VERSION ""

NS_ :

BS_:

BU_: VIU_FL AMP EDC VIU_FR TBOX IP EVCC ICDC Vector__XXX

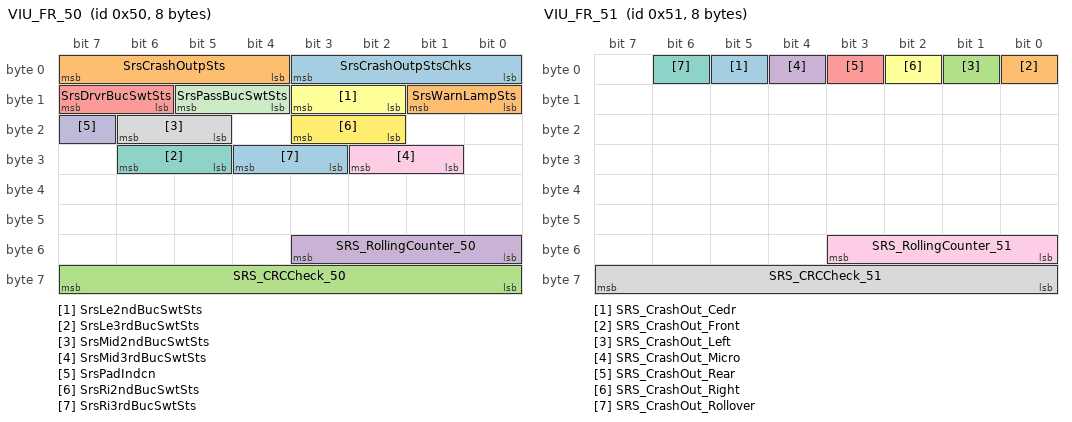
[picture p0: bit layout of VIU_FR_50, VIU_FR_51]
BO_ 80 VIU_FR_50: 8 VIU_FR
 SG_ SrsCrashOutpStsChks : 3|4@0+ (1,0) [0|15] "" EDC,TBOX
 SG_ SrsCrashOutpSts : 7|4@0+ (1,0) [0|15] "" TBOX,EDC
 SG_ SRS_CRCCheck_50 : 63|8@0+ (1,0) [0|255] "" EDC,TBOX
 SG_ SRS_RollingCounter_50 : 51|4@0+ (1,0) [0|15] "" EDC,TBOX
 SG_ SrsDrvrBucSwtSts : 15|2@0+ (1,0) [0|3] "" AMP,EDC,TBOX,IP
 SG_ SrsLe2ndBucSwtSts : 11|2@0+ (1,0) [0|3] "" AMP,EDC,TBOX,IP
 SG_ SrsLe3rdBucSwtSts : 30|2@0+ (1,0) [0|3] "" AMP,EDC,TBOX
 SG_ SrsMid2ndBucSwtSts : 22|2@0+ (1,0) [0|3] "" AMP,EDC,TBOX,IP
 SG_ SrsMid3rdBucSwtSts : 26|2@0+ (1,0) [0|3] "" AMP,EDC,TBOX
 SG_ SrsPadIndcn : 23|1@0+ (1,0) [0|1] "" EDC,TBOX
 SG_ SrsPassBucSwtSts : 13|2@0+ (1,0) [0|3] "" AMP,EDC,TBOX,IP
 SG_ SrsRi2ndBucSwtSts : 19|2@0+ (1,0) [0|3] "" AMP,EDC,TBOX,IP
 SG_ SrsRi3rdBucSwtSts : 28|2@0+ (1,0) [0|3] "" AMP,EDC,TBOX
 SG_ SrsWarnLampSts : 9|2@0+ (1,0) [0|3] "" TBOX,EDC,IP

BO_ 81 VIU_FR_51: 8 VIU_FR
 SG_ SRS_CrashOut_Cedr : 5|1@0+ (1,0) [0|1] "" EDC,TBOX
 SG_ SRS_CrashOut_Front : 0|1@0+ (1,0) [0|1] "" EDC,TBOX
 SG_ SRS_CrashOut_Left : 1|1@0+ (1,0) [0|1] "" EDC,TBOX
 SG_ SRS_CrashOut_Micro : 4|1@0+ (1,0) [0|1] "" EDC,TBOX
 SG_ SRS_CrashOut_Rear : 3|1@0+ (1,0) [0|1] "" EDC,TBOX
 SG_ SRS_CrashOut_Right : 2|1@0+ (1,0) [0|1] "" EDC,TBOX
 SG_ SRS_CrashOut_Rollover : 6|1@0+ (1,0) [0|1] "" EDC,TBOX
 SG_ SRS_CRCCheck_51 : 63|8@0+ (1,0) [0|255] "" EDC,TBOX
 SG_ SRS_RollingCounter_51 : 51|4@0+ (1,0) [0|15] "" EDC,TBOX

BO_ 338 VIU_FL_152: 64 VIU_FL
 SG_ AD_Reqmode : 89|2@0+ (1,0) [0|3] "" Vector__XXX
 SG_ AD_ACCMode : 54|3@0+ (1,0) [0|7] "" EDC,IP
 SG_ AD_AEBActive : 87|1@0+ (1,0) [0|1] "" Vector__XXX
 SG_ AD_CRCCheck_152 : 439|16@0+ (1,0) [0|65535] "" EDC
 SG_ AD_DynamicWarningLevel : 178|3@0+ (1,0) [0|7] "" EDC
 SG_ AD_ESSActive : 186|3@0+ (1,0) [0|7] "" EDC
 SG_ AD_ESSStatus : 28|3@0+ (1,0) [0|7] "" EDC
 SG_ AD_ESSWarning : 189|3@0+ (1,0) [0|7] "" EDC
 SG_ AD_FCTBActive : 37|2@0+ (1,0) [0|3] "" EDC
 SG_ AD_LatAngReq : 165|14@0+ (0.1,-720) [-720|720] "degree" Vector__XXX
 SG_ AD_LatAngReqActive : 155|1@0+ (1,0) [0|1] "" Vector__XXX
 SG_ AD_LDWinhaitwaring : 30|2@0+ (1,0) [0|3] "" EDC
 SG_ AD_LKAinhaitWarning : 93|2@0+ (1,0) [0|3] "" EDC
 SG_ AD_LKAStatus : 250|3@0+ (1,0) [0|7] "" Vector__XXX
 SG_ AD_REBStatus : 12|3@0+ (1,0) [0|7] "" EDC
 SG_ AD_RollingCounter_152 : 427|4@0+ (1,0) [0|15] "" EDC
 SG_ AD_RunRedLightWaring : 47|2@0+ (1,0) [0|3] "" EDC
 SG_ AD_SafetyNotice : 263|8@0+ (1,0) [0|255] "" EDC
 SG_ ADC_SenceMode : 131|2@0+ (1,0) [0|3] "" Vector__XXX
 SG_ AEB_AWBActive : 95|1@0+ (1,0) [0|1] "" Vector__XXX
 SG_ AD_C2Currenttemp : 151|8@0+ (1,-40) [-40|215] "" VIU_FR
 SG_ AD_FlowReq : 23|8@0+ (1,0) [0|100] "" VIU_FR
 SG_ AD_FlowReqValid : 128|1@0+ (1,0) [0|1] "" VIU_FR
 SG_ AD_TmstempReq : 143|8@0+ (1,-40) [-40|215] "" VIU_FR
 SG_ AD_TmstempReqValid : 129|1@0+ (1,0) [0|1] "" VIU_FR
 SG_ ADR_TriggerEventReq : 303|6@0+ (1,0) [0|63] "" VIU_FR

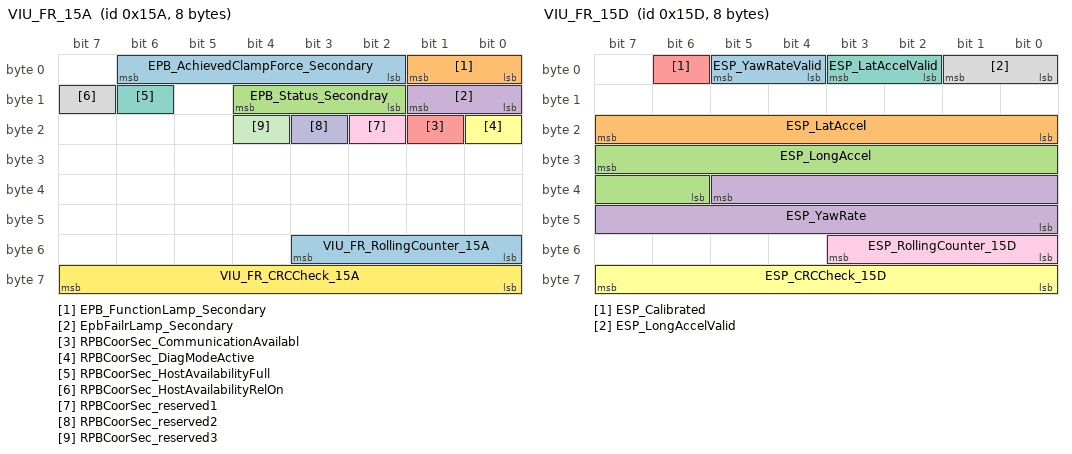
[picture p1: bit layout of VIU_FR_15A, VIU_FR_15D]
BO_ 346 VIU_FR_15A: 8 VIU_FR
 SG_ EPB_AchievedClampForce_Secondary : 6|5@0+ (1,0) [0|31] "KN" EDC
 SG_ EPB_FunctionLamp_Secondary : 1|2@0+ (1,0) [0|3] "" EDC
 SG_ EPB_Status_Secondray : 12|3@0+ (1,0) [0|7] "" EDC
 SG_ EpbFailrLamp_Secondary : 9|2@0+ (1,0) [0|3] "" EDC
 SG_ RPBCoorSec_CommunicationAvailabl : 17|1@0+ (1,0) [0|1] "bool" EDC
 SG_ RPBCoorSec_DiagModeActive : 16|1@0+ (1,0) [0|1] "bool" EDC
 SG_ RPBCoorSec_HostAvailabilityFull : 14|1@0+ (1,0) [0|1] "bool" EDC
 SG_ RPBCoorSec_HostAvailabilityRelOn : 15|1@0+ (1,0) [0|1] "bool" EDC
 SG_ RPBCoorSec_reserved1 : 18|1@0+ (1,0) [0|1] "bool" EDC
 SG_ RPBCoorSec_reserved2 : 19|1@0+ (1,0) [0|1] "bool" EDC
 SG_ RPBCoorSec_reserved3 : 20|1@0+ (1,0) [0|1] "bool" EDC
 SG_ VIU_FR_CRCCheck_15A : 63|8@0+ (1,0) [0|255] "" EDC
 SG_ VIU_FR_RollingCounter_15A : 51|4@0+ (1,0) [0|15] "" EDC

BO_ 349 VIU_FR_15D: 8 VIU_FR
 SG_ ESP_YawRateValid : 5|2@0+ (1,0) [0|3] "" TBOX,EDC
 SG_ ESP_LatAccel : 23|8@0+ (0.1,-12.7) [-12.7|12.7] "m/s2" TBOX,EDC
 SG_ ESP_LongAccel : 31|10@0+ (0.03125,-16) [-16|15.90625] "m/s2" TBOX,EDC
 SG_ ESP_YawRate : 37|14@0+ (0.01,-81.91) [-81.91|81.91] "degree/s" TBOX,EDC
 SG_ ESP_Calibrated : 6|1@0+ (1,0) [0|1] "" Vector__XXX
 SG_ ESP_CRCCheck_15D : 63|8@0+ (1,0) [0|255] "" Vector__XXX
 SG_ ESP_LatAccelValid : 3|2@0+ (1,0) [0|3] "" Vector__XXX
 SG_ ESP_LongAccelValid : 1|2@0+ (1,0) [0|3] "" Vector__XXX
 SG_ ESP_RollingCounter_15D : 51|4@0+ (1,0) [0|15] "" Vector__XXX

BO_ 353 VIU_FL_161: 32 VIU_FL
 SG_ ESPVehSpd_Reference : 68|13@0+ (0.05625,0) [0|360] "km/h" Vector__XXX
 SG_ ESP_ABAactive : 6|1@0+ (1,0) [0|1] "" TBOX,EDC
 SG_ ESP_ABAavailable : 5|1@0+ (1,0) [0|1] "" TBOX,EDC
 SG_ ESP_AEBAvailable : 2|1@0+ (1,0) [0|1] "" TBOX,EDC
 SG_ ESP_AEBdecActive : 1|1@0+ (1,0) [0|1] "" TBOX,EDC
 SG_ ESP_PrefillActive : 4|1@0+ (1,0) [0|1] "" Vector__XXX
 SG_ ESP_PrefillAvailable : 3|1@0+ (1,0) [0|1] "" Vector__XXX
 SG_ IBCU_BrakeDiscOverHeat : 14|1@0+ (1,0) [0|1] "" Vector__XXX
 SG_ IBCU_BrakeForce : 7|1@0+ (1,0) [0|1] "" Vector__XXX
 SG_ IBCU_CRCCheck_161 : 247|16@0+ (1,0) [0|65535] "" Vector__XXX
 SG_ IBCU_QDCSts : 49|2@0+ (1,0) [0|3] "" Vector__XXX
 SG_ IBCU_RollingCounter_161 : 235|4@0+ (1,0) [0|15] "" Vector__XXX

BO_ 355 VIU_FL_163: 64 VIU_FL
 SG_ DMF_BrkForceTarDecActv : 131|1@0+ (1,0) [0|1] "" Vector__XXX
 SG_ DMF_CrbsFailrSts : 357|1@0+ (1,0) [0|1] "" Vector__XXX
 SG_ DMF_BrkForceTarDec : 143|16@0+ (1,-65535) [-65535|0] "" Vector__XXX
 SG_ DMF_VehTarForceReqMod : 262|2@0+ (1,0) [0|3] "" Vector__XXX
 SG_ DMF_LeFrntTarBrkForceMod : 265|2@0+ (1,0) [0|3] "" Vector__XXX
 SG_ DMF_RiFrntTarBrkForceMod : 267|2@0+ (1,0) [0|3] "" Vector__XXX
 SG_ DMF_LeReTarBrkForceMod : 269|2@0+ (1,0) [0|3] "" Vector__XXX
 SG_ DMF_RiReTarBrkForceMod : 271|2@0+ (1,0) [0|3] "" Vector__XXX
 SG_ DMF_VehTarBrkForce : 279|16@0+ (1,-65535) [-65535|0] "" Vector__XXX
 SG_ DMF_LeFrntTarBrkForce : 295|16@0+ (1,-65535) [-65535|0] "" Vector__XXX
 SG_ DMF_RiFrntTarBrkForce : 311|16@0+ (1,-65535) [-65535|0] "" Vector__XXX
 SG_ DMF_LeReTarBrkForce : 327|16@0+ (1,-65535) [-65535|0] "" Vector__XXX
 SG_ DMF_RiReTarBrkForce : 343|16@0+ (1,-65535) [-65535|0] "" Vector__XXX
 SG_ DMF_MainAdasSts : 43|1@0+ (1,0) [0|1] "" Vector__XXX
 SG_ DMF_EscFctSts : 134|3@0+ (1,0) [1|7] "" Vector__XXX
 SG_ DMF_PrefillActvReq : 260|1@0+ (1,0) [0|1] "" Vector__XXX
 SG_ DMF_ReWhlDecTarTqActv : 28|1@0+ (1,0) [0|1] "" Vector__XXX
 SG_ DMF_ReWhlDecTarTq : 27|16@0+ (1,-32768) [-32768|32767] "Nm" Vector__XXX
 SG_ DMF_ReWhlIncTarTqActv : 13|1@0+ (1,0) [0|1] "" Vector__XXX
 SG_ DMF_ReWhlIncTarTq : 12|16@0+ (1,-32768) [-32768|32767] "Nm" Vector__XXX
 SG_ DMF_FrntWhlDecTarTqActv : 0|1@0+ (1,0) [0|1] "" Vector__XXX
 SG_ DMF_FrntWhlDecTarTq : 71|16@0+ (1,-32768) [-32768|32767] "Nm" Vector__XXX
 SG_ DMF_FrntWhlIncTarTqActv : 1|1@0+ (1,0) [0|1] "" Vector__XXX
 SG_ DMF_FrntWhlIncTarTq : 87|16@0+ (1,-32768) [-32768|32767] "Nm" Vector__XXX
 SG_ DMF_LeFrntWhlIncTarTqActv : 2|1@0+ (1,0) [0|1] "" Vector__XXX
 SG_ DMF_LeFrntWhlIncTarTq : 103|16@0+ (1,-32768) [-32768|32767] "Nm" Vector__XXX
 SG_ DMF_RiFrntWhlIncTarTqActv : 3|1@0+ (1,0) [0|1] "" Vector__XXX
 SG_ DMF_RiFrntWhlIncTarTq : 119|16@0+ (1,-32768) [-32768|32767] "Nm" Vector__XXX
 SG_ DMF_LeReWhlIncTarTqActv : 4|1@0+ (1,0) [0|1] "" Vector__XXX
 SG_ DMF_LeReWhlIncTarTq : 159|16@0+ (1,-32768) [-32768|32767] "Nm" Vector__XXX
 SG_ DMF_RiReWhlIncTarTqActv : 5|1@0+ (1,0) [0|1] "" Vector__XXX
 SG_ DMF_RiReWhlIncTarTq : 175|16@0+ (1,-32768) [-32768|32767] "Nm" Vector__XXX
 SG_ DMF_LeFrntWhlDecTarTqActv : 6|1@0+ (1,0) [0|1] "" Vector__XXX
 SG_ DMF_LeFrntWhlDecTarTq : 191|16@0+ (1,-32768) [-32768|32767] "Nm" Vector__XXX
 SG_ DMF_RiFrntWhlDecTarTqActv : 7|1@0+ (1,0) [0|1] "" Vector__XXX
 SG_ DMF_RiFrntWhlDecTarTq : 207|16@0+ (1,-32768) [-32768|32767] "Nm" Vector__XXX
 SG_ DMF_LeReWhlDecTarTqActv : 14|1@0+ (1,0) [0|1] "" Vector__XXX
 SG_ DMF_LeReWhlDecTarTq : 223|16@0+ (1,-32768) [-32768|32767] "Nm" Vector__XXX
 SG_ DMF_RiReWhlDecTarTqActv : 15|1@0+ (1,0) [0|1] "" Vector__XXX
 SG_ DMF_RiReWhlDecTarTq : 239|16@0+ (1,-32768) [-32768|32767] "Nm" Vector__XXX
 SG_ DMF_ADReqmode : 250|2@0+ (1,0) [0|3] "" Vector__XXX
 SG_ DMF_ADDriverlessReq : 256|1@0+ (1,0) [0|1] "" Vector__XXX
 SG_ DMF_ADAbaRankReq : 359|2@0+ (1,0) [0|3] "" Vector__XXX
 SG_ DMF_ADAbaRankReqVld : 248|1@0+ (1,0) [0|1] "" Vector__XXX
 SG_ DMF_ADSystemSts : 252|2@0+ (1,0) [0|3] "" Vector__XXX
 SG_ DMF_ADFctOpenSts : 259|2@0+ (1,0) [0|3] "" Vector__XXX
 SG_ DmfEscReqRwsActv : 472|1@0+ (1,0) [0|1] "" Vector__XXX
 SG_ DmfEscRwsAgTar : 42|12@0+ (0.01,-15) [-15|15] "deg" Vector__XXX
 SG_ DmfDstwWhlAgOff : 452|8@0+ (0.1,-10) [-10|10] "deg" Vector__XXX
 SG_ DmfDstwActvSts : 467|1@0+ (1,0) [0|1] "" Vector__XXX
 SG_ DmfFrntWhlAg : 356|10@0+ (0.1,-45) [-45|45] "deg" Vector__XXX
 SG_ DmfLgtSlopEst : 466|10@0+ (0.01,-3) [-3|3] "m/ss" Vector__XXX
 SG_ DmfMueEstFil : 409|5@0+ (0.05,0) [0|1.5] "" Vector__XXX
 SG_ Dmf_RollingCounter_163 : 491|4@0+ (1,0) [0|15] "" Vector__XXX
 SG_ Dmf_CRCCheck_163 : 503|16@0+ (1,0) [0|65535] "" Vector__XXX

BO_ 359 VIU_FL_167: 64 VIU_FL
 SG_ EmsEngSpd : 23|16@0+ (0.25,0) [0|16383.75] "rpm" EDC
 SG_ EmsEngCoolanT : 143|8@0+ (0.75,-48) [-48|142.5] "℃" IP
 SG_ EmsCoolanTErr : 122|1@0+ (1,0) [0|1] "" IP

BO_ 378 VIU_FL_17A: 64 VIU_FL
 SG_ IbBrkPedlStsGb : 199|8@0+ (1,0) [0|255] "%" TBOX
 SG_ IbBrkPedlStsGbVld : 201|2@0+ (1,0) [0|2] "" TBOX
 SG_ IbBrkPedlTrvlDrvr : 239|12@0+ (0.015625,-5) [-5|47] "mm" TBOX
 SG_ IbBrkPedlTrvlDrvrVld : 217|2@0+ (1,0) [0|2] "" TBOX
 SG_ ESP_pMcVirtual : 243|12@0+ (0.1,0) [0|250] "bar" Vector__XXX
 SG_ IBCU_PlungerBrakePressure : 19|12@0+ (0.1,0) [0|250] "bar" Vector__XXX
 SG_ IBCU_PlungerBrakePressureValid : 39|1@0+ (1,0) [0|1] "" Vector__XXX

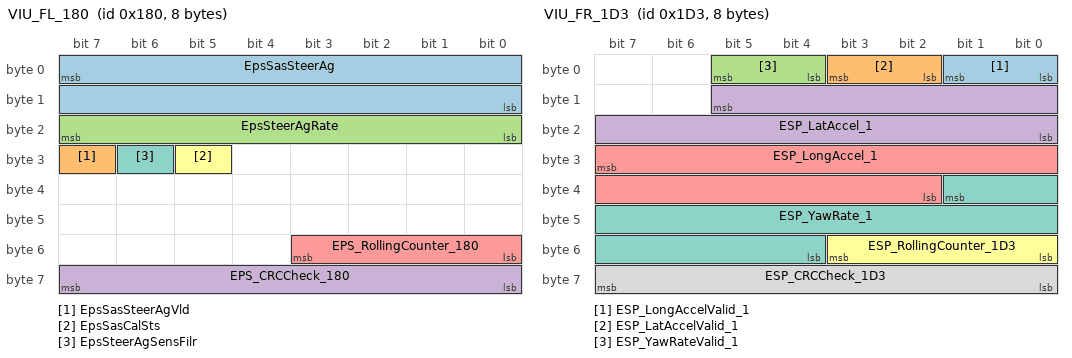
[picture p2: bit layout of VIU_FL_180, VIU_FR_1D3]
BO_ 384 VIU_FL_180: 8 VIU_FL
 SG_ EpsSasSteerAg : 7|16@0- (0.1,0) [-780|780] "degree" TBOX
 SG_ EpsSasSteerAgVld : 31|1@0+ (1,0) [0|1] "" TBOX
 SG_ EpsSteerAgRate : 23|8@0+ (4,0) [0|1016] "deg/s" Vector__XXX
 SG_ EPS_CRCCheck_180 : 63|8@0+ (1,0) [0|255] "" Vector__XXX
 SG_ EPS_RollingCounter_180 : 51|4@0+ (1,0) [0|15] "" Vector__XXX
 SG_ EpsSasCalSts : 29|1@0+ (1,0) [0|1] "" Vector__XXX
 SG_ EpsSteerAgSensFilr : 30|1@0+ (1,0) [0|1] "" Vector__XXX

BO_ 417 VIU_FL_1A1: 64 VIU_FL
 SG_ VcuChrglockPosn2 : 402|1@0+ (1,0) [0|1] "" EVCC
 SG_ VcuChrglockPosn1 : 403|1@0+ (1,0) [0|1] "" EVCC

BO_ 419 VIU_FL_1A3: 64 VIU_FL
 SG_ FrntMotSpd : 7|16@0+ (1,-20000) [-20000|45535] "rpm" EDC,AMP
 SG_ FrntMotTqGb : 319|16@0+ (0.1,-2000) [-2000|4553.5] "Nm" EDC,AMP
 SG_ FrntMotSpdVld : 34|1@0+ (1,0) [0|1] "" EDC
 SG_ FrntMotTq : 23|14@0+ (0.1,-800) [-800|838.3] "Nm" EDC,AMP
 SG_ FrntMotTqVld : 33|1@0+ (1,0) [0|1] "" EDC,AMP

BO_ 420 VIU_FL_1A4: 64 VIU_FL
 SG_ ReMotSpd : 7|16@0+ (1,-20000) [-20000|45535] "rpm" EDC,AMP
 SG_ ReMotSpdVld : 34|1@0+ (1,0) [0|1] "" EDC,AMP
 SG_ ReMotTq : 23|14@0+ (0.1,-800) [-800|838.3] "Nm" EDC,AMP
 SG_ ReMotTqVld : 33|1@0+ (1,0) [0|1] "" EDC,AMP

BO_ 421 VIU_FL_1A5: 64 VIU_FL
 SG_ BcuChrgMod : 217|4@0+ (1,0) [0|15] "" EVCC

BO_ 433 VIU_FL_1B1: 64 VIU_FL
 SG_ PwrTrainSts : 311|2@0+ (1,0) [0|3] "" Vector__XXX
 SG_ VcuRdySts : 7|1@0+ (1,0) [0|1] "" IP,EDC
 SG_ VcuGearPosn : 5|3@0+ (1,0) [0|7] "" TBOX,EDC,AMP,EVCC
 SG_ VcuVehGearPosnVld : 2|1@0+ (1,0) [0|1] "" TBOX,EDC,AMP,IP,EVCC
 SG_ AcChrgHvActvReq : 359|3@0+ (1,0) [0|7] "NA" Vector__XXX
 SG_ DcAcHvActvReq : 355|3@0+ (1,0) [0|7] "NA" Vector__XXX
 SG_ DcChrgHvActvReq : 370|3@0+ (1,0) [0|7] "NA" Vector__XXX
 SG_ OTAHvActvReq : 365|3@0+ (1,0) [0|7] "NA" Vector__XXX
 SG_ SrvAllwblReqSts : 352|3@0+ (1,0) [0|7] "NA" Vector__XXX
 SG_ VcuHvSysErrNr : 362|8@0+ (1,0) [0|255] "NA" Vector__XXX
 SG_ VehHvActvReq : 347|3@0+ (1,0) [0|7] "NA" Vector__XXX
 SG_ BrkgRgnMaxWhl : 271|16@0+ (1,-32768) [-32768|32767] "Nm" Vector__XXX
 SG_ BrkgRgnMaxWhlVldSts : 285|2@0+ (1,0) [0|2] "" Vector__XXX
 SG_ LePresSw : 177|3@0+ (1,0) [0|7] "" Vector__XXX
 SG_ ReMotSpd : 167|16@0+ (1,-20000) [-20000|45535] "rpm" Vector__XXX
 SG_ ReMotSpdVld : 182|1@0+ (1,0) [0|1] "" Vector__XXX
 SG_ RiPresSw : 190|3@0+ (1,0) [0|7] "" EDC
 SG_ VCU_CRCCheck_1B1 : 439|16@0+ (1,0) [0|65535] "" Vector__XXX
 SG_ VCU_RollingCounter_1B1 : 427|4@0+ (1,0) [0|15] "" Vector__XXX
 SG_ VCUAccPedShield : 50|1@0+ (1,0) [0|1] "" Vector__XXX
 SG_ VcuAccrMod : 199|4@0+ (1,0) [0|15] "" IP
 SG_ VcuAccrPedlPosn : 195|10@0+ (0.1,0) [0|102.3] "%" AMP,EDC
 SG_ VcuAccrPedlPosnVld : 216|1@0+ (1,0) [0|1] "" AMP
 SG_ VCUAPAdriverInterruption : 49|2@0+ (1,0) [0|3] "" Vector__XXX
 SG_ VCUAPARequestEnable : 57|2@0+ (1,0) [0|3] "" Vector__XXX
 SG_ VcuCalcnAccrPedlPosn : 201|10@0+ (0.1,0) [0|102.3] "%" Vector__XXX
 SG_ VcuCalcnAccrPedlPosnVld : 217|1@0+ (1,0) [0|1] "" Vector__XXX
 SG_ VcuComFltSts : 1|2@0+ (1,0) [0|3] "" Vector__XXX
 SG_ VcuCrpFctSts : 241|2@0+ (1,0) [0|3] "" Vector__XXX
 SG_ VcuDecToStopReq : 238|1@0+ (1,0) [0|1] "" Vector__XXX
 SG_ VcuDrvrGearDmd : 180|3@0+ (1,0) [0|7] "" Vector__XXX
 SG_ VcuEnyRecyclMod : 283|7@0+ (1,0) [0|127] "" Vector__XXX
 SG_ VcuEpbReq : 223|2@0+ (1,0) [0|3] "" Vector__XXX
 SG_ VcuEpbReqVld : 224|1@0+ (1,0) [0|1] "" Vector__XXX
 SG_ VcuFrntMotSpd : 151|16@0+ (1,-20000) [-20000|45535] "rpm" Vector__XXX
 SG_ VcuFrntMotSpdVld : 184|1@0+ (1,0) [0|1] "" Vector__XXX
 SG_ VcuFrntWhlActTq : 23|16@0+ (1,-32768) [-32768|32767] "Nm" Vector__XXX
 SG_ VcuFrntWhlActTqVld : 8|1@0+ (1,0) [0|1] "" Vector__XXX
 SG_ VcuFrntWhlReqTq : 71|16@0+ (1,-32768) [-32768|32767] "Nm" Vector__XXX
 SG_ VcuFrntWhlReqTqVld : 11|1@0+ (1,0) [0|1] "" Vector__XXX
 SG_ VcuMbRgnWhl : 255|16@0+ (1,-32768) [-32768|32767] "Nm" Vector__XXX
 SG_ VcuMbRgnWhlVldSts : 287|2@0+ (1,0) [0|2] "" Vector__XXX
 SG_ VcuObdType : 239|1@0+ (1,0) [0|1] "" Vector__XXX
 SG_ VcuOvrdModReq : 6|1@0+ (1,0) [0|1] "" Vector__XXX
 SG_ VcuPmuSleepReq : 53|1@0+ (1,0) [0|1] "" Vector__XXX
 SG_ VcuPmuSwtCloseAllowFlg : 55|1@0+ (1,0) [0|1] "" Vector__XXX
 SG_ VcuPtCoastRegenReqTq : 135|16@0+ (1,-32768) [-32768|32767] "Nm" Vector__XXX
 SG_ VcuPtCoastRegenReqTqVld : 15|1@0+ (1,0) [0|1] "" Vector__XXX
 SG_ VcuPtTqLimMax : 119|16@0+ (1,-32768) [-32768|32767] "Nm" Vector__XXX
 SG_ VcuPtTqLimMaxVld : 14|1@0+ (1,0) [0|1] "" Vector__XXX
 SG_ VcuPtTqLimMin : 103|16@0+ (1,-32768) [-32768|32767] "Nm" Vector__XXX
 SG_ VcuPtTqLimMinVld : 13|1@0+ (1,0) [0|1] "" Vector__XXX
 SG_ VcuPtTqReal : 323|16@0+ (1,-32768) [-32768|32767] "Nm" Vector__XXX
 SG_ VcuPtTqRealVld : 308|1@0+ (1,0) [0|1] "" Vector__XXX
 SG_ VcuPtTqReqAvl : 52|2@0+ (1,0) [0|3] "" Vector__XXX
 SG_ VcuReWhlActTq : 39|16@0+ (1,-32768) [-32768|32767] "Nm" Vector__XXX
 SG_ VcuReWhlActTqVld : 9|1@0+ (1,0) [0|1] "" Vector__XXX
 SG_ VcuReWhlReqTq : 87|16@0+ (1,-32768) [-32768|32767] "Nm" Vector__XXX
 SG_ VcuReWhlReqTqVld : 12|1@0+ (1,0) [0|1] "" Vector__XXX
 SG_ VcuSimnEpbSwtSts : 233|2@0+ (1,0) [0|3] "" Vector__XXX
 SG_ VcuSimnEpbSwtStsVld : 234|1@0+ (1,0) [0|1] "" Vector__XXX
 SG_ VcuTarGearPosn : 237|3@0+ (1,0) [0|7] "" Vector__XXX
 SG_ VcuTrlrModActvSts : 243|2@0+ (1,0) [0|3] "" Vector__XXX
 SG_ VcuVechicleType : 245|2@0+ (1,0) [0|3] "" Vector__XXX
 SG_ VcuVehWhlReqTq : 307|16@0+ (1,-32768) [-32768|32767] "Nm" Vector__XXX
 SG_ VcuVehWhlReqTqVld : 309|1@0+ (1,0) [0|1] "" Vector__XXX

BO_ 450 VIU_FL_1C2: 64 VIU_FL
 SG_ EspAbsActv : 72|1@0+ (1,0) [0|1] "" TBOX,IP,VIU_FR
 SG_ EspAbsFailr : 73|1@0+ (1,0) [0|1] "" TBOX,IP
 SG_ EspActvSts : 55|1@0+ (1,0) [0|1] "" TBOX,IP
 SG_ EspFctOpenSts : 54|1@0+ (1,0) [0|1] "" TBOX,IP
 SG_ EspTcsActvSts : 52|1@0+ (1,0) [0|1] "" TBOX,IP
 SG_ EspTcsFailr : 53|1@0+ (1,0) [0|1] "" TBOX,IP
 SG_ EspVehSpd : 100|13@0+ (0.05625,0) [0|460.74375] "km/h" EDC,TBOX,AMP,IP,EVCC
 SG_ EspVehSpdVld : 101|1@0+ (1,0) [0|1] "" EDC,TBOX,AMP,IP,EVCC
 SG_ EspDrvrBrkReqTq : 319|16@0+ (1,-32768) [-32768|32767] "Nm" Vector__XXX
 SG_ ESP_CRCCheck_1C2 : 439|16@0+ (1,0) [0|65535] "" Vector__XXX
 SG_ ESP_RollingCounter_1C2 : 427|4@0+ (1,0) [0|15] "" Vector__XXX
 SG_ EspEbdFailr : 36|1@0+ (1,0) [0|1] "" IP
 SG_ EspHDCSts : 365|2@0+ (1,0) [0|3] "" IP
 SG_ EspVdcActvSts : 414|1@0+ (1,0) [0|1] "" IP
 SG_ EspVehStandstill : 351|1@0+ (1,0) [0|1] "" Vector__XXX
 SG_ IBCU_BrakeFluid_Warning : 6|2@0+ (1,0) [0|3] "" Vector__XXX
 SG_ MCBActv : 103|1@0+ (1,0) [0|1] "" EDC
 SG_ MCBAvl : 102|1@0+ (1,0) [0|1] "" EDC
 SG_ WhlSpdFrntLePls : 63|8@0+ (1,0) [0|254] "" Vector__XXX
 SG_ WhlSpdFrntRiPls : 239|8@0+ (1,0) [0|254] "" Vector__XXX
 SG_ WhlSpdLeFrntData : 148|13@0+ (0.05625,0) [0|460.74375] "km/h" Vector__XXX
 SG_ WhlSpdLeFrntDataVld : 151|1@0+ (1,0) [0|1] "" Vector__XXX
 SG_ WhlSpdLeFrntDir : 150|2@0+ (1,0) [0|3] "" Vector__XXX
 SG_ WhlSpdLeReData : 20|13@0+ (0.05625,0) [0|460.74375] "km/h" Vector__XXX
 SG_ WhlSpdLeReDataVld : 23|1@0+ (1,0) [0|1] "" Vector__XXX
 SG_ WhlSpdLeReDir : 67|2@0+ (1,0) [0|3] "" Vector__XXX
 SG_ WhlSpdReLePls : 263|8@0+ (1,0) [0|254] "" Vector__XXX
 SG_ WhlSpdReRiPls : 407|8@0+ (1,0) [0|254] "" Vector__XXX
 SG_ WhlSpdRiFrntData : 132|13@0+ (0.05625,0) [0|460.74375] "km/h" Vector__XXX
 SG_ WhlSpdRiFrntDataVld : 135|1@0+ (1,0) [0|1] "" Vector__XXX
 SG_ WhlSpdRiFrntDir : 134|2@0+ (1,0) [0|3] "" Vector__XXX
 SG_ WhlSpdRiReData : 4|13@0+ (0.05625,0) [0|460.74375] "km/h" Vector__XXX
 SG_ WhlSpdRiReDataVld : 7|1@0+ (1,0) [0|1] "" Vector__XXX
 SG_ WhlSpdRiReDir : 65|2@0+ (1,0) [0|3] "" Vector__XXX
 SG_ EspAutoHoldActvSts : 353|2@0+ (1,0) [0|3] "" IP
 SG_ EspBrkSysFltLamp : 35|2@0+ (1,0) [0|3] "" IP
 SG_ IBCU_iDCSAvlblSts : 211|1@0+ (1,0) [0|1] "" EDC
 SG_ IBCU_iDCSLevFd : 210|3@0+ (1,0) [0|7] "" EDC
 SG_ IBCU_iDCS_State : 303|3@0+ (1,0) [0|7] "" EDC

BO_ 452 VIU_FL_1C4: 8 VIU_FL
 SG_ EMB_Pri_SystemFlt : 7|4@0+ (1,0) [0|15] "" VIU_FR
 SG_ EMB_Pri_BrkRodStrk : 3|12@0+ (0.03,0) [0|100] "mm" VIU_FR
 SG_ EMB_Pri_BrkRodStrkVld : 23|1@0+ (1,0) [0|1] "" VIU_FR
 SG_ EMB_RollingCounter_1C4 : 51|4@0+ (1,0) [0|15] "" VIU_FR
 SG_ EMB_CRCCheck__1C4 : 63|8@0+ (1,0) [0|255] "" VIU_FR
 SG_ EMBParkPriCtrlEnableRL : 22|1@0+ (1,0) [0|1] "" VIU_FR
 SG_ EMBParkPriCtrlEnableRR : 21|1@0+ (1,0) [0|1] "" VIU_FR
 SG_ EMBParkPriAvailabilityRL : 20|2@0+ (1,0) [0|3] "" VIU_FR
 SG_ EMBParkPriAvailabilityRR : 18|2@0+ (1,0) [0|3] "" VIU_FR
 SG_ EMBParkPriCtrlSourceRL : 16|4@0+ (1,0) [0|15] "" VIU_FR
 SG_ EMBParkPriCtrlSourceRR : 28|4@0+ (1,0) [0|15] "" VIU_FR
 SG_ EMBParkPriEpbStatusRL : 24|3@0+ (1,0) [0|7] "" VIU_FR
 SG_ EMBParkPriEpbStatusRR : 37|3@0+ (1,0) [0|7] "" VIU_FR
 SG_ EMBParkPriFctLampRL : 34|2@0+ (1,0) [0|3] "" VIU_FR
 SG_ EMBParkPriFctLampRR : 32|2@0+ (1,0) [0|3] "" VIU_FR
 SG_ EMBParkPriFailrLampRL : 46|2@0+ (1,0) [0|3] "" VIU_FR
 SG_ EMBParkPriFailrLampRR : 44|2@0+ (1,0) [0|3] "" VIU_FR
 SG_ EMBPriVehBrkSysSts : 42|3@0+ (1,0) [0|7] "" VIU_FR

BO_ 453 VIU_FR_1C5: 8 VIU_FR
 SG_ EMB_Sec_SystemFlt : 7|4@0+ (1,0) [0|15] "" VIU_FL
 SG_ EMB_Sec_BrkRodStrk : 3|12@0+ (0.03,0) [0|100] "mm" VIU_FL
 SG_ EMB_Sec_BrkRodStrkVld : 23|1@0+ (1,0) [0|1] "" VIU_FL
 SG_ EMB_RollingCounter_1C5 : 51|4@0+ (1,0) [0|15] "" VIU_FL
 SG_ EMB_CRCCheck__1C5 : 63|8@0+ (1,0) [0|255] "" VIU_FL
 SG_ EMBParkSecCtrlEnableRL : 22|1@0+ (1,0) [0|1] "" VIU_FL
 SG_ EMBParkSecCtrlEnableRR : 21|1@0+ (1,0) [0|1] "" VIU_FL
 SG_ EMBParkSecAvailabilityRL : 20|2@0+ (1,0) [0|3] "" VIU_FL
 SG_ EMBParkSecAvailabilityRR : 18|2@0+ (1,0) [0|3] "" VIU_FL
 SG_ EMBParkSecCtrlSourceRL : 16|4@0+ (1,0) [0|15] "" VIU_FL
 SG_ EMBParkSecCtrlSourceRR : 28|4@0+ (1,0) [0|15] "" VIU_FL
 SG_ EMBParkSecEpbStatusRL : 24|3@0+ (1,0) [0|7] "" VIU_FL
 SG_ EMBParkSecEpbStatusRR : 37|3@0+ (1,0) [0|7] "" VIU_FL
 SG_ EMBParkSecFctLampRL : 34|2@0+ (1,0) [0|3] "" VIU_FL
 SG_ EMBParkSecFctLampRR : 32|2@0+ (1,0) [0|3] "" VIU_FL
 SG_ EMBParkSecFailrLampRL : 46|2@0+ (1,0) [0|3] "" VIU_FL
 SG_ EMBParkSecFailrLampRR : 44|2@0+ (1,0) [0|3] "" VIU_FL
 SG_ EMBSecVehBrkSysSts : 42|3@0+ (1,0) [0|7] "" VIU_FL

BO_ 467 VIU_FR_1D3: 8 VIU_FR
 SG_ ESP_LongAccelValid_1 : 1|2@0+ (1,0) [0|3] "" VIU_FL
 SG_ ESP_LatAccelValid_1 : 3|2@0+ (1,0) [0|3] "" VIU_FL
 SG_ ESP_YawRateValid_1 : 5|2@0+ (1,0) [0|3] "" VIU_FL
 SG_ ESP_LatAccel_1 : 13|14@0+ (0.01,-49.9) [-49.9|49.9] "m/s2" VIU_FL
 SG_ ESP_LongAccel_1 : 31|14@0+ (0.01,-49.9) [-49.9|49.9] "m/s2" VIU_FL
 SG_ ESP_RollingCounter_1D3 : 51|4@0+ (1,0) [0|15] "" VIU_FL
 SG_ ESP_YawRate_1 : 33|14@0+ (0.01,-81.91) [-81.91|81.91] "degree/s" VIU_FL
 SG_ ESP_CRCCheck_1D3 : 63|8@0+ (1,0) [0|255] "" VIU_FL

BO_ 500 VIU_FL_1F4: 64 VIU_FL
 SG_ FrntGerTq : 23|14@0+ (0.1,-800) [-800|838.3] "Nm" AMP,EDC

BO_ 513 VIU_FL_201: 8 VIU_FL
 SG_ AD_DDSATextInfo : 21|2@0+ (1,0) [0|3] "" EDC
 SG_ ADS_AcrBeltShake : 39|2@0+ (1,0) [0|3] "" VIU_FR

BO_ 642 EVCC_282: 64 EVCC
 SG_ CPEVTar_v2g_SupAppResSchemaID : 175|6@0+ (1,0) [0|20] "Id" VIU_FL
 SG_ CPEVTar_v2g_CurDemResReCnt : 169|2@0+ (1,0) [0|3] "cnt" VIU_FL
 SG_ Switch_S2_State : 85|1@0+ (1,0) [0|1] "flg" VIU_FL
 SG_ Switch_K3_State : 86|1@0+ (1,0) [0|1] "flg" VIU_FL
 SG_ Switch_CC2_State : 87|1@0+ (1,0) [0|1] "flg" VIU_FL
 SG_ App_Version_V : 84|8@0+ (1,0) [0|255] "" VIU_FL
 SG_ App_Version_D : 100|8@0+ (1,0) [0|255] "" VIU_FL
 SG_ App_Version_B : 92|8@0+ (1,0) [0|255] "" VIU_FL
 SG_ Eu_ChargingStage : 108|8@0+ (1,0) [0|108] "" VIU_FL
 SG_ Gb_ChargingState : 116|8@0+ (1,0) [0|255] "" VIU_FL
 SG_ Gb_ChargingEvent : 124|8@0+ (1,0) [0|24] "" VIU_FL
 SG_ KL30voltage : 191|16@0+ (1,0) [0|65535] "mV" VIU_FL
 SG_ KL15voltage : 207|16@0+ (1,0) [0|65535] "mV" VIU_FL
 SG_ K3voltage : 223|16@0+ (1,0) [0|65535] "mV" VIU_FL
 SG_ ComPam1_v2g_DC_EVSs_EVErrCd : 148|7@0+ (1,0) [0|11] "" VIU_FL
 SG_ CPEVSEVol_v2g_DC_EVSESsCd : 155|4@0+ (1,0) [0|11] "" VIU_FL
 SG_ ComPam1_v2g_ResponseCode : 140|8@0+ (1,0) [0|25] "" VIU_FL
 SG_ CPEVSEVol_v2g_DCEVSEIsolSs : 167|3@0+ (1,0) [0|4] "" VIU_FL
 SG_ CPEVSECur_v2g_EVSEProc : 164|2@0+ (1,0) [0|2] "" VIU_FL
 SG_ CPEVSEPre_v2g_ChgProg : 162|2@0+ (1,0) [0|1] "" VIU_FL
 SG_ chgpam4_v2g_res_procID1 : 183|8@0+ (1,0) [0|255] "" VIU_FL
 SG_ EVCC_ChargingActionCode : 132|8@0+ (1,0) [0|255] "" VIU_FL
 SG_ EVCC_CP_State : 55|8@0+ (1,0) [0|3] "" VIU_FL
 SG_ EVCC_CP_DutyChange : 59|4@0+ (1,0) [0|4] "" VIU_FL
 SG_ EVCC_CP_Duty : 23|16@0+ (0.01,0) [0|655.35] "%" VIU_FL
 SG_ EVCC_CP_Freq : 39|16@0+ (1,0) [0|65535] "Hz" VIU_FL
 SG_ EVCC_CP_VoltageChange : 63|4@0+ (1,0) [0|8] "" VIU_FL
 SG_ EVCC_CP_Voltage : 7|16@0+ (1,0) [0|65535] "mV" VIU_FL
 SG_ CPEVSEVol_v2g_MessSet : 157|2@0+ (1,0) [0|3] "" VIU_FL
 SG_ EVCC_CC2_Voltage : 71|16@0+ (1,0) [0|65535] "Ω" VIU_FL
 SG_ CPEVTar_v2g_ChgComplete : 160|1@0+ (1,0) [0|1] "flg" VIU_FL
 SG_ EvccS2Sts : 239|1@0+ (1,0) [0|1] "" VIU_FL
 SG_ EVCC_RollingCounter_282 : 491|4@0+ (1,0) [0|15] "" VIU_FL
 SG_ EVCC_CRCCheck_282 : 503|16@0+ (1,0) [0|65535] "" VIU_FL

BO_ 648 VIU_FL_288: 8 VIU_FL
 SG_ ActualDrvMod : 55|4@0+ (1,0) [0|15] "" EDC
 SG_ BCM_DrivDoorLockSts : 26|3@0+ (1,0) [0|7] "" Vector__XXX
 SG_ BCM_HoodStatus : 18|1@0+ (1,0) [0|1] "" IP
 SG_ BCM_TurnLightSwitchSts : 1|2@0+ (1,0) [0|3] "" Vector__XXX
 SG_ BcmAuLiSwtSts : 11|1@0+ (1,0) [0|1] "" Vector__XXX
 SG_ BcmDrvrDoorSts : 23|1@0+ (1,0) [0|1] "" EDC,AMP,IP,VIU_FR
 SG_ BcmEmgyLiSts : 37|2@0+ (1,0) [0|3] "" Vector__XXX
 SG_ BcmHiBeSwtSts : 35|1@0+ (1,0) [0|1] "" Vector__XXX
 SG_ BcmKeyAlrmSts : 10|2@0+ (1,0) [0|3] "" Vector__XXX
 SG_ BcmLeReDoorSts : 21|1@0+ (1,0) [0|1] "" EDC,AMP,IP
 SG_ BcmLoBeSwtSts : 29|1@0+ (1,0) [0|1] "" Vector__XXX
 SG_ BcmOvTaLiSwtSts : 22|1@0+ (1,0) [0|1] "" Vector__XXX
 SG_ BcmPassDoorSts : 7|1@0+ (1,0) [0|1] "" EDC,AMP,IP
 SG_ BcmPwrStsFb : 43|2@0+ (1,0) [0|3] "" EDC,TBOX,AMP,EVCC,IP
 SG_ BcmRiReDoorSts : 8|1@0+ (1,0) [0|1] "" EDC,AMP,IP
 SG_ BcmTurnIndcrLe : 15|2@0+ (1,0) [0|3] "" IP
 SG_ BcmTurnIndcrRi : 13|2@0+ (1,0) [0|3] "" IP
 SG_ BdcDrvrSts : 38|1@0+ (1,0) [0|1] "" IP,EDC
 SG_ LoChrgSts : 41|2@0+ (1,0) [0|3] "" EDC
 SG_ VIU_DriverADEDSts : 39|1@0+ (1,0) [0|1] "" Vector__XXX
 SG_ VIU_FL_CRCCheck_288 : 63|8@0+ (1,0) [0|255] "" Vector__XXX
 SG_ VIU_FL_RollingCounter_288 : 51|4@0+ (1,0) [0|15] "" Vector__XXX
 SG_ VIU_PassengerADEDSts : 31|1@0+ (1,0) [0|1] "" Vector__XXX
 SG_ VIUACModReq : 46|3@0+ (1,0) [0|7] "" Vector__XXX
 SG_ WakeUpForbidden : 30|1@0+ (1,0) [0|1] "" Vector__XXX

BO_ 674 VIU_FR_2A2: 8 VIU_FR
 SG_ ACP_ActualSpeed : 7|16@0+ (1,0) [0|65534] "rpm" AMP,EDC

BO_ 677 VIU_FL_2A5: 64 VIU_FL
 SG_ BcuSocDisp : 7|10@0+ (0.1,0) [0|102.3] "%" EDC,IP
 SG_ BcuBattHeatActv : 77|2@0+ (1,0) [0|3] "" IP
 SG_ DcChrgCnctrSts : 307|3@0+ (1,0) [0|7] "" EVCC

BO_ 680 VIU_FL_2A8: 64 VIU_FL
 SG_ TmsAcEnvtlT : 39|8@0+ (0.5,-40) [-40|87.5] "℃" IP
 SG_ TmsAcEnvtlTVld : 432|1@0+ (1,0) [0|1] "" IP
 SG_ TmsAcpActSpd : 271|16@0+ (1,0) [0|65535] "rpm" EDC,AMP
 SG_ TmsAcpActPwr : 263|8@0+ (0.1,0) [0|25.5] "kW" EDC,AMP

BO_ 681 VIU_FL_2A9: 64 VIU_FL
 SG_ ObcS2Ctrl : 466|1@0+ (1,0) [0|1] "" EVCC
 SG_ Obc_CRCCheck_2A9 : 503|16@0+ (1,0) [0|65535] "" EVCC
 SG_ Obc_RollingCounter_2A9 : 491|4@0+ (1,0) [0|15] "" EVCC

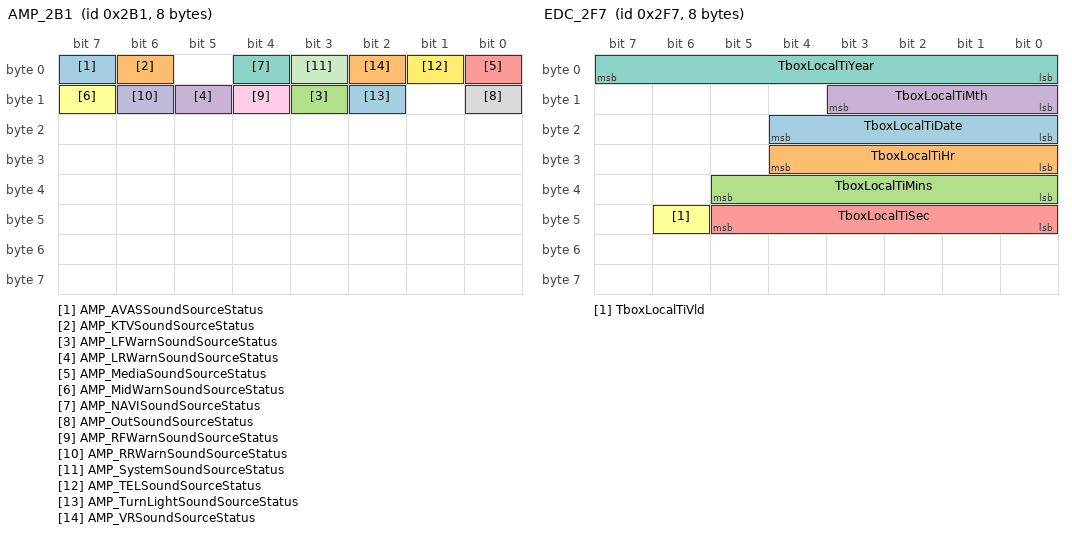
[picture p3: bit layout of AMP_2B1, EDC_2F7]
BO_ 689 AMP_2B1: 8 AMP
 SG_ AMP_AVASSoundSourceStatus : 7|1@0+ (1,0) [0|1] "" EDC
 SG_ AMP_KTVSoundSourceStatus : 6|1@0+ (1,0) [0|1] "" EDC
 SG_ AMP_LFWarnSoundSourceStatus : 11|1@0+ (1,0) [0|1] "" EDC
 SG_ AMP_LRWarnSoundSourceStatus : 13|1@0+ (1,0) [0|1] "" EDC
 SG_ AMP_MediaSoundSourceStatus : 0|1@0+ (1,0) [0|1] "" EDC
 SG_ AMP_MidWarnSoundSourceStatus : 15|1@0+ (1,0) [0|1] "" EDC
 SG_ AMP_NAVISoundSourceStatus : 4|1@0+ (1,0) [0|1] "" EDC
 SG_ AMP_OutSoundSourceStatus : 8|1@0+ (1,0) [0|1] "" EDC
 SG_ AMP_RFWarnSoundSourceStatus : 12|1@0+ (1,0) [0|1] "" EDC
 SG_ AMP_RRWarnSoundSourceStatus : 14|1@0+ (1,0) [0|1] "" EDC
 SG_ AMP_SystemSoundSourceStatus : 3|1@0+ (1,0) [0|1] "" EDC
 SG_ AMP_TELSoundSourceStatus : 1|1@0+ (1,0) [0|1] "" EDC
 SG_ AMP_TurnLightSoundSourceStatus : 10|1@0+ (1,0) [0|1] "" EDC
 SG_ AMP_VRSoundSourceStatus : 2|1@0+ (1,0) [0|1] "" EDC

BO_ 690 EVCC_2B2: 64 EVCC
 SG_ VcuDcChrgLckReq : 1|2@0+ (1,0) [0|3] "" VIU_FL

BO_ 699 ICDC_2BB: 8 ICDC
 SG_ AD_APASysEnaSta : 7|4@0+ (1,0) [0|15] "" VIU_FL
 SG_ AD_APAOnOff : 3|1@0+ (1,0) [0|1] "" VIU_FL

BO_ 722 VIU_FL_2D2: 64 VIU_FL
 SG_ AcRemStartSts : 71|1@0+ (1,0) [0|1] "" VIU_FR
 SG_ CDC_CRCCheck_2D2 : 503|16@0+ (1,0) [0|65535] "" Vector__XXX
 SG_ CDC_RollingCounter_2D2 : 491|4@0+ (1,0) [0|15] "" Vector__XXX
 SG_ CdcAcChrgILimSet : 205|6@0+ (1,0) [0|63] "A" Vector__XXX
 SG_ CdcAntiRustFctSet : 63|2@0+ (1,0) [0|3] "" Vector__XXX
 SG_ CdcAqsOpenSet : 215|2@0+ (1,0) [0|3] "" VIU_FR
 SG_ CdcAutoApplyFctSet : 321|2@0+ (1,0) [0|3] "" Vector__XXX
 SG_ CdcAutoDefrstDefogStsReq : 425|2@0+ (1,0) [0|3] "" VIU_FR
 SG_ CdcAutoWindLongPressSet : 385|2@0+ (1,0) [0|3] "" VIU_FR
 SG_ CdcAutoWindUnlockSet : 213|2@0+ (1,0) [0|3] "" VIU_FR
 SG_ CdcAVHFctSet : 325|2@0+ (1,0) [0|3] "" Vector__XXX
 SG_ CdcBacktWindLvlSetReq : 339|2@0+ (1,0) [0|3] "" VIU_FR
 SG_ CdcBattPlsHeatgSet : 375|2@0+ (1,0) [0|3] "" Vector__XXX
 SG_ CdcBDWFctSet : 359|2@0+ (1,0) [0|3] "" Vector__XXX
 SG_ CdcBrkPedlModSet : 431|2@0+ (1,0) [0|3] "" Vector__XXX
 SG_ CdcCycModSet : 246|3@0+ (1,0) [0|7] "" VIU_FR
 SG_ CdcDrvrTSet : 263|6@0+ (0.5,17) [17|48.5] "" VIU_FR
 SG_ CdcEpbSwtSet : 429|2@0+ (1,0) [0|3] "" Vector__XXX
 SG_ CdcEspFctSet : 273|2@0+ (1,0) [0|3] "" Vector__XXX
 SG_ CdcFrntAutModOpenSet : 303|2@0+ (1,0) [0|3] "" VIU_FR
 SG_ CdcFrntBlowModSet : 301|4@0+ (1,0) [0|15] "" VIU_FR
 SG_ CdcFrntDefrosterSet : 297|2@0+ (1,0) [0|3] "" VIU_FR
 SG_ CdcFrntWindLvlSet : 311|4@0+ (1,0) [0|15] "" VIU_FR
 SG_ CdcFrontAcOffSet : 327|2@0+ (1,0) [0|3] "" VIU_FR
 SG_ CdcHDCFctSet : 355|2@0+ (1,0) [0|3] "" Vector__XXX
 SG_ CdcHotColdModStReq : 352|3@0+ (1,0) [0|7] "" VIU_FR
 SG_ CdcIBCUDrvModSet : 357|2@0+ (1,0) [0|3] "" Vector__XXX
 SG_ CdcORCAFctSet : 9|2@0+ (1,0) [0|3] "" Vector__XXX
 SG_ CdcPassTSet : 391|6@0+ (0.5,17) [17|48.5] "" VIU_FR
 SG_ CdcPlasmaOpenSet : 373|2@0+ (1,0) [0|3] "" VIU_FR
 SG_ CdcSteerModSet : 3|2@0+ (1,0) [0|3] "" VIU_FR
 SG_ CdcTotMilg : 399|24@0+ (0.1,0) [0|1677721.5] "Km" EDC,AMP,IP
 SG_ CdcVehEgyCnseSelect : 132|2@0+ (1,0) [0|3] "" Vector__XXX
 SG_ CdcVentnOnSet : 419|2@0+ (1,0) [0|3] "" VIU_FR
 SG_ CdcWorkSpaceSet : 417|2@0+ (1,0) [0|3] "" VIU_FR
 SG_ CST_OFF_Switch : 364|3@0+ (1,0) [0|3] "" Vector__XXX
 SG_ HU_ACRearFanAdjustValueReq : 83|4@0+ (1,0) [0|15] "" VIU_FR
 SG_ HU_ACRearModeAdjustReq : 76|3@0+ (1,0) [0|7] "" VIU_FR
 SG_ HU_ACRearTempAdjustValueReq2 : 21|6@0+ (0.5,17) [17|48.5] "degree" VIU_FR
 SG_ HU_AutowindSet3 : 68|2@0+ (1,0) [0|3] "" VIU_FR
 SG_ HU_MaxACReq : 7|2@0+ (1,0) [0|3] "" VIU_FR
 SG_ HU_MaxDefReq : 15|2@0+ (1,0) [0|3] "" VIU_FR
 SG_ HU_MaxHeatReq : 5|2@0+ (1,0) [0|3] "" VIU_FR
 SG_ HU_RearACOfffReq : 23|2@0+ (1,0) [0|3] "" VIU_FR
 SG_ HU_RearAUTOACOnReq : 73|2@0+ (1,0) [0|3] "" VIU_FR
 SG_ HU_RefreshModeEnable : 29|2@0+ (1,0) [0|3] "" VIU_FR
 SG_ HU_Request_AFUchannel : 65|2@0+ (1,0) [0|3] "" VIU_FR
 SG_ HU_Request_AFUContentleve : 13|4@0+ (1,0) [0|15] "" VIU_FR
 SG_ HU_Request_AFUSt : 61|2@0+ (1,0) [0|3] "" VIU_FR
 SG_ HU_RollerbenchSetStaus : 1|2@0+ (1,0) [0|3] "" Vector__XXX
 SG_ HU_VentilationSetAfternoon : 51|4@0+ (1,0) [0|15] "" VIU_FR
 SG_ HU_VentilationSetEvening : 55|4@0+ (1,0) [0|15] "" VIU_FR
 SG_ HU_VentilationSetMorning : 59|4@0+ (1,0) [0|15] "" VIU_FR
 SG_ HUAcEgySaveModReq : 87|2@0+ (1,0) [0|3] "" VIU_FR
 SG_ HUAutoAirCleanReq : 85|2@0+ (1,0) [0|3] "" VIU_FR
 SG_ HUBatPulseHeatSwitchReq : 89|2@0+ (1,0) [0|3] "" VIU_FR
 SG_ HUMotLockHeatSwitchReq : 91|2@0+ (1,0) [0|3] "" VIU_FR
 SG_ HUSngPrsnModReq : 78|2@0+ (1,0) [0|3] "" VIU_FR
 SG_ VIUDrvModSet : 27|4@0+ (1,0) [0|15] "" IP

BO_ 753 VIU_FL_2F1: 32 VIU_FL
 SG_ RCM_RLTuLiSt : 0|1@0+ (1,0) [0|1] "" VIU_FR
 SG_ RCM_RRTuLiSt : 2|1@0+ (1,0) [0|1] "" VIU_FR

BO_ 759 EDC_2F7: 8 EDC
 SG_ TboxLocalTiDate : 20|5@0+ (1,0) [0|31] "day" TBOX,VIU_FL,AMP
 SG_ TboxLocalTiHr : 28|5@0+ (1,0) [0|31] "hour" TBOX,VIU_FL,AMP
 SG_ TboxLocalTiMins : 37|6@0+ (1,0) [0|63] "minute" TBOX,VIU_FL,AMP
 SG_ TboxLocalTiMth : 11|4@0+ (1,0) [0|15] "month" TBOX,VIU_FL,AMP
 SG_ TboxLocalTiSec : 45|6@0+ (1,0) [0|63] "second" TBOX,VIU_FL,AMP
 SG_ TboxLocalTiVld : 46|1@0+ (1,0) [0|1] "" TBOX,VIU_FL,AMP
 SG_ TboxLocalTiYear : 7|8@0+ (1,2000) [2000|2255] "year" TBOX,VIU_FL,AMP

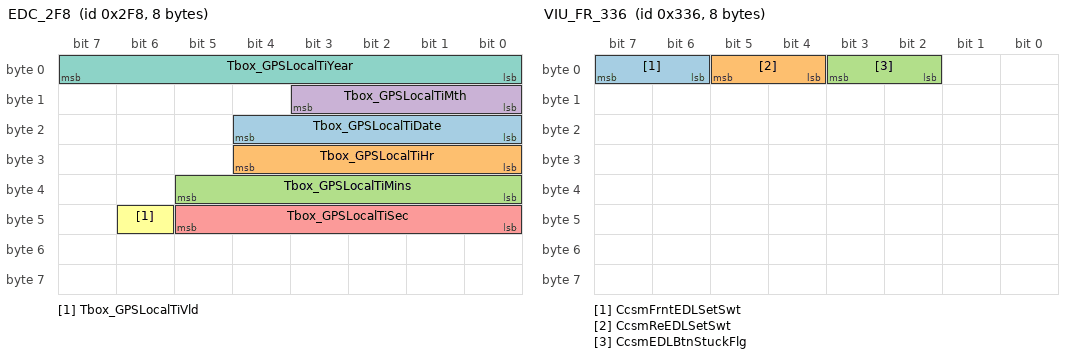
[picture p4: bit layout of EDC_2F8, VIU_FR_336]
BO_ 760 EDC_2F8: 8 EDC
 SG_ Tbox_GPSLocalTiDate : 20|5@0+ (1,0) [0|31] "day" TBOX,VIU_FL
 SG_ Tbox_GPSLocalTiHr : 28|5@0+ (1,0) [0|31] "hour" TBOX,VIU_FL
 SG_ Tbox_GPSLocalTiMins : 37|6@0+ (1,0) [0|63] "minute" TBOX,VIU_FL
 SG_ Tbox_GPSLocalTiMth : 11|4@0+ (1,0) [0|15] "month" TBOX,VIU_FL
 SG_ Tbox_GPSLocalTiSec : 45|6@0+ (1,0) [0|63] "second" TBOX,VIU_FL
 SG_ Tbox_GPSLocalTiVld : 46|1@0+ (1,0) [0|1] "" TBOX,VIU_FL
 SG_ Tbox_GPSLocalTiYear : 7|8@0+ (1,2000) [2000|2255] "year" TBOX,VIU_FL

BO_ 774 VIU_FL_306: 64 VIU_FL
 SG_ AC_ACOnOff : 4|2@0+ (1,0) [0|3] "" EDC
 SG_ ITMSLiquidLevel : 181|2@0+ (1,0) [0|3] "" IP
 SG_ TmsComOutPtPre : 0|9@0+ (0.01,0) [0|5.11] "Mpa" AMP,EDC

BO_ 779 EDC_30B: 64 EDC
 SG_ CDC_CRCCheck_30B : 503|16@0+ (1,0) [0|65535] "" VIU_FL
 SG_ CDC_RollingCounter_30B : 491|4@0+ (1,0) [0|15] "" VIU_FL
 SG_ CdcIPScreenLiOnSts : 276|1@0+ (1,0) [0|1] "" VIU_FL
 SG_ IP_DISFail : 130|1@0+ (1,0) [0|1] "" VIU_FL
 SG_ IP_juADASshowinfa : 134|1@0+ (1,0) [0|1] "" VIU_FL
 SG_ IP_juADASshowoutfa : 135|1@0+ (1,0) [0|1] "" VIU_FL
 SG_ IP_juADAStsE2Efaout : 133|1@0+ (1,0) [0|1] "" VIU_FL
 SG_ IP_QDashACCFail : 129|2@0+ (1,0) [0|3] "" VIU_FL
 SG_ AD_EDCCrtSts : 11|4@0+ (1,0) [0|15] "" VIU_FR
 SG_ AD_EDCCurrenttemp : 7|8@0+ (1,-40) [-40|215] "" VIU_FR
 SG_ TboxDoorLockRemCtrlReq : 14|3@0+ (1,0) [0|7] "" VIU_FL,VIU_FR

BO_ 784 AMP_310: 64 AMP
 SG_ AMP_Err_Detect : 455|16@0+ (1,0) [0|65535] "" Vector__XXX
 SG_ AMP_FLHighSpeakerDelaySETStatus : 207|4@0+ (1,0) [0|15] "" EDC
 SG_ AMP_FLHighSpeakerVolSETStatus : 218|5@0+ (1,0) [0|31] "" EDC
 SG_ AMP_FLMidSpeakerDelaySETStatus : 203|4@0+ (1,0) [0|15] "" EDC
 SG_ AMP_FLMidSpeakerVolSETStatus : 229|5@0+ (1,0) [0|31] "" EDC
 SG_ AMP_FRHighSpeakerDelaySETStatus : 224|5@0+ (1,0) [0|31] "" EDC
 SG_ AMP_FRHighSpeakerVolSETStatus : 212|5@0+ (1,0) [0|31] "" EDC
 SG_ AMP_FRMidSpeakerDelaySETStatus : 235|5@0+ (1,0) [0|31] "" EDC
 SG_ AMP_FRMidSpeakerVolSETStatus : 223|5@0+ (1,0) [0|31] "" EDC
 SG_ AMP_Slot_Detect : 471|16@0+ (1,0) [0|65535] "" Vector__XXX
 SG_ AMP_SV_Detect : 111|16@0+ (1,0) [0|65535] "" Vector__XXX
 SG_ AMP_AlarmVolSETStatus : 95|2@0+ (1,0) [0|3] "" EDC
 SG_ AMP_AvasVolSETStatus : 433|2@0+ (1,0) [0|3] "" EDC
 SG_ AMP_CenterSpeakerDelaySETStatus : 265|5@0+ (1,0) [0|31] "" EDC
 SG_ AMP_CenterSpeakerVolSETStatus : 340|5@0+ (1,0) [0|31] "" EDC
 SG_ AMP_CustomEffectSETStatus : 127|4@0+ (1,0) [0|15] "" EDC
 SG_ AMP_CustomEQ125SET : 43|4@0+ (1,-8) [-8|7] "" EDC
 SG_ AMP_CustomEQ16KSET : 71|4@0+ (1,-8) [-8|7] "" EDC
 SG_ AMP_CustomEQ1KSET : 55|4@0+ (1,-8) [-8|7] "" EDC
 SG_ AMP_CustomEQ250SET : 47|4@0+ (1,-8) [-8|7] "" EDC
 SG_ AMP_CustomEQ2KSET : 59|4@0+ (1,-8) [-8|7] "" EDC
 SG_ AMP_CustomEQ4KSET : 63|4@0+ (1,-8) [-8|7] "" EDC
 SG_ AMP_CustomEQ500SET : 51|4@0+ (1,-8) [-8|7] "" EDC
 SG_ AMP_CustomEQ62SET : 39|4@0+ (1,-8) [-8|7] "" EDC
 SG_ AMP_CustomEQ8KSET : 67|4@0+ (1,-8) [-8|7] "" EDC
 SG_ AMP_FLLowSpeakerDelaySETStatus : 293|5@0+ (1,0) [0|31] "" EDC
 SG_ AMP_FLLowSpeakerVolSETStatus : 352|5@0+ (1,0) [0|31] "" EDC
 SG_ AMP_FLMidHighSpeakerDelaySETStat : 407|4@0+ (1,0) [0|15] "" EDC
 SG_ AMP_FLMidHighSpeakerVolSETStatus : 380|5@0+ (1,0) [0|31] "" EDC
 SG_ AMP_FLTopSpeakerDelaySETStatus : 259|5@0+ (1,0) [0|31] "" EDC
 SG_ AMP_FLTopSpeakerVolSETStatus : 334|5@0+ (1,0) [0|31] "" EDC
 SG_ AMP_FRBalanceSETStatus : 75|4@0+ (1,-8) [-8|7] "" EDC
 SG_ AMP_FRLowSpeakerDelaySETStatus : 282|5@0+ (1,0) [0|31] "" EDC
 SG_ AMP_FRLowSpeakerVolSETStatus : 357|5@0+ (1,0) [0|31] "" EDC
 SG_ AMP_FRMidHighSpeakerDelaySET : 299|5@0+ (1,0) [0|31] "" EDC
 SG_ AMP_FRMidHighSpeakerVolSETStatus : 374|5@0+ (1,0) [0|31] "" EDC
 SG_ AMP_FRTopSpeakerDelaySETStatus : 252|5@0+ (1,0) [0|31] "" EDC
 SG_ AMP_FRTopSpeakerVolSETStatus : 323|5@0+ (1,0) [0|31] "" EDC
 SG_ AMP_KTVMUTESETStatus : 429|2@0+ (1,0) [0|3] "" EDC
 SG_ AMP_KTVVolSETStatus : 396|5@0+ (1,0) [0|31] "" EDC
 SG_ AMP_LRBalanceSETStatus : 83|4@0+ (1,-8) [-8|7] "" EDC
 SG_ AMP_MediaMUTESETStatus : 437|2@0+ (1,0) [0|3] "" EDC
 SG_ AMP_MediaVolSETStatus : 6|5@0+ (1,0) [0|31] "" EDC
 SG_ AMP_MUTESETStatus : 435|2@0+ (1,0) [0|3] "" EDC
 SG_ AMP_NaviMUTESETStatus : 439|2@0+ (1,0) [0|3] "" EDC
 SG_ AMP_NAVIVolSETStatus : 28|5@0+ (1,0) [0|31] "" EDC
 SG_ AMP_OutMUTESETStatus : 417|2@0+ (1,0) [0|3] "" EDC
 SG_ AMP_OUTVolSETStatus : 388|5@0+ (1,0) [0|31] "" EDC
 SG_ AMP_PerfessiionalEQ100SET : 411|4@0+ (1,0) [0|15] "" EDC
 SG_ AMP_PerfessiionalEQ500SET : 415|4@0+ (1,0) [0|15] "" EDC
 SG_ AMP_PerfessiionalEQ6KSET : 403|4@0+ (1,0) [0|15] "" EDC
 SG_ AMP_RLLowHighSpeakerDelaySETStat : 310|5@0+ (1,0) [0|31] "" EDC
 SG_ AMP_RLLowHighSpeakerVolSETStatus : 369|5@0+ (1,0) [0|31] "" EDC
 SG_ AMP_RLSurroundSpeakerDelaySETSta : 287|5@0+ (1,0) [0|31] "" EDC
 SG_ AMP_RLSurroundSpeakerVolSETStatu : 346|5@0+ (1,0) [0|31] "" EDC
 SG_ AMP_RLTopSpeakerDelaySETStatus : 241|5@0+ (1,0) [0|31] "" EDC
 SG_ AMP_RLTopSpeakerVolSETStatus : 316|5@0+ (1,0) [0|31] "" EDC
 SG_ AMP_RNCEnableSETStatus : 123|2@0+ (1,0) [0|3] "" EDC
 SG_ AMP_RRLowHighSpeakerDelaySET : 288|5@0+ (1,0) [0|31] "" EDC
 SG_ AMP_RRLowHighSpeakerVolSETStatus : 363|5@0+ (1,0) [0|31] "" EDC
 SG_ AMP_RRSurroundSpeakerDelaySETSta : 276|5@0+ (1,0) [0|31] "" EDC
 SG_ AMP_RRSurroundSpeakerVolSET : 351|5@0+ (1,0) [0|31] "" EDC
 SG_ AMP_RRTopSpeakerDelaySETStatus : 246|5@0+ (1,0) [0|31] "" EDC
 SG_ AMP_RRTopSpeakerVolSETStatus : 305|5@0+ (1,0) [0|31] "" EDC
 SG_ AMP_SoundEffectSETStatus : 35|4@0+ (1,0) [0|15] "" EDC
 SG_ AMP_SoundFieldSETStatus : 1|4@0+ (1,0) [0|15] "" EDC
 SG_ AMP_SubSpeakerDelaySETStatus : 270|5@0+ (1,0) [0|31] "" EDC
 SG_ AMP_SubSpeakerVolSETStatus : 329|5@0+ (1,0) [0|31] "" EDC
 SG_ AMP_SystemMUTESETStatus : 431|2@0+ (1,0) [0|3] "" EDC
 SG_ AMP_SystemVolSETStatus : 422|5@0+ (1,0) [0|31] "" EDC
 SG_ AMP_TelBcallMUTESETStatus : 425|2@0+ (1,0) [0|3] "" EDC
 SG_ AMP_TELBCALLVolSETStatus : 12|5@0+ (1,0) [0|31] "" EDC
 SG_ AMP_TTSVRMUTESETStatus : 427|2@0+ (1,0) [0|3] "" EDC
 SG_ AMP_TTSVRVolSETStatus : 20|5@0+ (1,0) [0|31] "" EDC
 SG_ AMP_TurnLightInOrOutSETStatus : 441|2@0+ (1,0) [0|1] "" EDC
 SG_ AMP_TurnLightVolSETStatus : 444|2@0+ (1,0) [0|3] "" EDC
 SG_ AMP_VOLSpeedEnableSETStatus : 121|2@0+ (1,0) [0|3] "" EDC

BO_ 800 AMP_320: 64 AMP
 SG_ AMPFLPositionDelaySETStatus : 259|4@0+ (1,0) [0|15] "" EDC
 SG_ AMPFLPositionVolSETStatus : 147|5@0+ (1,0) [0|31] "" EDC
 SG_ AMPFRPositionDelaySETStatus : 164|5@0+ (1,0) [0|31] "" EDC
 SG_ AMPFRPositionVolSETStatus : 175|5@0+ (1,0) [0|31] "" EDC
 SG_ AMPBeosonicModeSetStatus : 5|3@0+ (1,0) [0|7] "" EDC
 SG_ AMPBeosonicXSetStatus : 2|5@0+ (1,0) [0|31] "" EDC
 SG_ AMPBeosonicYSetStatus : 13|5@0+ (1,0) [0|31] "" EDC
 SG_ AMPCenterPositionDelaySETStatus : 141|5@0+ (1,0) [0|31] "" EDC
 SG_ AMPCenterPositionVolSETStatus : 136|5@0+ (1,0) [0|31] "" EDC
 SG_ AMPCustomEQ2500SET : 123|4@0+ (1,-8) [-8|7] "" EDC
 SG_ AMPCustomEQ315SET : 59|4@0+ (1,-8) [-8|7] "" EDC
 SG_ AMPCustomEQ50SET : 263|4@0+ (1,-8) [-8|7] "" EDC
 SG_ AMPCustomEQ6000SET : 187|4@0+ (1,-8) [-8|7] "" EDC
 SG_ AMPCustomEQ800SET : 251|4@0+ (1,-8) [-8|7] "" EDC
 SG_ AMPFLTopPositionDelaySETStatus : 158|5@0+ (1,0) [0|31] "" EDC
 SG_ AMPFLTopPositionVolSETStatus : 153|5@0+ (1,0) [0|31] "" EDC
 SG_ AMPFRTopPositionDelaySETStatus : 170|5@0+ (1,0) [0|31] "" EDC
 SG_ AMPFRTopPositionVolSETStatus : 181|5@0+ (1,0) [0|31] "" EDC
 SG_ AMPRLPositionDelaySETStatus : 176|5@0+ (1,0) [0|31] "" EDC
 SG_ AMPRLPositionVolSETStatus : 199|5@0+ (1,0) [0|31] "" EDC
 SG_ AMPRLSurroundDelaySETStatus : 194|5@0+ (1,0) [0|31] "" EDC
 SG_ AMPRLSurroundVolSETStatus : 205|5@0+ (1,0) [0|31] "" EDC
 SG_ AMPRLTopDelaySETStatus : 200|5@0+ (1,0) [0|31] "" EDC
 SG_ AMPRLTopVolSETStatus : 211|5@0+ (1,0) [0|31] "" EDC
 SG_ AMPRRPositionDelaySET : 222|5@0+ (1,0) [0|31] "" EDC
 SG_ AMPRRPositionVolSETStatus : 217|5@0+ (1,0) [0|31] "" EDC
 SG_ AMPRRSurroundPositionDelaySETSta : 228|5@0+ (1,0) [0|31] "" EDC
 SG_ AMPRRSurroundPositionVolSET : 239|5@0+ (1,0) [0|31] "" EDC
 SG_ AMPRRTopPositionDelaySETStatus : 234|5@0+ (1,0) [0|31] "" EDC
 SG_ AMPRRTopPositionVolSETStatus : 245|5@0+ (1,0) [0|31] "" EDC
 SG_ AMPSoundSourceTypeStatus : 7|2@0+ (1,0) [0|3] "" EDC
 SG_ AMPSubPositionDelaySETStatus : 240|5@0+ (1,0) [0|31] "" EDC
 SG_ AMPSubPositionVolSETStatus : 271|5@0+ (1,0) [0|31] "" EDC
 SG_ AMPTMCenterPositionEQ15000HzSetS : 71|5@0+ (1,0) [0|31] "" EDC
 SG_ AMPTMCenterPositionEQ800HzSetSta : 48|5@0+ (1,0) [0|31] "" EDC
 SG_ AMPTMFLPositionEQ100HzSetStatus : 30|5@0+ (1,0) [0|31] "" EDC
 SG_ AMPTMFLPositionEQ15000HzSetStatu : 36|5@0+ (1,0) [0|31] "" EDC
 SG_ AMPTMFLPositionEQ800HzSetStatus : 25|5@0+ (1,0) [0|31] "" EDC
 SG_ AMPTMFLTopPositionEQ500HzSetStat : 117|5@0+ (1,0) [0|31] "" EDC
 SG_ AMPTMFRPositionEQ100HzSetStatus : 47|5@0+ (1,0) [0|31] "" EDC
 SG_ AMPTMFRPositionEQ15000HzSetStatu : 53|5@0+ (1,0) [0|31] "" EDC
 SG_ AMPTMFRPositionEQ800HzSetStatus : 42|5@0+ (1,0) [0|31] "" EDC
 SG_ AMPTMFRTopPositionEQ500HzSetStat : 112|5@0+ (1,0) [0|31] "" EDC
 SG_ AMPTMReverbSetStatus : 8|7@0+ (1,0) [0|127] "" EDC
 SG_ AMPTMRLPositionEQ10000HzSetStatu : 72|5@0+ (1,0) [0|31] "" EDC
 SG_ AMPTMRLPositionEQ100HzSetStatusS : 77|5@0+ (1,0) [0|31] "" EDC
 SG_ AMPTMRLSurroundPositionEQ15000Hz : 100|5@0+ (1,0) [0|31] "" EDC
 SG_ AMPTMRLSurroundPositionEQ800HzSe : 89|5@0+ (1,0) [0|31] "" EDC
 SG_ AMPTMRLTopPositionEQ500HzSetStat : 135|5@0+ (1,0) [0|31] "" EDC
 SG_ AMPTMRRPositionEQ10000HzSetStatu : 94|5@0+ (1,0) [0|31] "" EDC
 SG_ AMPTMRRPositionEQ100HzSetStatus : 83|5@0+ (1,0) [0|31] "" EDC
 SG_ AMPTMRRSurroundPositionEQ15000Hz : 106|5@0+ (1,0) [0|31] "" EDC
 SG_ AMPTMRRSurroundPositionEQ800HzSe : 111|5@0+ (1,0) [0|31] "" EDC
 SG_ AMPTMRRTopPositionEQ500HzSetStat : 130|5@0+ (1,0) [0|31] "" EDC
 SG_ AMPTMSubPositionEQ30HzSetStatusS : 66|5@0+ (1,0) [0|31] "" EDC
 SG_ AMPVOLSpeedLevChangeSETStatus : 17|3@0+ (1,0) [0|7] "" EDC

BO_ 802 VIU_FL_322: 64 VIU_FL
 SG_ ECAStarLvl : 23|8@0+ (1,-128) [-128|127] "MM" VIU_FR
 SG_ ECASActLvlFL : 71|16@0- (0.01,0) [-327.67|327.67] "MM" VIU_FR
 SG_ ECASActLvlFR : 87|16@0- (0.01,0) [-327.67|327.67] "MM" VIU_FR
 SG_ ECASActLvlRL : 47|16@0- (0.01,0) [-327.67|327.67] "MM" VIU_FR
 SG_ ECASActLvlRR : 31|16@0- (0.01,0) [-327.67|327.67] "MM" VIU_FR
 SG_ ECASAdjBySpd : 8|1@0+ (1,0) [0|1] "" VIU_FR
 SG_ ECASaftaxladjsts : 100|2@0+ (1,0) [0|2] "" EDC
 SG_ ECASerromode : 103|3@0+ (1,0) [0|5] "" EDC
 SG_ ECASfrtaxladjsts : 98|2@0+ (1,0) [0|2] "" EDC
 SG_ EcasModeCHASts : 2|3@0+ (1,0) [0|7] "" VIU_FR,ICDC
 SG_ EcasModeFB : 7|5@0+ (1,0) [0|31] "" VIU_FR,ICDC
 SG_ ECASmodevld : 96|1@0+ (1,0) [0|1] "" EDC
 SG_ SusfaultlLamp : 113|2@0+ (1,0) [0|2] "" EDC,ICDC
 SG_ Susfaultred : 111|8@0+ (1,0) [0|255] "" EDC

BO_ 821 VIU_FL_335: 64 VIU_FL
 SG_ BCM_DriverWindowStatus : 199|8@0+ (0.5,0) [0|100] "%" AMP,EDC
 SG_ BCM_PartWinPosVIT : 119|8@0+ (1,0) [0|101] "" AMP,EDC
 SG_ BCM_PartWinSts : 127|8@0+ (1,0) [0|15] "" AMP,EDC
 SG_ BCM_PassengerWindowPosi : 223|8@0+ (0.5,0) [0|100] "%" AMP,EDC
 SG_ BCM_PassengerWindowStatus : 215|8@0+ (0.5,0) [0|100] "%" AMP,EDC
 SG_ VcuIpuErrLamp : 83|1@0+ (1,0) [0|1] "" Vector__XXX
 SG_ VcuEgyMagtModResp : 455|8@0+ (1,0) [0|255] "NA" IP
 SG_ VcuForceEVModResp : 348|1@0+ (1,0) [0|1] "NA" IP
 SG_ VcuForcePwrPresModResp : 349|1@0+ (1,0) [0|1] "NA" IP
 SG_ BCM_RightRearWindowPosi : 255|8@0+ (0.5,0) [0|100] "%" AMP,EDC
 SG_ BCM_RightRearWindowStatus : 247|8@0+ (0.5,0) [0|100] "%" AMP,EDC
 SG_ VCU_CRCCheck_335 : 503|16@0+ (1,0) [0|65535] "" Vector__XXX
 SG_ VCU_RollingCounter_335 : 491|4@0+ (1,0) [0|15] "" Vector__XXX
 SG_ VcuAcChrgNegativePoleTemp : 191|8@0+ (1,-40) [-40|215] "℃" Vector__XXX
 SG_ VcuAccrPedlPosnGb : 383|8@0+ (1,0) [0|100] "%" Vector__XXX
 SG_ VcuBattIGb : 399|16@0+ (0.1,-1000) [-1000|5553.5] "A" Vector__XXX
 SG_ VcuGearPosnStsGb : 391|8@0+ (1,0) [0|255] "" Vector__XXX
 SG_ VcuHvilStsGb : 345|1@0+ (1,0) [0|1] "" Vector__XXX
 SG_ VcuVehChrgStsGb : 367|8@0+ (1,0) [0|4] "" Vector__XXX
 SG_ VcuVehRunngModGb : 375|8@0+ (1,0) [0|3] "" Vector__XXX
 SG_ VcuVehStsGb : 359|8@0+ (1,0) [0|3] "" Vector__XXX
 SG_ VcuBrkPedlSts : 319|2@0+ (1,0) [0|3] "" Vector__XXX
 SG_ VcuPwrCnse : 288|9@0+ (1,-150) [-150|361] "kW" Vector__XXX
 SG_ VcuSocDisp : 310|7@0+ (1,0) [0|127] "%" Vector__XXX
 SG_ BCM_DriverWindowPosi : 207|8@0+ (0.5,0) [0|100] "%" AMP,EDC
 SG_ BCM_LeftRearWindowPosi : 239|8@0+ (0.5,0) [0|100] "%" AMP,EDC
 SG_ BCM_LeftRearWindowStatus : 231|8@0+ (0.5,0) [0|100] "%" AMP,EDC
 SG_ BcmSunroofPosi : 270|7@0+ (1,0) [0|127] "" AMP,EDC
 SG_ BcmSunroofStatus : 262|7@0+ (1,0) [0|127] "" AMP,EDC
 SG_ MFS_Right_switch_Right1_signal : 93|2@0+ (1,0) [0|3] "" EDC
 SG_ VcuAcChrgPositivePoleTemp : 183|8@0+ (1,-40) [-40|215] "℃" Vector__XXX
 SG_ VcuBattChrgErrLamp : 8|1@0+ (1,0) [0|1] "" Vector__XXX
 SG_ VcuBattlowU : 71|8@0+ (0.1,0) [0|25.5] "V" Vector__XXX
 SG_ VcuBattUUnderWarn : 81|2@0+ (1,0) [0|3] "" Vector__XXX
 SG_ VcuChrgAutoUnlckSetStsFb : 97|2@0+ (1,0) [0|3] "" Vector__XXX
 SG_ VcuChrgLckInfo : 101|3@0+ (1,0) [0|7] "" Vector__XXX
 SG_ VcuDcChrgNegativePoleTemp : 175|8@0+ (1,-40) [-40|215] "℃" Vector__XXX
 SG_ VcuDcChrgPositivePoleTemp : 167|8@0+ (1,-40) [-40|215] "℃" Vector__XXX
 SG_ VCUGearShiftPositon : 315|4@0+ (1,0) [0|15] "" IP,EDC
 SG_ VcuHvBattCutOffLamp : 82|1@0+ (1,0) [0|1] "" Vector__XXX
 SG_ VcuHVErrInfo : 90|1@0+ (1,0) [0|1] "" Vector__XXX
 SG_ VcuHvilSts : 344|1@0+ (1,0) [0|1] "" Vector__XXX
 SG_ VcuResiMilg : 23|11@0+ (1,0) [0|2047] "km" Vector__XXX
 SG_ VcuShiftPErrInfo : 89|1@0+ (1,0) [0|1] "" Vector__XXX
 SG_ VCUShiftPostionValid : 311|1@0+ (1,0) [0|1] "" EDC
 SG_ VcuVehErrInfo : 88|1@0+ (1,0) [0|1] "" Vector__XXX
 SG_ VIUFL_DeviceVerifyResult : 487|2@0+ (1,0) [0|3] "" EDC
 SG_ VcuOffRoadCrpSts : 2|3@0+ (1,0) [0|7] "" IP
 SG_ BCMALLDoorLockSwt : 28|3@0+ (1,0) [0|7] "" EDC

BO_ 822 VIU_FR_336: 8 VIU_FR
 SG_ CcsmFrntEDLSetSwt : 7|2@0+ (1,0) [0|3] "" VIU_FL
 SG_ CcsmReEDLSetSwt : 5|2@0+ (1,0) [0|3] "" VIU_FL
 SG_ CcsmEDLBtnStuckFlg : 3|2@0+ (1,0) [0|3] "" VIU_FL

BO_ 854 EDC_356: 64 EDC
 SG_ HU_FLHighSpeakerDelaySET : 419|4@0+ (1,0) [0|15] "" AMP
 SG_ HU_FLHighSpeakerVolSET : 386|5@0+ (1,0) [0|31] "" AMP
 SG_ HU_FLMidSpeakerDelaySET : 423|4@0+ (1,0) [0|15] "" AMP
 SG_ HU_FLMidSpeakerVolSET : 391|5@0+ (1,0) [0|31] "" AMP
 SG_ HU_FRHighSpeakerDelaySET : 414|5@0+ (1,0) [0|31] "" AMP
 SG_ HU_FRHighSpeakerVolSET : 392|5@0+ (1,0) [0|31] "" AMP
 SG_ HU_FRMidSpeakerDelaySET : 403|5@0+ (1,0) [0|31] "" AMP
 SG_ HU_FRMidSpeakerVolSET : 397|5@0+ (1,0) [0|31] "" AMP
 SG_ HUFLPositionDelaySET : 507|4@0+ (1,0) [0|15] "" AMP
 SG_ HUFLPositionVolSET : 473|5@0+ (1,0) [0|31] "" AMP
 SG_ HUFRPositionDelaySET : 490|5@0+ (1,0) [0|31] "" AMP
 SG_ HUFRPositionVolSET : 501|5@0+ (1,0) [0|31] "" AMP
 SG_ HU_AlarmVolSET : 102|2@0+ (1,0) [0|3] "" AMP
 SG_ HU_AvasVolSET : 329|2@0+ (1,0) [0|3] "" AMP
 SG_ HU_CenterSpeakerDelaySET : 259|5@0+ (1,0) [0|31] "" AMP
 SG_ HU_CenterSpeakerVolSET : 206|5@0+ (1,0) [0|31] "" AMP
 SG_ HU_CustomEffectSET : 79|4@0+ (1,0) [0|15] "" AMP
 SG_ HU_CustomEQ125SET : 43|4@0+ (1,-8) [-8|7] "" AMP
 SG_ HU_CustomEQ16KSET : 71|4@0+ (1,-8) [-8|7] "" AMP
 SG_ HU_CustomEQ1KSET : 55|4@0+ (1,-8) [-8|7] "" AMP
 SG_ HU_CustomEQ250SET : 47|4@0+ (1,-8) [-8|7] "" AMP
 SG_ HU_CustomEQ2KSET : 59|4@0+ (1,-8) [-8|7] "" AMP
 SG_ HU_CustomEQ4KSET : 63|4@0+ (1,-8) [-8|7] "" AMP
 SG_ HU_CustomEQ500SET : 51|4@0+ (1,-8) [-8|7] "" AMP
 SG_ HU_CustomEQ62SET : 37|4@0+ (1,-8) [-8|7] "" AMP
 SG_ HU_CustomEQ8KSET : 67|4@0+ (1,-8) [-8|7] "" AMP
 SG_ HU_FLLowSpeakerDelaySET : 287|5@0+ (1,0) [0|31] "" AMP
 SG_ HU_FLLowSpeakerVolSET : 218|5@0+ (1,0) [0|31] "" AMP
 SG_ HU_FLMidHighSpeakerDelaySET : 339|4@0+ (1,0) [0|15] "" AMP
 SG_ HU_FLMidHighSpeakerVolSET : 246|5@0+ (1,0) [0|31] "" AMP
 SG_ HU_FLTopSpeakerDelaySET : 369|5@0+ (1,0) [0|31] "" AMP
 SG_ HU_FLTopSpeakerVolSET : 316|5@0+ (1,0) [0|31] "" AMP
 SG_ HU_FRBalanceSET : 75|4@0+ (1,-8) [-8|7] "" AMP
 SG_ HU_FRLowSpeakerDelaySET : 276|5@0+ (1,0) [0|31] "" AMP
 SG_ HU_FRLowSpeakerVolSET : 223|5@0+ (1,0) [0|31] "" AMP
 SG_ HU_FRMidHighSpeakerDelaySET : 293|5@0+ (1,0) [0|31] "" AMP
 SG_ HU_FRMidHighSpeakerVolSET : 224|5@0+ (1,0) [0|31] "" AMP
 SG_ HU_FRTopSpeakerDelaySET : 374|5@0+ (1,0) [0|31] "" AMP
 SG_ HU_FRTopSpeakerVolSET : 305|5@0+ (1,0) [0|31] "" AMP
 SG_ HU_KTVMUTESET : 323|2@0+ (1,0) [0|3] "" AMP
 SG_ HU_KTVVolSET : 252|5@0+ (1,0) [0|31] "" AMP
 SG_ HU_LRBalanceSET : 83|4@0+ (1,-8) [-8|7] "" AMP
 SG_ HU_MediaMUTESET : 331|2@0+ (1,0) [0|3] "" AMP
 SG_ HU_MediaVolSET : 6|5@0+ (1,0) [0|31] "" AMP
 SG_ HU_MUTESET : 95|2@0+ (1,0) [0|3] "" AMP
 SG_ HU_NaviMUTESET : 333|2@0+ (1,0) [0|3] "" AMP
 SG_ HU_NAVIVolSET : 148|5@0+ (1,0) [0|31] "" AMP
 SG_ HU_OutMUTESET : 327|2@0+ (1,0) [0|3] "" AMP
 SG_ HU_OUTVolSET : 241|5@0+ (1,0) [0|31] "" AMP
 SG_ HU_PerfessiionalEQ100SET : 356|4@0+ (1,0) [0|15] "" AMP
 SG_ HU_PerfessiionalEQ500SET : 347|4@0+ (1,0) [0|15] "" AMP
 SG_ HU_PerfessiionalEQ6KSET : 351|4@0+ (1,0) [0|15] "" AMP
 SG_ HU_RLLowHighSpeakerDelaySET : 288|5@0+ (1,0) [0|31] "" AMP
 SG_ HU_RLLowHighSpeakerVolSET : 235|5@0+ (1,0) [0|31] "" AMP
 SG_ HU_RLSurroundSpeakerDelaySET : 265|5@0+ (1,0) [0|31] "" AMP
 SG_ HU_RLSurroundSpeakerVolSET : 212|5@0+ (1,0) [0|31] "" AMP
 SG_ HU_RLTopSpeakerDelaySET : 363|5@0+ (1,0) [0|31] "" AMP
 SG_ HU_RLTopSpeakerVolSET : 310|5@0+ (1,0) [0|31] "" AMP
 SG_ HU_RNCEnableSET : 124|2@0+ (1,0) [0|3] "" AMP
 SG_ HU_RRLowHighSpeakerDelaySET : 282|5@0+ (1,0) [0|31] "" AMP
 SG_ HU_RRLowHighSpeakerVolSET : 229|5@0+ (1,0) [0|31] "" AMP
 SG_ HU_RRSurroundSpeakerDelaySET : 270|5@0+ (1,0) [0|31] "" AMP
 SG_ HU_RRSurroundSpeakerVolSET : 201|5@0+ (1,0) [0|31] "" AMP
 SG_ HU_RRTopSpeakerDelaySET : 352|5@0+ (1,0) [0|31] "" AMP
 SG_ HU_RRTopSpeakerVolSET : 299|5@0+ (1,0) [0|31] "" AMP
 SG_ HU_SoundEffectSET : 19|4@0+ (1,0) [0|15] "" AMP
 SG_ HU_SoundFieldSET : 1|4@0+ (1,0) [0|15] "" AMP
 SG_ HU_SubSpeakerDelaySET : 380|5@0+ (1,0) [0|31] "" AMP
 SG_ HU_SubSpeakerVolSET : 195|5@0+ (1,0) [0|31] "" AMP
 SG_ HU_SystemMUTESET : 325|2@0+ (1,0) [0|3] "" AMP
 SG_ HU_SystemVolSET : 184|5@0+ (1,0) [0|31] "" AMP
 SG_ HU_TelBcallMUTESET : 335|2@0+ (1,0) [0|3] "" AMP
 SG_ HU_TELBCALLVolSET : 13|5@0+ (1,0) [0|31] "" AMP
 SG_ HU_TTSVRMUTESET : 321|2@0+ (1,0) [0|3] "" AMP
 SG_ HU_TTSVRVolSET : 8|5@0+ (1,0) [0|31] "" AMP
 SG_ HU_TurnLightInOrOutSET : 358|2@0+ (1,0) [0|1] "" AMP
 SG_ HU_TurnLightVolSET : 341|2@0+ (1,0) [0|3] "" AMP
 SG_ HU_VOLSpeedLevEnableSET : 118|2@0+ (1,0) [0|3] "" AMP
 SG_ HUBeosonicModeSet : 105|3@0+ (1,0) [0|7] "" AMP
 SG_ HUBeosonicXSet : 31|5@0+ (1,0) [0|31] "" AMP
 SG_ HUBeosonicYSet : 26|5@0+ (1,0) [0|31] "" AMP
 SG_ HUCenterPositionDelaySET : 467|5@0+ (1,0) [0|31] "" AMP
 SG_ HUCenterPositionVolSET : 478|5@0+ (1,0) [0|31] "" AMP
 SG_ HUCustomEQ2500SET : 136|4@0+ (1,-8) [-8|7] "" AMP
 SG_ HUCustomEQ315SET : 87|4@0+ (1,-8) [-8|7] "" AMP
 SG_ HUCustomEQ50SET : 443|4@0+ (1,-8) [-8|7] "" AMP
 SG_ HUCustomEQ6000SET : 188|4@0+ (1,-8) [-8|7] "" AMP
 SG_ HUCustomEQ800SET : 263|4@0+ (1,-8) [-8|7] "" AMP
 SG_ HUFLTopPositionDelaySET : 484|5@0+ (1,0) [0|31] "" AMP
 SG_ HUFLTopPositionVolSET : 495|5@0+ (1,0) [0|31] "" AMP
 SG_ HUFRTopPositionDelaySET : 496|5@0+ (1,0) [0|31] "" AMP
 SG_ HUSoundSourceType : 33|2@0+ (1,0) [0|3] "" AMP
 SG_ HUTMCenterPositionEQ15000HzSet : 154|5@0+ (1,0) [0|31] "" AMP
 SG_ HUTMCenterPositionEQ800HzSet : 159|5@0+ (1,0) [0|31] "" AMP
 SG_ HUTMFLPositionEQ100HzSet : 99|5@0+ (1,0) [0|31] "" AMP
 SG_ HUTMFLPositionEQ15000HzSet : 116|5@0+ (1,0) [0|31] "" AMP
 SG_ HUTMFLPositionEQ800HzSet : 110|5@0+ (1,0) [0|31] "" AMP
 SG_ HUTMFLTopPositionEQ500HzSet : 455|5@0+ (1,0) [0|31] "" AMP
 SG_ HUTMFRPositionEQ100HzSet : 135|5@0+ (1,0) [0|31] "" AMP
 SG_ HUTMFRPositionEQ15000HzSet : 141|5@0+ (1,0) [0|31] "" AMP
 SG_ HUTMFRPositionEQ800HzSet : 130|5@0+ (1,0) [0|31] "" AMP
 SG_ HUTMFRTopPositionEQ500HzSet : 450|5@0+ (1,0) [0|31] "" AMP
 SG_ HUTMReverbSet : 93|7@0+ (1,0) [0|127] "" AMP
 SG_ HUTMRLPositionEQ10000HzSet : 171|5@0+ (1,0) [0|31] "" AMP
 SG_ HUTMRLPositionEQ100HzSet : 160|5@0+ (1,0) [0|31] "" AMP
 SG_ HUTMRLSurroundPositionEQ15000HzS : 426|5@0+ (1,0) [0|31] "" AMP
 SG_ HUTMRLSurroundPositionEQ800HzSet : 431|5@0+ (1,0) [0|31] "" AMP
 SG_ HUTMRLTopPositionEQ500HzSet : 461|5@0+ (1,0) [0|31] "" AMP
 SG_ HUTMRRPositionEQ10000HzSet : 177|5@0+ (1,0) [0|31] "" AMP
 SG_ HUTMRRPositionEQ100HzSet : 182|5@0+ (1,0) [0|31] "" AMP
 SG_ HUTMRRSurroundPositionEQ15000HzS : 432|5@0+ (1,0) [0|31] "" AMP
 SG_ HUTMRRSurroundPositionEQ800HzSet : 437|5@0+ (1,0) [0|31] "" AMP
 SG_ HUTMRRTopPositionEQ500HzSet : 456|5@0+ (1,0) [0|31] "" AMP
 SG_ HUTMSubPositionEQ30HzSet : 165|5@0+ (1,0) [0|31] "" AMP
 SG_ HUTMTransEnd : 7|1@0+ (1,0) [0|1] "" AMP
 SG_ HUVOLSpeedLevChangeSET : 127|3@0+ (1,0) [0|7] "" AMP

BO_ 868 EDC_364: 8 EDC
 SG_ CdcEpbSetSwt_1 : 1|2@0+ (1,0) [0|3] "" VIU_FR

CM_ BO_ 80 " ";
CM_ SG_ 80 SrsCrashOutpStsChks "碰撞校验信号";
CM_ SG_ 80 SrsCrashOutpSts "碰撞输出信号";
CM_ SG_ 80 SRS_CRCCheck_50 "050帧报文校验";
CM_ SG_ 80 SRS_RollingCounter_50 "050帧报文计数";
CM_ SG_ 80 SrsDrvrBucSwtSts "主驶安全带扣状态";
CM_ SG_ 80 SrsLe2ndBucSwtSts "第二排左安全带扣状态";
CM_ SG_ 80 SrsLe3rdBucSwtSts "第三排左安全带扣状态";
CM_ SG_ 80 SrsMid2ndBucSwtSts "第二排中安全带扣状态";
CM_ SG_ 80 SrsMid3rdBucSwtSts "第三排中安全带扣状态";
CM_ SG_ 80 SrsPadIndcn "副驾驶员安全气囊禁用指示";
CM_ SG_ 80 SrsPassBucSwtSts "副驾驶员安全带扣状态";
CM_ SG_ 80 SrsRi2ndBucSwtSts "第二排右安全带扣状态";
CM_ SG_ 80 SrsRi3rdBucSwtSts "第三排右安全带扣状态";
CM_ SG_ 80 SrsWarnLampSts "SRS故障信号（警告灯信号）";
CM_ BO_ 81 " ";
CM_ SG_ 81 SRS_CrashOut_Cedr "EDR触发输出";
CM_ SG_ 81 SRS_CrashOut_Front "正面碰撞输出";
CM_ SG_ 81 SRS_CrashOut_Left "侧面碰撞输出（左）";
CM_ SG_ 81 SRS_CrashOut_Micro "低风险碰撞输出";
CM_ SG_ 81 SRS_CrashOut_Rear "后面碰撞输出";
CM_ SG_ 81 SRS_CrashOut_Right "侧面碰撞输出（右）";
CM_ SG_ 81 SRS_CrashOut_Rollover "翻滚碰撞输出";
CM_ SG_ 81 SRS_CRCCheck_51 "051帧报文校验";
CM_ SG_ 81 SRS_RollingCounter_51 "051帧报文计数";
CM_ BO_ 338 " ";
CM_ SG_ 338 AD_Reqmode "请求控制方式";
CM_ SG_ 338 AD_ACCMode "ACC工作模式";
CM_ SG_ 338 AD_AEBActive "AEB减速激活";
CM_ SG_ 338 AD_CRCCheck_152 "AD_152校验和";
CM_ SG_ 338 AD_DynamicWarningLevel "动态预警等级";
CM_ SG_ 338 AD_ESSActive "ESS触发信号";
CM_ SG_ 338 AD_ESSStatus "ESS系统状态";
CM_ SG_ 338 AD_ESSWarning "ESS触发报警";
CM_ SG_ 338 AD_FCTBActive "FCTB激活";
CM_ SG_ 338 AD_LatAngReq "AD转向角请求";
CM_ SG_ 338 AD_LatAngReqActive "AD转向角请求激活";
CM_ SG_ 338 AD_LDWinhaitwaring "车道偏离预警惩罚模式告警";
CM_ SG_ 338 AD_LKAinhaitWarning "LKA惩罚模式告警";
CM_ SG_ 338 AD_LKAStatus "LKA状态";
CM_ SG_ 338 AD_REBStatus "REB功能状态";
CM_ SG_ 338 AD_RollingCounter_152 "AD_152计数器";
CM_ SG_ 338 AD_RunRedLightWaring "闯红灯提醒";
CM_ SG_ 338 AD_SafetyNotice "安全提示信息";
CM_ SG_ 338 ADC_SenceMode "当前场景模式";
CM_ SG_ 338 AEB_AWBActive "AWB激活";
CM_ SG_ 338 AD_C2Currenttemp "C2当前温度";
CM_ SG_ 338 AD_FlowReq "AD冷却液流速请求";
CM_ SG_ 338 AD_FlowReqValid "AD冷却液流速请求有效";
CM_ SG_ 338 AD_TmstempReq "AD目标冷却温度请求";
CM_ SG_ 338 AD_TmstempReqValid "AD目标冷却温度请求有效";
CM_ SG_ 338 ADR_TriggerEventReq "ADR事件触发";
CM_ BO_ 346 " ";
CM_ SG_ 346 EPB_AchievedClampForce_Secondary "EPB夹紧力_Secondary";
CM_ SG_ 346 EPB_FunctionLamp_Secondary "EPB功能指示灯_Secondary";
CM_ SG_ 346 EPB_Status_Secondray "EPB状态_Secondary";
CM_ SG_ 346 EpbFailrLamp_Secondary "EPB错误指示灯_Secondary";
CM_ SG_ 346 RPBCoorSec_CommunicationAvailabl "Secondary反馈通讯有效";
CM_ SG_ 346 RPBCoorSec_DiagModeActive "Secondary进入诊断模式";
CM_ SG_ 346 RPBCoorSec_HostAvailabilityFull "Sec_Host 全功能";
CM_ SG_ 346 RPBCoorSec_HostAvailabilityRelOn "Sec_Host 只允许释放";
CM_ SG_ 346 RPBCoorSec_reserved1 "CoorSecondary预留位1";
CM_ SG_ 346 RPBCoorSec_reserved2 "CoorSecondary预留位2";
CM_ SG_ 346 RPBCoorSec_reserved3 "CoorSecondary预留位3";
CM_ SG_ 346 VIU_FR_CRCCheck_15A "15A帧报文校验";
CM_ SG_ 346 VIU_FR_RollingCounter_15A "15A帧报文计数";
CM_ BO_ 349 " ";
CM_ SG_ 349 ESP_YawRateValid "偏航率有效位";
CM_ SG_ 349 ESP_LatAccel "横向加速度";
CM_ SG_ 349 ESP_LongAccel "纵向加速度";
CM_ SG_ 349 ESP_YawRate "偏航率";
CM_ SG_ 349 ESP_Calibrated "惯性信号标定状态";
CM_ SG_ 349 ESP_CRCCheck_15D "ESP_15D帧报文校验";
CM_ SG_ 349 ESP_LatAccelValid "横向加速度有效位";
CM_ SG_ 349 ESP_LongAccelValid "纵向加速度有效位";
CM_ SG_ 349 ESP_RollingCounter_15D "ESP_15D帧报文计数";
CM_ BO_ 353 " ";
CM_ SG_ 353 ESPVehSpd_Reference "ESP参考车速";
CM_ SG_ 353 ESP_ABAactive "ABA(自动制动辅助)激活";
CM_ SG_ 353 ESP_ABAavailable "ABA(自动制动辅助)可用";
CM_ SG_ 353 ESP_AEBAvailable "AEB(自动紧急制动)可用";
CM_ SG_ 353 ESP_AEBdecActive "AEB(自动紧急制动)激活";
CM_ SG_ 353 ESP_PrefillActive "预制动激活";
CM_ SG_ 353 ESP_PrefillAvailable "预制动有效";
CM_ SG_ 353 IBCU_BrakeDiscOverHeat "制动盘过热";
CM_ SG_ 353 IBCU_BrakeForce "制动系统压力";
CM_ SG_ 353 IBCU_CRCCheck_161 "161帧报文校验";
CM_ SG_ 353 IBCU_QDCSts "检测AD系统通讯异常（主CAN）";
CM_ SG_ 353 IBCU_RollingCounter_161 "161帧报文计数";
CM_ BO_ 355 " ";
CM_ SG_ 355 DMF_BrkForceTarDecActv "整车制动力减小请求激活";
CM_ SG_ 355 DMF_CrbsFailrSts "CRBS功能错误状态";
CM_ SG_ 355 DMF_BrkForceTarDec "整车制动力减小请求";
CM_ SG_ 355 DMF_VehTarForceReqMod "整车目标力请求模式";
CM_ SG_ 355 DMF_LeFrntTarBrkForceMod "左前目标制动力请求模式";
CM_ SG_ 355 DMF_RiFrntTarBrkForceMod "右前目标制动力请求模式";
CM_ SG_ 355 DMF_LeReTarBrkForceMod "左后目标制动力请求模式";
CM_ SG_ 355 DMF_RiReTarBrkForceMod "右后目标力制动请求模式";
CM_ SG_ 355 DMF_VehTarBrkForce "整车目标制动力";
CM_ SG_ 355 DMF_LeFrntTarBrkForce "左前轮目标制动力";
CM_ SG_ 355 DMF_RiFrntTarBrkForce "右前轮目标制动力";
CM_ SG_ 355 DMF_LeReTarBrkForce "左后轮目标制动力";
CM_ SG_ 355 DMF_RiReTarBrkForce "右后轮目标制动力";
CM_ SG_ 355 DMF_MainAdasSts "主ADAS系统状态";
CM_ SG_ 355 DMF_EscFctSts "ESC子功能激活状态";
CM_ SG_ 355 DMF_PrefillActvReq "DMF预充压请求";
CM_ SG_ 355 DMF_ReWhlDecTarTqActv "后轴降扭激活标志位";
CM_ SG_ 355 DMF_ReWhlDecTarTq "后轴降扭轮端扭矩";
CM_ SG_ 355 DMF_ReWhlIncTarTqActv "后轴增扭激活标志位";
CM_ SG_ 355 DMF_ReWhlIncTarTq "后轴增扭轮端扭矩";
CM_ SG_ 355 DMF_FrntWhlDecTarTqActv "前轴降扭激活标志位";
CM_ SG_ 355 DMF_FrntWhlDecTarTq "前轴降扭轮端扭矩";
CM_ SG_ 355 DMF_FrntWhlIncTarTqActv "前轴增扭激活标志位";
CM_ SG_ 355 DMF_FrntWhlIncTarTq "前轴增扭轮端扭矩";
CM_ SG_ 355 DMF_LeFrntWhlIncTarTqActv "左前轮增扭激活标志位";
CM_ SG_ 355 DMF_LeFrntWhlIncTarTq "左前轮增扭轮端扭矩";
CM_ SG_ 355 DMF_RiFrntWhlIncTarTqActv "右前轮增扭激活标志位";
CM_ SG_ 355 DMF_RiFrntWhlIncTarTq "右前轮增扭轮端扭矩";
CM_ SG_ 355 DMF_LeReWhlIncTarTqActv "左后轮增扭激活标志位";
CM_ SG_ 355 DMF_LeReWhlIncTarTq "左后轮增扭轮端扭矩";
CM_ SG_ 355 DMF_RiReWhlIncTarTqActv "右后轮增扭激活标志位";
CM_ SG_ 355 DMF_RiReWhlIncTarTq "右后轮增扭轮端扭矩";
CM_ SG_ 355 DMF_LeFrntWhlDecTarTqActv "左前轮降扭激活标志位";
CM_ SG_ 355 DMF_LeFrntWhlDecTarTq "左前轮降扭轮端扭矩";
CM_ SG_ 355 DMF_RiFrntWhlDecTarTqActv "右前轮降扭激活标志位";
CM_ SG_ 355 DMF_RiFrntWhlDecTarTq "右前轮降扭轮端扭矩";
CM_ SG_ 355 DMF_LeReWhlDecTarTqActv "左后轮降扭激活标志位";
CM_ SG_ 355 DMF_LeReWhlDecTarTq "左后轮降扭轮端扭矩";
CM_ SG_ 355 DMF_RiReWhlDecTarTqActv "右后轮降扭激活标志位";
CM_ SG_ 355 DMF_RiReWhlDecTarTq "右后轮降扭轮端扭矩";
CM_ SG_ 355 DMF_ADReqmode "AD请求控制方式";
CM_ SG_ 355 DMF_ADDriverlessReq "无人驾驶工作请求";
CM_ SG_ 355 DMF_ADAbaRankReq "ABA等级请求";
CM_ SG_ 355 DMF_ADAbaRankReqVld "ABA等级请求有效";
CM_ SG_ 355 DMF_ADSystemSts "AD系统状态";
CM_ SG_ 355 DMF_ADFctOpenSts "智驾功能开启状态";
CM_ SG_ 355 DmfEscReqRwsActv "ESC请求后轮转角激活";
CM_ SG_ 355 DmfEscRwsAgTar "ESC请求后轮转角";
CM_ SG_ 355 DmfDstwWhlAgOff "DSTW请求角度";
CM_ SG_ 355 DmfDstwActvSts "DSTW功能激活";
CM_ SG_ 355 DmfFrntWhlAg "前轮转角";
CM_ SG_ 355 DmfLgtSlopEst "坡度信号";
CM_ SG_ 355 DmfMueEstFil "附着系数估算";
CM_ SG_ 355 Dmf_RollingCounter_163 "163帧报文计数";
CM_ SG_ 355 Dmf_CRCCheck_163 "163帧报文校验";
CM_ BO_ 359 " ";
CM_ SG_ 359 EmsEngSpd "发动机转速";
CM_ SG_ 359 EmsEngCoolanT "发动机冷却液温度";
CM_ SG_ 359 EmsCoolanTErr "发动机冷却液温度故障";
CM_ BO_ 378 " ";
CM_ SG_ 378 IbBrkPedlStsGb "IBCU制动踏板状态(国标)";
CM_ SG_ 378 IbBrkPedlStsGbVld "IBCU制动踏板状态有效";
CM_ SG_ 378 IbBrkPedlTrvlDrvr "IBCU制动踏板机械行程";
CM_ SG_ 378 IbBrkPedlTrvlDrvrVld "IBCU制动踏板机械行程有效";
CM_ SG_ 378 ESP_pMcVirtual "虚拟主缸压力";
CM_ SG_ 378 IBCU_PlungerBrakePressure "助力缸制动压力";
CM_ SG_ 378 IBCU_PlungerBrakePressureValid "助力缸制动压力有效";
CM_ BO_ 384 " ";
CM_ SG_ 384 EpsSasSteerAg "方向盘转向角度";
CM_ SG_ 384 EpsSasSteerAgVld "方向盘转角有效";
CM_ SG_ 384 EpsSteerAgRate "方向盘转角速率";
CM_ SG_ 384 EPS_CRCCheck_180 "180帧报文校验";
CM_ SG_ 384 EPS_RollingCounter_180 "180帧报文计数";
CM_ SG_ 384 EpsSasCalSts "SAS标定状态";
CM_ SG_ 384 EpsSteerAgSensFilr "转角传感器失效";
CM_ BO_ 417 " ";
CM_ SG_ 417 VcuChrglockPosn2 "电子锁位置2";
CM_ SG_ 417 VcuChrglockPosn1 "电子锁位置1";
CM_ BO_ 419 " ";
CM_ SG_ 419 FrntMotSpd "前电机转速";
CM_ SG_ 419 FrntMotTqGb "前电机扭矩（国标）";
CM_ SG_ 419 FrntMotSpdVld "前电机转速有效位";
CM_ SG_ 419 FrntMotTq "前电机扭矩";
CM_ SG_ 419 FrntMotTqVld "前电机扭矩有效位";
CM_ BO_ 420 " ";
CM_ SG_ 420 ReMotSpd "后电机转速";
CM_ SG_ 420 ReMotSpdVld "后电机转速有效位";
CM_ SG_ 420 ReMotTq "后电机扭矩";
CM_ SG_ 420 ReMotTqVld "后电机扭矩有效位";
CM_ BO_ 421 " ";
CM_ SG_ 421 BcuChrgMod "电池充电模式";
CM_ BO_ 433 " ";
CM_ SG_ 433 PwrTrainSts "动力总成状态";
CM_ SG_ 433 VcuRdySts "整车可行驶状态";
CM_ SG_ 433 VcuGearPosn "整车实际挡位";
CM_ SG_ 433 VcuVehGearPosnVld "整车实际挡位有效";
CM_ SG_ 433 AcChrgHvActvReq "交流充电高压激活请求";
CM_ SG_ 433 DcAcHvActvReq "DCAC对外放电高压激活请求";
CM_ SG_ 433 DcChrgHvActvReq "直流充电高压激活请求";
CM_ SG_ 433 OTAHvActvReq "OTA高压激活请求";
CM_ SG_ 433 SrvAllwblReqSts "服务允许请求状态";
CM_ SG_ 433 VcuHvSysErrNr "高压系统故障代码";
CM_ SG_ 433 VehHvActvReq "整车高压激活请求";
CM_ SG_ 433 BrkgRgnMaxWhl "制动能量回收轮端允许最大扭矩";
CM_ SG_ 433 BrkgRgnMaxWhlVldSts "制动能量回收轮端允许最大扭矩有效状态";
CM_ SG_ 433 LePresSw "方向盘左中间按键状态";
CM_ SG_ 433 ReMotSpd "后电机转速";
CM_ SG_ 433 ReMotSpdVld "后电机转速有效位";
CM_ SG_ 433 RiPresSw "方向盘右中间按键状态";
CM_ SG_ 433 VCU_CRCCheck_1B1 "1B1帧报文校验";
CM_ SG_ 433 VCU_RollingCounter_1B1 "1B1帧报文计数";
CM_ SG_ 433 VCUAccPedShield "加速踏板屏蔽响应";
CM_ SG_ 433 VcuAccrMod "加速模式";
CM_ SG_ 433 VcuAccrPedlPosn "加速踏板实际位置";
CM_ SG_ 433 VcuAccrPedlPosnVld "加速踏板实际位置有效";
CM_ SG_ 433 VCUAPAdriverInterruption "驾驶员干预换挡";
CM_ SG_ 433 VCUAPARequestEnable "APA控制使能";
CM_ SG_ 433 VcuCalcnAccrPedlPosn "虚拟加速踏板位置";
CM_ SG_ 433 VcuCalcnAccrPedlPosnVld "虚拟加速踏板位置有效";
CM_ SG_ 433 VcuComFltSts "信息错误状态（检测到巡航系统信号错误）";
CM_ SG_ 433 VcuCrpFctSts "VCU蠕行功能状态";
CM_ SG_ 433 VcuDecToStopReq "VCU停车请求";
CM_ SG_ 433 VcuDrvrGearDmd "驾驶员目标挡位";
CM_ SG_ 433 VcuEnyRecyclMod "能量回收模式";
CM_ SG_ 433 VcuEpbReq "VCU电子手刹请求";
CM_ SG_ 433 VcuEpbReqVld "VCU电子手刹请求有效";
CM_ SG_ 433 VcuFrntMotSpd "前电机转速";
CM_ SG_ 433 VcuFrntMotSpdVld "前电机转速有效位";
CM_ SG_ 433 VcuFrntWhlActTq "前轴真实轮端扭矩";
CM_ SG_ 433 VcuFrntWhlActTqVld "前轴真实轮端扭矩有效";
CM_ SG_ 433 VcuFrntWhlReqTq "前轴需求轮端扭矩";
CM_ SG_ 433 VcuFrntWhlReqTqVld "前轴需求轮端扭矩有效";
CM_ SG_ 433 VcuMbRgnWhl "制动能量回收轮端实际扭矩";
CM_ SG_ 433 VcuMbRgnWhlVldSts "制动能量回收轮端实际扭矩有效状态";
CM_ SG_ 433 VcuObdType "OBD 类型";
CM_ SG_ 433 VcuOvrdModReq "超越模式请求";
CM_ SG_ 433 VcuPmuSleepReq "PMU休眠请求";
CM_ SG_ 433 VcuPmuSwtCloseAllowFlg "PMU开关允许闭合标志";
CM_ SG_ 433 VcuPtCoastRegenReqTq "动力系统滑行需求扭矩";
CM_ SG_ 433 VcuPtCoastRegenReqTqVld "动力系统滑行需求扭矩有效";
CM_ SG_ 433 VcuPtTqLimMax "动力总成最大允许输出扭矩";
CM_ SG_ 433 VcuPtTqLimMaxVld "动力总成最大允许输出扭矩有效";
CM_ SG_ 433 VcuPtTqLimMin "动力总成最小允许输出扭矩";
CM_ SG_ 433 VcuPtTqLimMinVld "动力总成最小允许输出扭矩有效";
CM_ SG_ 433 VcuPtTqReal "动力总成真实轮端扭矩";
CM_ SG_ 433 VcuPtTqRealVld "动力总成真实轮端扭矩有效";
CM_ SG_ 433 VcuPtTqReqAvl "动力系统扭矩可用状态（支持响应巡航和泊车）";
CM_ SG_ 433 VcuReWhlActTq "VCU后轴真实轮端扭矩";
CM_ SG_ 433 VcuReWhlActTqVld "VCU后轴真实轮端扭矩有效";
CM_ SG_ 433 VcuReWhlReqTq "后轴需求轮端扭矩";
CM_ SG_ 433 VcuReWhlReqTqVld "后轴需求轮端扭矩有效";
CM_ SG_ 433 VcuSimnEpbSwtSts "模拟EPB开关状态";
CM_ SG_ 433 VcuSimnEpbSwtStsVld "模拟EPB开关状态有效";
CM_ SG_ 433 VcuTarGearPosn "目标档位";
CM_ SG_ 433 VcuTrlrModActvSts "拖车模式激活状态";
CM_ SG_ 433 VcuVechicleType "车辆类型";
CM_ SG_ 433 VcuVehWhlReqTq "整车需求轮端扭矩";
CM_ SG_ 433 VcuVehWhlReqTqVld "整车需求轮端扭矩有效";
CM_ BO_ 450 " ";
CM_ SG_ 450 EspAbsActv "ABS激活";
CM_ SG_ 450 EspAbsFailr "ABS故障";
CM_ SG_ 450 EspActvSts "ESP激活状态";
CM_ SG_ 450 EspFctOpenSts "ESP功能开启状态";
CM_ SG_ 450 EspTcsActvSts "TCS激活状态";
CM_ SG_ 450 EspTcsFailr "TCS/ESP故障";
CM_ SG_ 450 EspVehSpd "车速信号";
CM_ SG_ 450 EspVehSpdVld "车速有效";
CM_ SG_ 450 EspDrvrBrkReqTq "驾驶员制动需求扭矩";
CM_ SG_ 450 ESP_CRCCheck_1C2 "1C2帧报文校验";
CM_ SG_ 450 ESP_RollingCounter_1C2 "1C2帧报文计数";
CM_ SG_ 450 EspEbdFailr "EBD故障";
CM_ SG_ 450 EspHDCSts "HDC工作状态";
CM_ SG_ 450 EspVdcActvSts "VDC激活状态";
CM_ SG_ 450 EspVehStandstill "车辆静止";
CM_ SG_ 450 IBCU_BrakeFluid_Warning "制动液位报警";
CM_ SG_ 450 MCBActv "MCB功能激活";
CM_ SG_ 450 MCBAvl "MCB功能可用";
CM_ SG_ 450 WhlSpdFrntLePls "左前轮速脉冲";
CM_ SG_ 450 WhlSpdFrntRiPls "右前轮速脉冲";
CM_ SG_ 450 WhlSpdLeFrntData "左前轮速信号";
CM_ SG_ 450 WhlSpdLeFrntDataVld "左前轮速数据有效";
CM_ SG_ 450 WhlSpdLeFrntDir "左前轮方向信号";
CM_ SG_ 450 WhlSpdLeReData "左后轮速信号";
CM_ SG_ 450 WhlSpdLeReDataVld "左后轮速数据有效";
CM_ SG_ 450 WhlSpdLeReDir "左后轮方向信号";
CM_ SG_ 450 WhlSpdReLePls "左后轮速脉冲";
CM_ SG_ 450 WhlSpdReRiPls "右后轮速脉冲";
CM_ SG_ 450 WhlSpdRiFrntData "右前轮速信号";
CM_ SG_ 450 WhlSpdRiFrntDataVld "右前轮速数据有效";
CM_ SG_ 450 WhlSpdRiFrntDir "右前轮方向信号";
CM_ SG_ 450 WhlSpdRiReData "右后轮速信号";
CM_ SG_ 450 WhlSpdRiReDataVld "右后轮速数据有效";
CM_ SG_ 450 WhlSpdRiReDir "右后轮方向信号";
CM_ SG_ 450 EspAutoHoldActvSts "AutoHold功能状态";
CM_ SG_ 450 EspBrkSysFltLamp "IBCU基础系统故障灯";
CM_ SG_ 450 IBCU_iDCSAvlblSts "iDCS功能可用状态";
CM_ SG_ 450 IBCU_iDCSLevFd "iDCS强度反馈";
CM_ SG_ 450 IBCU_iDCS_State "iDCS工作状态";
CM_ BO_ 452 " ";
CM_ SG_ 452 EMB_Pri_SystemFlt "系统状态（主控）";
CM_ SG_ 452 EMB_Pri_BrkRodStrk "制动踏板开度 - 主";
CM_ SG_ 452 EMB_Pri_BrkRodStrkVld "制动踏板开度有效性-主";
CM_ SG_ 452 EMB_RollingCounter_1C4 "EMB_1C4计数器";
CM_ SG_ 452 EMB_CRCCheck__1C4 "EMB_1C4校验和";
CM_ SG_ 452 EMBParkPriCtrlEnableRL "左后驻车控制使能（主控）";
CM_ SG_ 452 EMBParkPriCtrlEnableRR "右后驻车控制使能（主控）";
CM_ SG_ 452 EMBParkPriAvailabilityRL "左后驻车可操作状态（主控）";
CM_ SG_ 452 EMBParkPriAvailabilityRR "右后驻车可操作状态（主控）";
CM_ SG_ 452 EMBParkPriCtrlSourceRL "左后驻车请求源（主控）";
CM_ SG_ 452 EMBParkPriCtrlSourceRR "右后驻车请求源（主控）";
CM_ SG_ 452 EMBParkPriEpbStatusRL "左后驻车状态（主控）";
CM_ SG_ 452 EMBParkPriEpbStatusRR "右后驻车状态（主控）";
CM_ SG_ 452 EMBParkPriFctLampRL "左后驻车功能指示灯（主控）";
CM_ SG_ 452 EMBParkPriFctLampRR "右后驻车功能指示灯（主控）";
CM_ SG_ 452 EMBParkPriFailrLampRL "左后驻车错误指示灯（主控）";
CM_ SG_ 452 EMBParkPriFailrLampRR "右后驻车错误指示灯（主控）";
CM_ SG_ 452 EMBPriVehBrkSysSts "整车降级制动校验状态（主控）";
CM_ BO_ 453 " ";
CM_ SG_ 453 EMB_Sec_SystemFlt "系统状态（辅控）";
CM_ SG_ 453 EMB_Sec_BrkRodStrk "制动踏板开度 - 辅";
CM_ SG_ 453 EMB_Sec_BrkRodStrkVld "制动踏板开度有效性-辅";
CM_ SG_ 453 EMB_RollingCounter_1C5 "EMB_1C5计数器";
CM_ SG_ 453 EMB_CRCCheck__1C5 "EMB_1C5校验和";
CM_ SG_ 453 EMBParkSecCtrlEnableRL "左后驻车控制使能（辅控）";
CM_ SG_ 453 EMBParkSecCtrlEnableRR "右后驻车控制使能（辅控）";
CM_ SG_ 453 EMBParkSecAvailabilityRL "左后驻车可操作状态（辅控）";
CM_ SG_ 453 EMBParkSecAvailabilityRR "右后驻车可操作状态（辅控）";
CM_ SG_ 453 EMBParkSecCtrlSourceRL "左后驻车请求源（辅控）";
CM_ SG_ 453 EMBParkSecCtrlSourceRR "右后驻车请求源（辅控）";
CM_ SG_ 453 EMBParkSecEpbStatusRL "左后驻车状态（辅控）";
CM_ SG_ 453 EMBParkSecEpbStatusRR "右后驻车状态（辅控）";
CM_ SG_ 453 EMBParkSecFctLampRL "左后驻车功能指示灯（辅控）";
CM_ SG_ 453 EMBParkSecFctLampRR "右后驻车功能指示灯（辅控））";
CM_ SG_ 453 EMBParkSecFailrLampRL "左后驻车错误指示灯（辅控）";
CM_ SG_ 453 EMBParkSecFailrLampRR "右后驻车错误指示灯（辅控）";
CM_ SG_ 453 EMBSecVehBrkSysSts "整车降级制动校验状态（辅控）";
CM_ BO_ 467 " ";
CM_ SG_ 467 ESP_LongAccelValid_1 "纵向加速度有效位";
CM_ SG_ 467 ESP_LatAccelValid_1 "横向加速度有效位";
CM_ SG_ 467 ESP_YawRateValid_1 "偏航率有效位";
CM_ SG_ 467 ESP_LatAccel_1 "横向加速度";
CM_ SG_ 467 ESP_LongAccel_1 "纵向加速度";
CM_ SG_ 467 ESP_RollingCounter_1D3 "1D3帧报文计数";
CM_ SG_ 467 ESP_YawRate_1 "偏航率";
CM_ SG_ 467 ESP_CRCCheck_1D3 "1D3帧报文校验";
CM_ BO_ 500 " ";
CM_ SG_ 500 FrntGerTq "前发电机扭矩";
CM_ BO_ 513 " ";
CM_ SG_ 513 AD_DDSATextInfo "DDSA提示信息";
CM_ SG_ 513 ADS_AcrBeltShake "主动安全带振动请求";
CM_ BO_ 642 " ";
CM_ SG_ 642 CPEVTar_v2g_SupAppResSchemaID "EVSE支持的DIN/ISO充电协议ID";
CM_ SG_ 642 CPEVTar_v2g_CurDemResReCnt "充电中Req-Res过程消息超时次数";
CM_ SG_ 642 Switch_S2_State "输出开关S2";
CM_ SG_ 642 Switch_K3_State "输出开关K3";
CM_ SG_ 642 Switch_CC2_State "输出开关CC2";
CM_ SG_ 642 App_Version_V "软件版本V版本号";
CM_ SG_ 642 App_Version_D "软件版本D版本号";
CM_ SG_ 642 App_Version_B "软件版本B版本号";
CM_ SG_ 642 Eu_ChargingStage "欧标流程的阶段";
CM_ SG_ 642 Gb_ChargingState "国标当前状态";
CM_ SG_ 642 Gb_ChargingEvent "国标当前事件";
CM_ SG_ 642 KL30voltage "KL30电压采样";
CM_ SG_ 642 KL15voltage "KL15电压采样";
CM_ SG_ 642 K3voltage "K3电压采样";
CM_ SG_ 642 ComPam1_v2g_DC_EVSs_EVErrCd "EV内部错误";
CM_ SG_ 642 CPEVSEVol_v2g_DC_EVSESsCd "EVSE状态";
CM_ SG_ 642 ComPam1_v2g_ResponseCode "EVSE响应码";
CM_ SG_ 642 CPEVSEVol_v2g_DCEVSEIsolSs "EVSE绝缘状态";
CM_ SG_ 642 CPEVSECur_v2g_EVSEProc "EVSE动作流程处理结果";
CM_ SG_ 642 CPEVSEPre_v2g_ChgProg "EVSE被请求启动/停止/协商的命令";
CM_ SG_ 642 chgpam4_v2g_res_procID1 "EVCC状态信息";
CM_ SG_ 642 EVCC_ChargingActionCode "EVCC充电动作";
CM_ SG_ 642 EVCC_CP_State "CP状态";
CM_ SG_ 642 EVCC_CP_DutyChange "CP占空比切换类型";
CM_ SG_ 642 EVCC_CP_Duty "CP占空比采样";
CM_ SG_ 642 EVCC_CP_Freq "CP频率采样";
CM_ SG_ 642 EVCC_CP_VoltageChange "CP电压切换类型";
CM_ SG_ 642 EVCC_CP_Voltage "CP电压采样";
CM_ SG_ 642 CPEVSEVol_v2g_MessSet "ChargeParameterDiscoveryReq消息";
CM_ SG_ 642 EVCC_CC2_Voltage "CC2电压采样";
CM_ SG_ 642 CPEVTar_v2g_ChgComplete "EV已完成满充";
CM_ SG_ 642 EvccS2Sts "S2开关状态";
CM_ SG_ 642 EVCC_RollingCounter_282 "282帧报文计数";
CM_ SG_ 642 EVCC_CRCCheck_282 "282帧报文校验";
CM_ BO_ 648 " ";
CM_ SG_ 648 ActualDrvMod "当前驾驶模式";
CM_ SG_ 648 BCM_DrivDoorLockSts "驾驶侧门锁状态信号";
CM_ SG_ 648 BCM_HoodStatus "发动机舱盖状态";
CM_ SG_ 648 BCM_TurnLightSwitchSts "转向灯开关状态信号";
CM_ SG_ 648 BcmAuLiSwtSts "自动大灯开关状态";
CM_ SG_ 648 BcmDrvrDoorSts "左前门状态";
CM_ SG_ 648 BcmEmgyLiSts "紧急报警灯状态";
CM_ SG_ 648 BcmHiBeSwtSts "远光灯开关状态";
CM_ SG_ 648 BcmKeyAlrmSts "警戒状态信息";
CM_ SG_ 648 BcmLeReDoorSts "左后门状态";
CM_ SG_ 648 BcmLoBeSwtSts "近光灯开关状态";
CM_ SG_ 648 BcmOvTaLiSwtSts "超车灯开关状态";
CM_ SG_ 648 BcmPassDoorSts "右前门状态";
CM_ SG_ 648 BcmPwrStsFb "电源状态反馈";
CM_ SG_ 648 BcmRiReDoorSts "右后门状态";
CM_ SG_ 648 BcmTurnIndcrLe "左转向灯信号";
CM_ SG_ 648 BcmTurnIndcrRi "右转向灯信号";
CM_ SG_ 648 BdcDrvrSts "主驾座椅人员状态";
CM_ SG_ 648 LoChrgSts "智能补电运行状态";
CM_ SG_ 648 VIU_DriverADEDSts "驾驶侧警告灯状态";
CM_ SG_ 648 VIU_FL_CRCCheck_288 "288帧报文校验";
CM_ SG_ 648 VIU_FL_RollingCounter_288 "288帧报文计数";
CM_ SG_ 648 VIU_PassengerADEDSts "乘员侧警告灯状态";
CM_ SG_ 648 VIUACModReq "空调模式请求";
CM_ SG_ 648 WakeUpForbidden "唤醒源禁用标志";
CM_ BO_ 674 " ";
CM_ SG_ 674 ACP_ActualSpeed "电动压缩机实际运转速度";
CM_ BO_ 677 " ";
CM_ SG_ 677 BcuSocDisp "电池显示电量";
CM_ SG_ 677 BcuBattHeatActv "电池加热激活";
CM_ SG_ 677 DcChrgCnctrSts "直流枪状态";
CM_ BO_ 680 " ";
CM_ SG_ 680 TmsAcEnvtlT "车外温度信号";
CM_ SG_ 680 TmsAcEnvtlTVld "车外温度有效";
CM_ SG_ 680 TmsAcpActSpd "压缩机实际转速反馈";
CM_ SG_ 680 TmsAcpActPwr "电动压缩机功率消耗";
CM_ BO_ 681 " ";
CM_ SG_ 681 ObcS2Ctrl "S2开关控制";
CM_ SG_ 681 Obc_CRCCheck_2A9 "2A9帧报文校验";
CM_ SG_ 681 Obc_RollingCounter_2A9 "2A9帧报文计数";
CM_ BO_ 689 " ";
CM_ SG_ 689 AMP_AVASSoundSourceStatus "AVAS音源状态";
CM_ SG_ 689 AMP_KTVSoundSourceStatus "KTV音源状态";
CM_ SG_ 689 AMP_LFWarnSoundSourceStatus "左前报警提示音源状态";
CM_ SG_ 689 AMP_LRWarnSoundSourceStatus "左后报警提示音源状态";
CM_ SG_ 689 AMP_MediaSoundSourceStatus "多媒体音源状态";
CM_ SG_ 689 AMP_MidWarnSoundSourceStatus "中置报警提示音源状态";
CM_ SG_ 689 AMP_NAVISoundSourceStatus "导航音源状态";
CM_ SG_ 689 AMP_OutSoundSourceStatus "车外声音音源状态";
CM_ SG_ 689 AMP_RFWarnSoundSourceStatus "右前报警提示音源状态";
CM_ SG_ 689 AMP_RRWarnSoundSourceStatus "右后报警提示音源状态";
CM_ SG_ 689 AMP_SystemSoundSourceStatus "系统提示音源状态";
CM_ SG_ 689 AMP_TELSoundSourceStatus "蓝牙电话音源状态";
CM_ SG_ 689 AMP_TurnLightSoundSourceStatus "转向灯音音源状态";
CM_ SG_ 689 AMP_VRSoundSourceStatus "语音交互音源状态";
CM_ BO_ 690 " ";
CM_ SG_ 690 VcuDcChrgLckReq "直流电子锁解闭锁请求";
CM_ BO_ 699 " ";
CM_ SG_ 699 AD_APASysEnaSta "泊车系统功能开启状态";
CM_ SG_ 699 AD_APAOnOff "APA功能开启状态";
CM_ BO_ 722 " ";
CM_ SG_ 722 AcRemStartSts "空调远程控制标志位";
CM_ SG_ 722 CDC_CRCCheck_2D2 "2D2帧报文校验";
CM_ SG_ 722 CDC_RollingCounter_2D2 "2D2帧报文计数";
CM_ SG_ 722 CdcAcChrgILimSet "交流充电电流限值设置";
CM_ SG_ 722 CdcAntiRustFctSet "制动盘除锈功能设置状态";
CM_ SG_ 722 CdcAqsOpenSet "AQS开启请求";
CM_ SG_ 722 CdcAutoApplyFctSet "AutoApply功能设置状态";
CM_ SG_ 722 CdcAutoDefrstDefogStsReq "自动除霜除雾设定请求信号";
CM_ SG_ 722 CdcAutoWindLongPressSet "钥匙长按通风设置";
CM_ SG_ 722 CdcAutoWindUnlockSet "钥匙开锁通风设置";
CM_ SG_ 722 CdcAVHFctSet "AVH功能设置状态";
CM_ SG_ 722 CdcBacktWindLvlSetReq "后排风量设定请求（风口）";
CM_ SG_ 722 CdcBattPlsHeatgSet "电池即时加热设置请求";
CM_ SG_ 722 CdcBDWFctSet "BDW功能设置状态";
CM_ SG_ 722 CdcBrkPedlModSet "制动踏板感模式设置";
CM_ SG_ 722 CdcCycModSet "循环模式设定请求";
CM_ SG_ 722 CdcDrvrTSet "主驾温度设定请求";
CM_ SG_ 722 CdcEpbSwtSet "CDC电子手刹开关设置";
CM_ SG_ 722 CdcEspFctSet "ESP功能设置状态";
CM_ SG_ 722 CdcFrntAutModOpenSet "前排空调自动模式设定请求";
CM_ SG_ 722 CdcFrntBlowModSet "前出风模式设定请求";
CM_ SG_ 722 CdcFrntDefrosterSet "前除霜模式设定请求";
CM_ SG_ 722 CdcFrntWindLvlSet "前排风量设定请求";
CM_ SG_ 722 CdcFrontAcOffSet "前排空调开启/关闭请求";
CM_ SG_ 722 CdcHDCFctSet "HDC功能设置状态";
CM_ SG_ 722 CdcHotColdModStReq "制冷制热模式设定请求";
CM_ SG_ 722 CdcIBCUDrvModSet "IBCU模式设置";
CM_ SG_ 722 CdcORCAFctSet "坦克掉头功能设置状态";
CM_ SG_ 722 CdcPassTSet "副驾温度设定请求";
CM_ SG_ 722 CdcPlasmaOpenSet "离子发生器控制请求";
CM_ SG_ 722 CdcSteerModSet "助力转向模式设置";
CM_ SG_ 722 CdcTotMilg "总里程信号";
CM_ SG_ 722 CdcVehEgyCnseSelect "能耗选项";
CM_ SG_ 722 CdcVentnOnSet "定时通风开启请求";
CM_ SG_ 722 CdcWorkSpaceSet "温区设定同步请求";
CM_ SG_ 722 CST_OFF_Switch "CST功能设置开关";
CM_ SG_ 722 HU_ACRearFanAdjustValueReq "后排风量设定请求信号";
CM_ SG_ 722 HU_ACRearModeAdjustReq "后排出风模式设定请求信号";
CM_ SG_ 722 HU_ACRearTempAdjustValueReq2 "后排温度设定信号2";
CM_ SG_ 722 HU_AutowindSet3 "空调自干燥设置";
CM_ SG_ 722 HU_MaxACReq "最大制冷开启请求";
CM_ SG_ 722 HU_MaxDefReq "最大除霜开启请求";
CM_ SG_ 722 HU_MaxHeatReq "最大制热开启请求";
CM_ SG_ 722 HU_RearACOfffReq "后排空调开启/关闭请求信号";
CM_ SG_ 722 HU_RearAUTOACOnReq "后排空调自动模式开启请求信号";
CM_ SG_ 722 HU_RefreshModeEnable "清醒提神模式设置信号";
CM_ SG_ 722 HU_Request_AFUchannel "香氛通道选择";
CM_ SG_ 722 HU_Request_AFUContentleve "香氛浓度控制";
CM_ SG_ 722 HU_Request_AFUSt "香氛开启请求";
CM_ SG_ 722 HU_RollerbenchSetStaus "测功机模式目标状态";
CM_ SG_ 722 HU_VentilationSetAfternoon "定时通风设定下午";
CM_ SG_ 722 HU_VentilationSetEvening "定时通风设定晚上";
CM_ SG_ 722 HU_VentilationSetMorning "定时通风设定上午";
CM_ SG_ 722 HUAcEgySaveModReq "空调节能模式设置请求";
CM_ SG_ 722 HUAutoAirCleanReq "自动空气净化设置请求";
CM_ SG_ 722 HUBatPulseHeatSwitchReq "电池脉冲加热开关设置";
CM_ SG_ 722 HUMotLockHeatSwitchReq "电机堵转加热开关设置";
CM_ SG_ 722 HUSngPrsnModReq "单人模式设置请求";
CM_ SG_ 722 VIUDrvModSet "驾驶模式设置";
CM_ BO_ 753 " ";
CM_ SG_ 753 RCM_RLTuLiSt "左后转向灯状态";
CM_ SG_ 753 RCM_RRTuLiSt "右后转向灯状态";
CM_ BO_ 759 " ";
CM_ SG_ 759 TboxLocalTiDate "本地时间日";
CM_ SG_ 759 TboxLocalTiHr "本地时间时";
CM_ SG_ 759 TboxLocalTiMins "本地时间分";
CM_ SG_ 759 TboxLocalTiMth "本地时间月";
CM_ SG_ 759 TboxLocalTiSec "本地时间秒";
CM_ SG_ 759 TboxLocalTiVld "本地时间有效位";
CM_ SG_ 759 TboxLocalTiYear "本地时间年";
CM_ BO_ 760 " ";
CM_ SG_ 760 Tbox_GPSLocalTiDate "GPS时间日";
CM_ SG_ 760 Tbox_GPSLocalTiHr "GPS时间时";
CM_ SG_ 760 Tbox_GPSLocalTiMins "GPS时间分";
CM_ SG_ 760 Tbox_GPSLocalTiMth "GPS时间月";
CM_ SG_ 760 Tbox_GPSLocalTiSec "GPS时间秒";
CM_ SG_ 760 Tbox_GPSLocalTiVld "GPS时间有效位";
CM_ SG_ 760 Tbox_GPSLocalTiYear "GPS时间年";
CM_ BO_ 774 " ";
CM_ SG_ 774 AC_ACOnOff "空调工作状态";
CM_ SG_ 774 ITMSLiquidLevel "液位传感器";
CM_ SG_ 774 TmsComOutPtPre "压缩机出口PT传感器压力信号";
CM_ BO_ 779 " ";
CM_ SG_ 779 CDC_CRCCheck_30B "30B帧报文校验";
CM_ SG_ 779 CDC_RollingCounter_30B "30B帧报文计数";
CM_ SG_ 779 CdcIPScreenLiOnSts "仪表亮灭状态";
CM_ SG_ 779 IP_DISFail "仪表故障";
CM_ SG_ 779 IP_juADASshowinfa "IP判断影响ADAS正常显示的自身故障输出信号";
CM_ SG_ 779 IP_juADASshowoutfa "IP判断影响ADAS正常显示的外部故障输出信号";
CM_ SG_ 779 IP_juADAStsE2Efaout "IP判断ADAS信号E2E校验故障输出信号";
CM_ SG_ 779 IP_QDashACCFail "仪表检测到ACC发出的信息有误（例如timeout）";
CM_ SG_ 779 AD_EDCCrtSts "EDC工作状态";
CM_ SG_ 779 AD_EDCCurrenttemp "EDC当前温度";
CM_ SG_ 779 TboxDoorLockRemCtrlReq "远程解闭锁请求";
CM_ BO_ 784 " ";
CM_ SG_ 784 AMP_Err_Detect "外置功放错误检测";
CM_ SG_ 784 AMP_FLHighSpeakerDelaySETStatus "前左高音扬声器延时设置状态";
CM_ SG_ 784 AMP_FLHighSpeakerVolSETStatus "前左高音扬声器增益设置状态";
CM_ SG_ 784 AMP_FLMidSpeakerDelaySETStatus "前左中音扬声器延时设置状态";
CM_ SG_ 784 AMP_FLMidSpeakerVolSETStatus "前左中音扬声器增益设置状态";
CM_ SG_ 784 AMP_FRHighSpeakerDelaySETStatus "前右高音扬声器延时设置状态";
CM_ SG_ 784 AMP_FRHighSpeakerVolSETStatus "前右高音扬声器增益设置状态";
CM_ SG_ 784 AMP_FRMidSpeakerDelaySETStatus "前右中音扬声器延时设置状态";
CM_ SG_ 784 AMP_FRMidSpeakerVolSETStatus "前右中音扬声器增益设置状态";
CM_ SG_ 784 AMP_Slot_Detect "外置功放slot通道监测";
CM_ SG_ 784 AMP_SV_Detect "外置功放内部版本监测";
CM_ SG_ 784 AMP_AlarmVolSETStatus "报警音音量设置状态";
CM_ SG_ 784 AMP_AvasVolSETStatus "车外行人警示音音量设置状态";
CM_ SG_ 784 AMP_CenterSpeakerDelaySETStatus "中置扬声器延时设置状态";
CM_ SG_ 784 AMP_CenterSpeakerVolSETStatus "中置扬声器增益设置状态";
CM_ SG_ 784 AMP_CustomEffectSETStatus "自定义音效设置状态";
CM_ SG_ 784 AMP_CustomEQ125SET "自定义125Hz频段设置状态";
CM_ SG_ 784 AMP_CustomEQ16KSET "自定义16000Hz频段设置状态";
CM_ SG_ 784 AMP_CustomEQ1KSET "自定义1000Hz频段设置状态";
CM_ SG_ 784 AMP_CustomEQ250SET "自定义250Hz频段设置状态";
CM_ SG_ 784 AMP_CustomEQ2KSET "自定义2000Hz频段设置状态";
CM_ SG_ 784 AMP_CustomEQ4KSET "自定义4000Hz频段设置状态";
CM_ SG_ 784 AMP_CustomEQ500SET "自定义500Hz频段设置状态";
CM_ SG_ 784 AMP_CustomEQ62SET "自定义62Hz频段设置状态";
CM_ SG_ 784 AMP_CustomEQ8KSET "自定义8000Hz频段设置状态";
CM_ SG_ 784 AMP_FLLowSpeakerDelaySETStatus "前左低音扬声器延时设置状态";
CM_ SG_ 784 AMP_FLLowSpeakerVolSETStatus "前左低音扬声器增益设置状态";
CM_ SG_ 784 AMP_FLMidHighSpeakerDelaySETStat "前左中高音扬声器延时设置状态";
CM_ SG_ 784 AMP_FLMidHighSpeakerVolSETStatus "前左中高音扬声器增益设置状态";
CM_ SG_ 784 AMP_FLTopSpeakerDelaySETStatus "前左顶棚扬声器延时设置状态";
CM_ SG_ 784 AMP_FLTopSpeakerVolSETStatus "前左顶棚扬声器增益设置状态";
CM_ SG_ 784 AMP_FRBalanceSETStatus "声场前后平衡设置状态";
CM_ SG_ 784 AMP_FRLowSpeakerDelaySETStatus "前右低音扬声器延时设置状态";
CM_ SG_ 784 AMP_FRLowSpeakerVolSETStatus "前右低音扬声器增益设置状态";
CM_ SG_ 784 AMP_FRMidHighSpeakerDelaySET "前右中高音扬声器延时设置状态";
CM_ SG_ 784 AMP_FRMidHighSpeakerVolSETStatus "前右中高音扬声器增益设置状态";
CM_ SG_ 784 AMP_FRTopSpeakerDelaySETStatus "前右顶棚扬声器延时设置状态";
CM_ SG_ 784 AMP_FRTopSpeakerVolSETStatus "前右顶棚扬声器增益设置状态";
CM_ SG_ 784 AMP_KTVMUTESETStatus "KTV人声静音设置状态";
CM_ SG_ 784 AMP_KTVVolSETStatus "KTV人声音量设置状态";
CM_ SG_ 784 AMP_LRBalanceSETStatus "声场左右平衡设置状态";
CM_ SG_ 784 AMP_MediaMUTESETStatus "多媒体静音设置状态";
CM_ SG_ 784 AMP_MediaVolSETStatus "多媒体音量设置状态";
CM_ SG_ 784 AMP_MUTESETStatus "全部静音设置状态";
CM_ SG_ 784 AMP_NaviMUTESETStatus "导航静音设置状态";
CM_ SG_ 784 AMP_NAVIVolSETStatus "导航播报音量设置状态";
CM_ SG_ 784 AMP_OutMUTESETStatus "车外声音静音设置状态";
CM_ SG_ 784 AMP_OUTVolSETStatus "车外声音音量设置状态";
CM_ SG_ 784 AMP_PerfessiionalEQ100SET "专业自定义100Hz频段设置状态";
CM_ SG_ 784 AMP_PerfessiionalEQ500SET "专业自定义500Hz频段设置状态";
CM_ SG_ 784 AMP_PerfessiionalEQ6KSET "专业自定义6000Hz频段设置状态";
CM_ SG_ 784 AMP_RLLowHighSpeakerDelaySETStat "后左低高音扬声器延时设置状态";
CM_ SG_ 784 AMP_RLLowHighSpeakerVolSETStatus "后左低高音扬声器增益设置状态";
CM_ SG_ 784 AMP_RLSurroundSpeakerDelaySETSta "后左环绕扬声器延时设置状态";
CM_ SG_ 784 AMP_RLSurroundSpeakerVolSETStatu "后左环绕扬声器增益设置状态";
CM_ SG_ 784 AMP_RLTopSpeakerDelaySETStatus "后左顶棚扬声器延时设置状态";
CM_ SG_ 784 AMP_RLTopSpeakerVolSETStatus "后左顶棚扬声器增益设置状态";
CM_ SG_ 784 AMP_RNCEnableSETStatus "主动路噪降噪功能设置状态";
CM_ SG_ 784 AMP_RRLowHighSpeakerDelaySET "后右低高音扬声器延时设置状态";
CM_ SG_ 784 AMP_RRLowHighSpeakerVolSETStatus "后右低高音扬声器增益设置状态";
CM_ SG_ 784 AMP_RRSurroundSpeakerDelaySETSta "后右环绕扬声器延时设置状态";
CM_ SG_ 784 AMP_RRSurroundSpeakerVolSET "后右环绕扬声器增益设置状态";
CM_ SG_ 784 AMP_RRTopSpeakerDelaySETStatus "后右顶棚扬声器延时设置状态";
CM_ SG_ 784 AMP_RRTopSpeakerVolSETStatus "后右顶棚扬声器增益设置状态";
CM_ SG_ 784 AMP_SoundEffectSETStatus "音效设置状态";
CM_ SG_ 784 AMP_SoundFieldSETStatus "声场设置状态";
CM_ SG_ 784 AMP_SubSpeakerDelaySETStatus "重低音扬声器延时设置状态";
CM_ SG_ 784 AMP_SubSpeakerVolSETStatus "重低音扬声器增益设置状态";
CM_ SG_ 784 AMP_SystemMUTESETStatus "系统提示音静音设置状态";
CM_ SG_ 784 AMP_SystemVolSETStatus "系统提示音量设置状态";
CM_ SG_ 784 AMP_TelBcallMUTESETStatus "电话/Bcall静音设置状态";
CM_ SG_ 784 AMP_TELBCALLVolSETStatus "蓝牙电话音量/becall音量设置状态";
CM_ SG_ 784 AMP_TTSVRMUTESETStatus "TTS/语音静音设置状态";
CM_ SG_ 784 AMP_TTSVRVolSETStatus "TTS/语音音量设置状态";
CM_ SG_ 784 AMP_TurnLightInOrOutSETStatus "转向灯音车内外设置状态";
CM_ SG_ 784 AMP_TurnLightVolSETStatus "转向灯音音量设置状态";
CM_ SG_ 784 AMP_VOLSpeedEnableSETStatus "音量随速调节功能设置状态";
CM_ BO_ 800 " ";
CM_ SG_ 800 AMPFLPositionDelaySETStatus "前左方位延时设置状态";
CM_ SG_ 800 AMPFLPositionVolSETStatus "前左方位增益设置状态";
CM_ SG_ 800 AMPFRPositionDelaySETStatus "前右方位延时设置状态";
CM_ SG_ 800 AMPFRPositionVolSETStatus "前右方位增益设置状态";
CM_ SG_ 800 AMPBeosonicModeSetStatus "Beosonic模式设置状态";
CM_ SG_ 800 AMPBeosonicXSetStatus "BeosonicX轴参数设置状态";
CM_ SG_ 800 AMPBeosonicYSetStatus "BeosonicY轴参数设置状态";
CM_ SG_ 800 AMPCenterPositionDelaySETStatus "中置方位延时设置状态";
CM_ SG_ 800 AMPCenterPositionVolSETStatus "中置方位增益设置状态";
CM_ SG_ 800 AMPCustomEQ2500SET "自定义2500Hz频段设置状态";
CM_ SG_ 800 AMPCustomEQ315SET "自定义315Hz频段设置状态";
CM_ SG_ 800 AMPCustomEQ50SET "自定义50Hz频段设置状态";
CM_ SG_ 800 AMPCustomEQ6000SET "自定义6000Hz频段设置状态";
CM_ SG_ 800 AMPCustomEQ800SET "自定义800Hz频段设置状态";
CM_ SG_ 800 AMPFLTopPositionDelaySETStatus "前左天空方位延时设置状态";
CM_ SG_ 800 AMPFLTopPositionVolSETStatus "前左天空方位增益设置状态";
CM_ SG_ 800 AMPFRTopPositionDelaySETStatus "前右天空方位延时设置状态";
CM_ SG_ 800 AMPFRTopPositionVolSETStatus "前右天空方位增益设置状态";
CM_ SG_ 800 AMPRLPositionDelaySETStatus "后左方位延时设置状态";
CM_ SG_ 800 AMPRLPositionVolSETStatus "后左方位增益设置状态";
CM_ SG_ 800 AMPRLSurroundDelaySETStatus "后左环绕方位延时设置状态";
CM_ SG_ 800 AMPRLSurroundVolSETStatus "后左环绕方位增益设置状态";
CM_ SG_ 800 AMPRLTopDelaySETStatus "后左天空方位延时设置状态";
CM_ SG_ 800 AMPRLTopVolSETStatus "后左天空方位增益设置状态";
CM_ SG_ 800 AMPRRPositionDelaySET "后右方位延时设置状态";
CM_ SG_ 800 AMPRRPositionVolSETStatus "后右方位增益设置状态";
CM_ SG_ 800 AMPRRSurroundPositionDelaySETSta "后右环绕方位延时设置状态";
CM_ SG_ 800 AMPRRSurroundPositionVolSET "后右环绕方位增益设置状态";
CM_ SG_ 800 AMPRRTopPositionDelaySETStatus "后右天空方位延时设置状态";
CM_ SG_ 800 AMPRRTopPositionVolSETStatus "后右天空方位增益设置状态";
CM_ SG_ 800 AMPSoundSourceTypeStatus "音源类型状态";
CM_ SG_ 800 AMPSubPositionDelaySETStatus "重低音方位延时设置状态";
CM_ SG_ 800 AMPSubPositionVolSETStatus "重低音方位增益设置状态";
CM_ SG_ 800 AMPTMCenterPositionEQ15000HzSetS "中置方位15000Hz频段设置状态（调音大师）";
CM_ SG_ 800 AMPTMCenterPositionEQ800HzSetSta "中置方位800Hz频段设置状态（调音大师）";
CM_ SG_ 800 AMPTMFLPositionEQ100HzSetStatus "前左方位100Hz频段设置状态（调音大师）";
CM_ SG_ 800 AMPTMFLPositionEQ15000HzSetStatu "前左方位15000Hz频段设置状态（调音大师）";
CM_ SG_ 800 AMPTMFLPositionEQ800HzSetStatus "前左方位800Hz频段设置状态（调音大师）";
CM_ SG_ 800 AMPTMFLTopPositionEQ500HzSetStat "前左天空方位500Hz频段设置状态（调音大师）";
CM_ SG_ 800 AMPTMFRPositionEQ100HzSetStatus "前右方位100Hz频段设置状态（调音大师）";
CM_ SG_ 800 AMPTMFRPositionEQ15000HzSetStatu "前右方位15000Hz频段设置状态（调音大师）";
CM_ SG_ 800 AMPTMFRPositionEQ800HzSetStatus "前右方位800Hz频段设置状态（调音大师）";
CM_ SG_ 800 AMPTMFRTopPositionEQ500HzSetStat "前右天空方位500Hz频段设置状态（调音大师）";
CM_ SG_ 800 AMPTMReverbSetStatus "混响调节设置状态（调音大师）";
CM_ SG_ 800 AMPTMRLPositionEQ10000HzSetStatu "后左方位10000Hz频段设置状态（调音大师）";
CM_ SG_ 800 AMPTMRLPositionEQ100HzSetStatusS "后左方位100Hz频段设置状态（调音大师）";
CM_ SG_ 800 AMPTMRLSurroundPositionEQ15000Hz "后左环绕方位15000Hz频段设置状态（调音大师）";
CM_ SG_ 800 AMPTMRLSurroundPositionEQ800HzSe "后左环绕方位800Hz频段设置状态（调音大师）";
CM_ SG_ 800 AMPTMRLTopPositionEQ500HzSetStat "后左天空方位500Hz频段设置状态（调音大师）";
CM_ SG_ 800 AMPTMRRPositionEQ10000HzSetStatu "后右方位10000Hz频段设置状态（调音大师）";
CM_ SG_ 800 AMPTMRRPositionEQ100HzSetStatus "后右方位100Hz频段设置状态（调音大师）";
CM_ SG_ 800 AMPTMRRSurroundPositionEQ15000Hz "后右环绕方位15000Hz频段设置状态（调音大师）";
CM_ SG_ 800 AMPTMRRSurroundPositionEQ800HzSe "后右环绕方位800Hz频段设置状态（调音大师）";
CM_ SG_ 800 AMPTMRRTopPositionEQ500HzSetStat "后右天空方位500Hz频段设置状态（调音大师）";
CM_ SG_ 800 AMPTMSubPositionEQ30HzSetStatusS "重低音方位30Hz频段设置状态（调音大师）";
CM_ SG_ 800 AMPVOLSpeedLevChangeSETStatus "音量随速调节功能设置状态（新）";
CM_ BO_ 802 " ";
CM_ SG_ 802 ECAStarLvl "空簧目标高度";
CM_ SG_ 802 ECASActLvlFL "FL高度信号";
CM_ SG_ 802 ECASActLvlFR "FR高度信号";
CM_ SG_ 802 ECASActLvlRL "RL高度信号";
CM_ SG_ 802 ECASActLvlRR "RR高度信号";
CM_ SG_ 802 ECASAdjBySpd "随速调节激活状态";
CM_ SG_ 802 ECASaftaxladjsts "ECAS后轴升降状态";
CM_ SG_ 802 ECASerromode "ECAS故障模式";
CM_ SG_ 802 ECASfrtaxladjsts "ECAS前轴升降状态";
CM_ SG_ 802 EcasModeCHASts "ECAS模式切换状态";
CM_ SG_ 802 EcasModeFB "空簧模式当前模式反馈";
CM_ SG_ 802 ECASmodevld "ECAS模式有效";
CM_ SG_ 802 SusfaultlLamp "悬架故障点灯提示";
CM_ SG_ 802 Susfaultred "悬架文字提示";
CM_ BO_ 821 " ";
CM_ SG_ 821 BCM_DriverWindowStatus "主驾车窗状态";
CM_ SG_ 821 BCM_PartWinPosVIT "隔断玻璃实时位置（百分比）";
CM_ SG_ 821 BCM_PartWinSts "隔断玻璃状态";
CM_ SG_ 821 BCM_PassengerWindowPosi "副驾车窗位置";
CM_ SG_ 821 BCM_PassengerWindowStatus "副驾车窗状态";
CM_ SG_ 821 VcuIpuErrLamp "驱动电机故障指示灯";
CM_ SG_ 821 VcuEgyMagtModResp "能源模式设置反馈";
CM_ SG_ 821 VcuForceEVModResp "强制纯电模式反馈";
CM_ SG_ 821 VcuForcePwrPresModResp "强制保电模式反馈";
CM_ SG_ 821 BCM_RightRearWindowPosi "右后车窗位置";
CM_ SG_ 821 BCM_RightRearWindowStatus "右后车窗状态";
CM_ SG_ 821 VCU_CRCCheck_335 "335帧报文校验";
CM_ SG_ 821 VCU_RollingCounter_335 "335帧报文计数";
CM_ SG_ 821 VcuAcChrgNegativePoleTemp "交流充电负极温度";
CM_ SG_ 821 VcuAccrPedlPosnGb "加速踏板行程";
CM_ SG_ 821 VcuBattIGb "总电流（国标）";
CM_ SG_ 821 VcuGearPosnStsGb "挡位状态";
CM_ SG_ 821 VcuHvilStsGb "高压互锁状态报警（国标）";
CM_ SG_ 821 VcuVehChrgStsGb "充电状态";
CM_ SG_ 821 VcuVehRunngModGb "运行模式";
CM_ SG_ 821 VcuVehStsGb "车辆状态";
CM_ SG_ 821 VcuBrkPedlSts "VCU制动踏板状态";
CM_ SG_ 821 VcuPwrCnse "整车瞬时功率";
CM_ SG_ 821 VcuSocDisp "仪表显示SOC";
CM_ SG_ 821 BCM_DriverWindowPosi "主驾车窗位置";
CM_ SG_ 821 BCM_LeftRearWindowPosi "左后车窗位置";
CM_ SG_ 821 BCM_LeftRearWindowStatus "左后车窗状态";
CM_ SG_ 821 BcmSunroofPosi "天窗位置";
CM_ SG_ 821 BcmSunroofStatus "天窗状态";
CM_ SG_ 821 MFS_Right_switch_Right1_signal "MFS方向盘右按键1";
CM_ SG_ 821 VcuAcChrgPositivePoleTemp "交流充电正极温度";
CM_ SG_ 821 VcuBattChrgErrLamp "蓄电池充电故障指示灯";
CM_ SG_ 821 VcuBattlowU "铅蓄电池电压";
CM_ SG_ 821 VcuBattUUnderWarn "铅蓄电池电压报警";
CM_ SG_ 821 VcuChrgAutoUnlckSetStsFb "充电锁自动解锁功能设置状态反馈";
CM_ SG_ 821 VcuChrgLckInfo "电子锁文字提示";
CM_ SG_ 821 VcuDcChrgNegativePoleTemp "直流充电负极温度";
CM_ SG_ 821 VcuDcChrgPositivePoleTemp "直流充电正极温度";
CM_ SG_ 821 VCUGearShiftPositon "换挡器位置";
CM_ SG_ 821 VcuHvBattCutOffLamp "高压电池切断指示灯";
CM_ SG_ 821 VcuHVErrInfo "高压故障提示信息";
CM_ SG_ 821 VcuHvilSts "高压互锁状态";
CM_ SG_ 821 VcuResiMilg "整车续驶里程";
CM_ SG_ 821 VcuShiftPErrInfo "P挡故障提示信息";
CM_ SG_ 821 VCUShiftPostionValid "换挡器位置有效";
CM_ SG_ 821 VcuVehErrInfo "车辆严重故障提示信息";
CM_ SG_ 821 VIUFL_DeviceVerifyResult "设备认证结果";
CM_ SG_ 821 VcuOffRoadCrpSts "越野蠕行状态";
CM_ SG_ 821 BCMALLDoorLockSwt "整车门锁状态";
CM_ BO_ 822 " ";
CM_ SG_ 822 CcsmFrntEDLSetSwt "CCSM前差速锁开关请求 ";
CM_ SG_ 822 CcsmReEDLSetSwt "CCSM后差速锁开关请求 ";
CM_ SG_ 822 CcsmEDLBtnStuckFlg "差速锁按键粘连故障标志";
CM_ BO_ 854 " ";
CM_ SG_ 854 HU_FLHighSpeakerDelaySET "前左高音扬声器延时设置";
CM_ SG_ 854 HU_FLHighSpeakerVolSET "前左高音扬声器增益设置";
CM_ SG_ 854 HU_FLMidSpeakerDelaySET "前左中音扬声器延时设置";
CM_ SG_ 854 HU_FLMidSpeakerVolSET "前左中音扬声器增益设置";
CM_ SG_ 854 HU_FRHighSpeakerDelaySET "前右高音扬声器延时设置";
CM_ SG_ 854 HU_FRHighSpeakerVolSET "前右高音扬声器增益设置";
CM_ SG_ 854 HU_FRMidSpeakerDelaySET "前右中音扬声器延时设置";
CM_ SG_ 854 HU_FRMidSpeakerVolSET "前右中音扬声器增益设置";
CM_ SG_ 854 HUFLPositionDelaySET "前左方位延时设置";
CM_ SG_ 854 HUFLPositionVolSET "前左方位增益设置";
CM_ SG_ 854 HUFRPositionDelaySET "前右方位延时设置";
CM_ SG_ 854 HUFRPositionVolSET "前右方位增益设置";
CM_ SG_ 854 HU_AlarmVolSET "报警音音量设置";
CM_ SG_ 854 HU_AvasVolSET "车外行人警示音音量设置";
CM_ SG_ 854 HU_CenterSpeakerDelaySET "中置扬声器延时设置";
CM_ SG_ 854 HU_CenterSpeakerVolSET "中置扬声器增益设置";
CM_ SG_ 854 HU_CustomEffectSET "自定义音效设置";
CM_ SG_ 854 HU_CustomEQ125SET "自定义125Hz频段设置";
CM_ SG_ 854 HU_CustomEQ16KSET "自定义16000Hz频段设置";
CM_ SG_ 854 HU_CustomEQ1KSET "自定义1000Hz频段设置";
CM_ SG_ 854 HU_CustomEQ250SET "自定义250Hz频段设置";
CM_ SG_ 854 HU_CustomEQ2KSET "自定义2000Hz频段设置";
CM_ SG_ 854 HU_CustomEQ4KSET "自定义4000Hz频段设置";
CM_ SG_ 854 HU_CustomEQ500SET "自定义500Hz频段设置";
CM_ SG_ 854 HU_CustomEQ62SET "自定义62Hz频段设置";
CM_ SG_ 854 HU_CustomEQ8KSET "自定义8000Hz频段设置";
CM_ SG_ 854 HU_FLLowSpeakerDelaySET "前左低音扬声器延时设置";
CM_ SG_ 854 HU_FLLowSpeakerVolSET "前左低音扬声器增益设置";
CM_ SG_ 854 HU_FLMidHighSpeakerDelaySET "前左中高音扬声器延时设置";
CM_ SG_ 854 HU_FLMidHighSpeakerVolSET "前左中高音扬声器增益设置";
CM_ SG_ 854 HU_FLTopSpeakerDelaySET "前左顶棚扬声器延时设置";
CM_ SG_ 854 HU_FLTopSpeakerVolSET "前左顶棚扬声器增益设置";
CM_ SG_ 854 HU_FRBalanceSET "声场前后平衡设置";
CM_ SG_ 854 HU_FRLowSpeakerDelaySET "前右低音扬声器延时设置";
CM_ SG_ 854 HU_FRLowSpeakerVolSET "前右低音扬声器增益设置";
CM_ SG_ 854 HU_FRMidHighSpeakerDelaySET "前右中高音扬声器延时设置";
CM_ SG_ 854 HU_FRMidHighSpeakerVolSET "前右中高音扬声器增益设置";
CM_ SG_ 854 HU_FRTopSpeakerDelaySET "前右顶棚扬声器延时设置";
CM_ SG_ 854 HU_FRTopSpeakerVolSET "前右顶棚扬声器增益设置";
CM_ SG_ 854 HU_KTVMUTESET "KTV人声静音设置";
CM_ SG_ 854 HU_KTVVolSET "KTV人声音量设置";
CM_ SG_ 854 HU_LRBalanceSET "声场左右平衡设置";
CM_ SG_ 854 HU_MediaMUTESET "多媒体静音设置";
CM_ SG_ 854 HU_MediaVolSET "多媒体音量设置";
CM_ SG_ 854 HU_MUTESET "全部静音设置";
CM_ SG_ 854 HU_NaviMUTESET "导航静音设置";
CM_ SG_ 854 HU_NAVIVolSET "导航播报音量设置";
CM_ SG_ 854 HU_OutMUTESET "车外声音静音设置";
CM_ SG_ 854 HU_OUTVolSET "车外声音音量设置";
CM_ SG_ 854 HU_PerfessiionalEQ100SET "专业自定义100Hz频段设置";
CM_ SG_ 854 HU_PerfessiionalEQ500SET "专业自定义500Hz频段设置";
CM_ SG_ 854 HU_PerfessiionalEQ6KSET "专业自定义6000Hz频段设置";
CM_ SG_ 854 HU_RLLowHighSpeakerDelaySET "后左低高音扬声器延时设置";
CM_ SG_ 854 HU_RLLowHighSpeakerVolSET "后左低高音扬声器增益设置";
CM_ SG_ 854 HU_RLSurroundSpeakerDelaySET "后左环绕扬声器延时设置";
CM_ SG_ 854 HU_RLSurroundSpeakerVolSET "后左环绕扬声器增益设置";
CM_ SG_ 854 HU_RLTopSpeakerDelaySET "后左顶棚扬声器延时设置";
CM_ SG_ 854 HU_RLTopSpeakerVolSET "后左顶棚扬声器增益设置";
CM_ SG_ 854 HU_RNCEnableSET "主动路噪降噪功能设置";
CM_ SG_ 854 HU_RRLowHighSpeakerDelaySET "后右低高音扬声器延时设置";
CM_ SG_ 854 HU_RRLowHighSpeakerVolSET "后右低高音扬声器增益设置";
CM_ SG_ 854 HU_RRSurroundSpeakerDelaySET "后右环绕扬声器延时设置";
CM_ SG_ 854 HU_RRSurroundSpeakerVolSET "后右环绕扬声器增益设置";
CM_ SG_ 854 HU_RRTopSpeakerDelaySET "后右顶棚扬声器延时设置";
CM_ SG_ 854 HU_RRTopSpeakerVolSET "后右顶棚扬声器增益设置";
CM_ SG_ 854 HU_SoundEffectSET "音效设置";
CM_ SG_ 854 HU_SoundFieldSET "声场设置";
CM_ SG_ 854 HU_SubSpeakerDelaySET "重低音扬声器延时设置";
CM_ SG_ 854 HU_SubSpeakerVolSET "重低音扬声器增益设置";
CM_ SG_ 854 HU_SystemMUTESET "系统提示音静音设置";
CM_ SG_ 854 HU_SystemVolSET "系统提示音量设置";
CM_ SG_ 854 HU_TelBcallMUTESET "电话/Bcall静音设置";
CM_ SG_ 854 HU_TELBCALLVolSET "蓝牙电话音量/becall音量设置";
CM_ SG_ 854 HU_TTSVRMUTESET "TTS/语音静音设置";
CM_ SG_ 854 HU_TTSVRVolSET "TTS/语音音量设置";
CM_ SG_ 854 HU_TurnLightInOrOutSET "转向灯音车内外设置";
CM_ SG_ 854 HU_TurnLightVolSET "转向灯音音量设置";
CM_ SG_ 854 HU_VOLSpeedLevEnableSET "音量随速调节功能设置";
CM_ SG_ 854 HUBeosonicModeSet "Beosonic模式设置";
CM_ SG_ 854 HUBeosonicXSet "BeosonicX轴参数设置";
CM_ SG_ 854 HUBeosonicYSet "BeosonicY轴参数设置";
CM_ SG_ 854 HUCenterPositionDelaySET "中置方位延时设置";
CM_ SG_ 854 HUCenterPositionVolSET "中置方位增益设置";
CM_ SG_ 854 HUCustomEQ2500SET "自定义2500Hz频段设置状态";
CM_ SG_ 854 HUCustomEQ315SET "自定义315Hz频段设置状态";
CM_ SG_ 854 HUCustomEQ50SET "自定义50Hz频段设置状态";
CM_ SG_ 854 HUCustomEQ6000SET "自定义6000Hz频段设置状态";
CM_ SG_ 854 HUCustomEQ800SET "自定义800Hz频段设置状态";
CM_ SG_ 854 HUFLTopPositionDelaySET "前左天空方位延时设置";
CM_ SG_ 854 HUFLTopPositionVolSET "前左天空方位增益设置";
CM_ SG_ 854 HUFRTopPositionDelaySET "前右天空方位延时设置";
CM_ SG_ 854 HUSoundSourceType "音源类型";
CM_ SG_ 854 HUTMCenterPositionEQ15000HzSet "中置方位15000Hz频段设置（调音大师）";
CM_ SG_ 854 HUTMCenterPositionEQ800HzSet "中置方位800Hz频段设置（调音大师）";
CM_ SG_ 854 HUTMFLPositionEQ100HzSet "前左方位100Hz频段设置（调音大师）";
CM_ SG_ 854 HUTMFLPositionEQ15000HzSet "前左方位15000Hz频段设置（调音大师）";
CM_ SG_ 854 HUTMFLPositionEQ800HzSet "前左方位800Hz频段设置（调音大师）";
CM_ SG_ 854 HUTMFLTopPositionEQ500HzSet "前左天空方位500Hz频段设置（调音大师）";
CM_ SG_ 854 HUTMFRPositionEQ100HzSet "前右方位100Hz频段设置（调音大师）";
CM_ SG_ 854 HUTMFRPositionEQ15000HzSet "前右方位15000Hz频段设置（调音大师）";
CM_ SG_ 854 HUTMFRPositionEQ800HzSet "前右方位800Hz频段设置（调音大师）";
CM_ SG_ 854 HUTMFRTopPositionEQ500HzSet "前右天空方位500Hz频段设置（调音大师）";
CM_ SG_ 854 HUTMReverbSet "混响调节设置（调音大师）";
CM_ SG_ 854 HUTMRLPositionEQ10000HzSet "后左方位10000Hz频段设置（调音大师）";
CM_ SG_ 854 HUTMRLPositionEQ100HzSet "后左方位100Hz频段设置（调音大师）";
CM_ SG_ 854 HUTMRLSurroundPositionEQ15000HzS "后左环绕方位15000Hz频段设置（调音大师）";
CM_ SG_ 854 HUTMRLSurroundPositionEQ800HzSet "后左环绕方位800Hz频段设置（调音大师）";
CM_ SG_ 854 HUTMRLTopPositionEQ500HzSet "后左天空方位500Hz频段设置（调音大师）";
CM_ SG_ 854 HUTMRRPositionEQ10000HzSet "后右方位10000Hz频段设置（调音大师）";
CM_ SG_ 854 HUTMRRPositionEQ100HzSet "后右方位100Hz频段设置（调音大师）";
CM_ SG_ 854 HUTMRRSurroundPositionEQ15000HzS "后右环绕方位15000Hz频段设置（调音大师）";
CM_ SG_ 854 HUTMRRSurroundPositionEQ800HzSet "后右环绕方位800Hz频段设置（调音大师）";
CM_ SG_ 854 HUTMRRTopPositionEQ500HzSet "后右天空方位500Hz频段设置（调音大师）";
CM_ SG_ 854 HUTMSubPositionEQ30HzSet "重低音方位30Hz频段设置（调音大师）";
CM_ SG_ 854 HUTMTransEnd "调音大师参数发送完成标识";
CM_ SG_ 854 HUVOLSpeedLevChangeSET "音量随速调节功能设置（新）";
CM_ BO_ 868 " ";
CM_ SG_ 868 CdcEpbSetSwt_1 "CDC电子手刹开关设置1";
VAL_ 80 SrsCrashOutpSts 0 "NoCrash" 1 "crash" ;
VAL_ 80 SrsDrvrBucSwtSts 0 "Buckled" 1 "Unbuckle" 2 "Not defined" 3 "Not Used" ;
VAL_ 80 SrsLe2ndBucSwtSts 0 "Buckled" 1 "Unbuckle" 2 "Not defined" 3 "Not Used" ;
VAL_ 80 SrsLe3rdBucSwtSts 0 "Buckled" 1 "Unbuckle" 2 "Not defined" 3 "Not Used" ;
VAL_ 80 SrsMid2ndBucSwtSts 0 "Buckled" 1 "Unbuckle" 2 "Not defined" 3 "Not Used" ;
VAL_ 80 SrsMid3rdBucSwtSts 0 "Buckled" 1 "Unbuckle" 2 "Not defined" 3 "Not Used" ;
VAL_ 80 SrsPadIndcn 0 "PABonandLampoff" 1 "PAB off and Lamp on" ;
VAL_ 80 SrsPassBucSwtSts 0 "Buckled" 1 "Unbuckle" 2 "Not defined" 3 "Not Used" ;
VAL_ 80 SrsRi2ndBucSwtSts 0 "Buckled" 1 "Unbuckle" 2 "Not defined" 3 "Not Used" ;
VAL_ 80 SrsRi3rdBucSwtSts 0 "Buckled" 1 "Unbuckle" 2 "Not defined" 3 "Not Used" ;
VAL_ 80 SrsWarnLampSts 0 "Lampoff" 1 "Lampon" 2 "LampFlashing" 3 "NotUsed" ;
VAL_ 81 SRS_CrashOut_Cedr 0 "NoCrash" 1 "C-EDR Trigger" ;
VAL_ 81 SRS_CrashOut_Front 0 "NoCrash" 1 "Front Crash" ;
VAL_ 81 SRS_CrashOut_Left 0 "NoCrash" 1 "Left Side Crash" ;
VAL_ 81 SRS_CrashOut_Micro 0 "NoCrash" 1 "Micro Crash" ;
VAL_ 81 SRS_CrashOut_Rear 0 "NoCrash" 1 "Rear Crash" ;
VAL_ 81 SRS_CrashOut_Right 0 "NoCrash" 1 "Right Side Carsh" ;
VAL_ 81 SRS_CrashOut_Rollover 0 "NoRollover" 1 "Rollover" ;
VAL_ 338 AD_Reqmode 0 "Norequest" 1 " Parking running" 2 "Auto Driving" 3 "Reserved" ;
VAL_ 338 AD_ACCMode 0 "OFFmode" 1 "Passive mode" 2 "StandBy mode" 3 "Active Control mode" 4 "Brake Only mode" 5 "Override" 6 "Stand Wait mode" 7 "Failure mode" ;
VAL_ 338 AD_AEBActive 0 "notActive" 1 "Active." ;
VAL_ 338 AD_DynamicWarningLevel 0 "norequest" 1 "level 1 request" 2 "level 2 request" 3 "level 3 request" ;
VAL_ 338 AD_ESSActive 0 "notActive" 1 "DES_Left_Active" 2 "DES_Right_Active" 3 "CES_Left_Active" 4 "CES_Right_Active" 5 "AES_Left_Active" 6 "AES_Right_Active" ;
VAL_ 338 AD_ESSStatus 0 "off" 1 "passive" 2 "failure" 3 " standby" 4 "active" 5 "reserved" ;
VAL_ 338 AD_ESSWarning 0 "notActive" 1 "DES_Left_Warning" 2 "DES_Right_Warning" 3 "CES_Left_Warning" 4 "CES_Right_Warning" 5 "AES_Left_Warning" 6 "AES_Right_Warning" ;
VAL_ 338 AD_FCTBActive 0 "notActive" 1 " left Active" 2 " right Active" ;
VAL_ 338 AD_LatAngReqActive 0 "notActive" 1 "Active" ;
VAL_ 338 AD_LDWinhaitwaring 0 "NoWarning" 1 "LDW suspend warning" ;
VAL_ 338 AD_LKAinhaitWarning 0 "nowarning" 1 "left warning" 2 "right warning" ;
VAL_ 338 AD_LKAStatus 0 "off" 1 "Passive" 2 "Standby" 3 "Active" 4 "Failure" 5 "reserved" ;
VAL_ 338 AD_REBStatus 0 "off" 1 "passive" 2 "standby" 3 " active" 4 "failure" 5 "reserved" ;
VAL_ 338 AD_RunRedLightWaring 0 "NoWarning" 1 "Runing a red light warning" ;
VAL_ 338 AD_SafetyNotice 0 "无信息" 1 "道路天气环境较差" 2 "前方道路变化" 3 "超出坡度范围" 4 "前方交通事故" 5 "前方道路施工" 6 "前方经过环岛" 7 "前方经过服务区" 8 "前方经过隧道" 9 "前方经过匝道" 10 "超出电子围栏或无法定位" 11 "道路颠簸" 12 "前方存在行人" 13 "脱眼报警" 14 "未检测到头部" 15 "请手握方向盘，注意前方路况" 16 "道路天气环境较差，请手握方向盘" 17 "前方道路变化，请手握方向盘" 18 "超出坡度范围，请手握方向盘" 19 "前方交通事故，请手握方向盘" 20 "前方道路施工，请手握方向盘" 21 "前方经过环岛，请手握方向盘" 22 "前方经过服务区，请手握方向盘" 23 "前方经过隧道，请手握方向盘" 24 "前方经过匝道，请手握方向盘" 25 "超出电子围栏或无法定位，请手握方向盘" 26 "道路颠簸，请手握方向盘" 27 "前方存在行人，请手握方向盘" 28 "系统异常，请手握方向盘" 29 "油门超越，请手握方向盘" 30 "请保持ESP功能开启" 31 "请保持挡位为D挡或S挡" 32 "请求系好安全带，X秒系统退出" 33 "雨刮故障，请立即接管" 34 "灯光故障，请立即接管" 35 "动力系统异常，请立即接管" 36 "传感系统异常，请立即接管" 37 "转向系统异常，请立即接管" 38 "制动系统异常，请立即接管" 39 "交互系统异常，请立即接管" 40 "驻车系统异常，请立即接管" 41 "系统异常，请立即接管" 42 "胎压异常，请立即接管" 43 "胎温异常，请立即接管" 44 "数据记录异常，请立即接管" 45 "道路天气环境较差，请立即接管" 46 "超出坡度范围，请立即接管" 47 "前方道路施工，请立即接管" 48 "道路颠簸，请立即接管" 49 "道路湿滑，请立即接管" 50 "危险目标，请立即接管" 51 "前方存在行人，请立即接管" 52 "请求系好安全带，并立即接管" 53 "换道失败，请立即接管" 54 "即将在本车道停车，请立即接管" 55 "即将靠边停车，请立即接管" 56 "正在停车，请立即接管" 57 "停车已完成，请立即接管" 58 "前方存在骑行者" 59 "解开安全带，系统退出" 60 "车门打开，系统退出" 61 "ESP功能关闭，系统退出" 62 "挡位切换，系统退出" 63 "巡航驻车超时，系统退出" 64 "前方存在骑行者，请手握方向盘" 65 "请立即接管" 66 "转向灯故障，请立即接管" 67 "制动灯异常，请立即接管" 68 "远近光灯故障，请立即接管" 69 "请打开远近光灯，并立即接管" 70 "轨迹规划异常，请立即接管" 71 "电量过低，请立即接管" 72 "制动盘过热，请立即接管" 73 "前方存在骑行者，请立即接管" 74 "车辆存在失稳，请立即接管" 75 "油门超越，请手握方向盘，注意前方路况" 76 "前后舱盖或车门未关闭，请立即接管" 77 "车辆碰撞危险，请立即接管" 79 "前方汇流" 80 "前方分流" 81 "通讯故障，请立即接管" 82 "前方经过路口" 83 "前方经过路口，请手握方向盘" 84 "超出曲率范围，请手握方向盘" 85 "超出曲率范围" 86 "超出曲率范围，请立即接管" 87 "车道宽度不合适" 88 "车道宽度不合适，请手握方向盘" 89 "前方道路危险障碍物" 90 "前方道路危险障碍物，请手握方向盘" 91 "车辆压线行驶" 92 "前方经过收费站" 93 "系统退出" 95 "前方红绿灯" 96 "前方人行横道" 97 "前方红绿灯，请手握方向盘" 98 "前方人行横道，请手握方向盘" 99 "请降低车速" 100 "车速过高，请立即接管" 101 "未检测到驾驶员，请立即接管" 102 "拥堵解除，请手握方向盘，注意前方路况" 103 "前方存在特殊车辆，请立即接管" 104 "前方车辆倒车，请立即接管" 105 "前方有障碍物，请立即接管" 106 "前方截止路段，请立即接管" 107 "前方路口无法通行，请立即接管" 108 "前方无法下匝道，请立即接管" 109 "UDLC道路交通环境限制-中断换道无法回退接管" 110 "ALC无法自动换道，需用户接管" 111 "OA无法绕障，需用户接管" 112 "IDA路口无法通行，需用户接管" 113 "匝道辅助-无法汇入主路，需用户接管" 114 "匝道辅助-无法汇入匝道，需用户接管" 115 "NID-系统退出，需用户接管" 116 "禁止脱手-前方经过路口，禁止脱手" 117 "禁止脱手-前方下匝道" 118 "立即接管提示-后备箱未关" 119 "立即接管提示-车门未关闭" 120 "立即接管提示-充电盖未关闭" 121 "立即接管提示-按键故障" 122 "立即接管提示-档位失效" 123 "立即接管提示-车道线不清晰" 124 "立即接管提示-纠偏失败需接管" 125 "立即接管提示-无法保持车道内行驶" 126 "注意力预告-前方骑行者" 127 "注意力预告-上下匝道" 128 "注意力预告-油门超越" 129 "注意力预告-系统异常" 130 "禁止脱手-LKA脱手" 131 "接管-ACC/巡航/领航退出" 132 "接管-车道过窄" 133 "接管-安全停车" 134 "接管-车流与本车道横向距离过近" ;
VAL_ 338 ADC_SenceMode 0 "unkown" 1 "地库模式" 2 "非地库模式" 3 "Reserved" ;
VAL_ 338 AEB_AWBActive 0 "notActive" 1 "Active" ;
VAL_ 338 AD_FlowReqValid 0 "无效" 1 "有效" ;
VAL_ 338 AD_TmstempReqValid 0 "无效" 1 "有效" ;
VAL_ 338 ADR_TriggerEventReq 0 "NoTrigger" 1 "发生严重事故BA006" 2 "有碰撞风险事故BA007" 3 "触发AEB事件BA008" 4 "发生一般事故BA009" 5 "AEB SOP2功能影子模式BA521（C2M+）" 6 "AEB制动使能事件BA562（C2M+）" 7 "AEB影子模式触发BA067（C2M+）" 8 "ESS影子模式触发BA515（C2M+）" 9 "ESS功能使能事件BA522（C2M+）" ;
VAL_ 346 EPB_AchievedClampForce_Secondary 30 "Reserved" 31 "Error" ;
VAL_ 346 EPB_FunctionLamp_Secondary 0 "LampOff" 1 "Lamp ON" 2 "Lamp Flashing" 3 "Invalid" ;
VAL_ 346 EPB_Status_Secondray 0 "released" 1 " ParkedApplied" 2 "releasing" 3 "applying" 4 "unknown" 5 "HoldApplied" 6 " CompletelyReleased" 7 "HapPrepared" ;
VAL_ 346 EpbFailrLamp_Secondary 0 "LampOff" 1 "Lamp ON" 2 "Lamp Flashing" 3 "Invalid" ;
VAL_ 346 RPBCoorSec_CommunicationAvailabl 0 "False" 1 "True" ;
VAL_ 346 RPBCoorSec_DiagModeActive 0 "False" 1 "True" ;
VAL_ 346 RPBCoorSec_HostAvailabilityFull 0 "False" 1 "True" ;
VAL_ 346 RPBCoorSec_HostAvailabilityRelOn 0 "False" 1 "True" ;
VAL_ 346 RPBCoorSec_reserved1 0 "False" 1 "True" ;
VAL_ 346 RPBCoorSec_reserved2 0 "False" 1 "True" ;
VAL_ 346 RPBCoorSec_reserved3 0 "False" 1 "True" ;
VAL_ 349 ESP_YawRateValid 0 "Initializing" 1 " Valid" 2 " Invalid" 3 " Reserved" ;
VAL_ 349 ESP_Calibrated 0 "Calibrated" 1 " Not Calibrated" ;
VAL_ 349 ESP_LatAccelValid 0 "Initializing" 1 "Valid" 2 "Invalid" 3 "Reserved" ;
VAL_ 349 ESP_LongAccelValid 0 "Initializing" 1 "Valid" 2 "Invalid" 3 "Reserved" ;
VAL_ 353 ESP_ABAactive 0 "notactive" 1 "active" ;
VAL_ 353 ESP_ABAavailable 0 "notavailable" 1 "available" ;
VAL_ 353 ESP_AEBAvailable 0 "notavailable" 1 "available" ;
VAL_ 353 ESP_AEBdecActive 0 "notactive" 1 "active" ;
VAL_ 353 ESP_PrefillActive 0 "notactive" 1 "active" ;
VAL_ 353 ESP_PrefillAvailable 0 "notavailable" 1 "available" ;
VAL_ 353 IBCU_BrakeDiscOverHeat 0 "nothigh" 1 "temptoohigh" ;
VAL_ 353 IBCU_BrakeForce 0 "nobrakeforce" 1 "havebrakeforce" ;
VAL_ 353 IBCU_QDCSts 0 "noerror" 1 "error" 2 "reserved" 3 "reserved" ;
VAL_ 355 DMF_BrkForceTarDecActv 0 "notactive" 1 "active" ;
VAL_ 355 DMF_CrbsFailrSts 0 "Normal" 1 " Failure" ;
VAL_ 355 DMF_VehTarForceReqMod 0 "NoRequest" 1 "Normal Request" 2 "Emergency Request" 3 "Reserved" ;
VAL_ 355 DMF_LeFrntTarBrkForceMod 0 "NoRequest" 1 "Feedthrough" 2 "ModifiedByABS" 3 "Lock Request" ;
VAL_ 355 DMF_RiFrntTarBrkForceMod 0 "NoRequest" 1 "Feedthrough" 2 "ModifiedByABS" 3 "Lock Request" ;
VAL_ 355 DMF_LeReTarBrkForceMod 0 "NoRequest" 1 "Feedthrough" 2 "ModifiedByABS" 3 "Lock Request" ;
VAL_ 355 DMF_RiReTarBrkForceMod 0 "NoRequest" 1 "Feedthrough" 2 "ModifiedByABS" 3 "Lock Request" ;
VAL_ 355 DMF_EscFctSts 0 "Inactive" 1 "ESC Control" 2 "EUC Control" 3 "TSM Control" 4 "RMF Control" 5 "Reserved" 6 "Reserved" 7 "Reserved" ;
VAL_ 355 DMF_PrefillActvReq 0 "NoActvRequest" 1 "ActvReques" ;
VAL_ 355 DMF_ReWhlDecTarTqActv 0 "Notactive" 1 "active" ;
VAL_ 355 DMF_ReWhlIncTarTqActv 0 "Notactive" 1 "active" ;
VAL_ 355 DMF_FrntWhlDecTarTqActv 0 "Notactive" 1 "active" ;
VAL_ 355 DMF_FrntWhlIncTarTqActv 0 "Notactive" 1 "active" ;
VAL_ 355 DMF_LeFrntWhlIncTarTqActv 0 "Notactive" 1 "active" ;
VAL_ 355 DMF_RiFrntWhlIncTarTqActv 0 "Notactive" 1 "active" ;
VAL_ 355 DMF_LeReWhlIncTarTqActv 0 "Notactive" 1 "active" ;
VAL_ 355 DMF_RiReWhlIncTarTqActv 0 "Notactive" 1 "active" ;
VAL_ 355 DMF_LeFrntWhlDecTarTqActv 0 "Notactive" 1 "active" ;
VAL_ 355 DMF_RiFrntWhlDecTarTqActv 0 "Notactive" 1 "active" ;
VAL_ 355 DMF_LeReWhlDecTarTqActv 0 "Notactive" 1 "active" ;
VAL_ 355 DMF_RiReWhlDecTarTqActv 0 "Notactive" 1 "active" ;
VAL_ 355 DMF_ADReqmode 0 "Norequest" 1 " Parking running" 2 "Auto Driving" 3 "Driverless Runing" ;
VAL_ 355 DMF_ADDriverlessReq 0 "notremote" 1 "remote" ;
VAL_ 355 DMF_ADAbaRankReq 0 "Norequest" 1 "level A" 2 "level B" 3 "level C" ;
VAL_ 355 DMF_ADAbaRankReqVld 0 "Valid" 1 "Invalid " ;
VAL_ 355 DMF_ADSystemSts 0 "noerror" 1 " Primary System error" 2 " Secondary System error" 3 " Both MCU error" ;
VAL_ 355 DMF_ADFctOpenSts 0 "off" 1 " on -L2" 2 " on -L3" 3 " Invalid" ;
VAL_ 355 DmfEscReqRwsActv 0 "NotAcitve" 1 "Active" ;
VAL_ 355 DmfDstwActvSts 0 "NotAcitve" 1 "Active" ;
VAL_ 359 EmsCoolanTErr 0 "Noerror" 1 "Error" ;
VAL_ 378 IbBrkPedlStsGb 0 "制动未踩下" 101 "制动踩下" ;
VAL_ 378 IbBrkPedlStsGbVld 0 "NotInitialized" 1 "Normal" 2 "Invalid" ;
VAL_ 378 IbBrkPedlTrvlDrvrVld 0 "NotInitialized" 1 "Normal" 2 "Invalid" ;
VAL_ 378 IBCU_PlungerBrakePressureValid 0 "Invalid" 1 "Valid" ;
VAL_ 384 EpsSasSteerAgVld 0 "Valid" 1 "Invalid" ;
VAL_ 384 EpsSasCalSts 0 "Calibrated" 1 "Not Calibrated" ;
VAL_ 384 EpsSteerAgSensFilr 0 "Valid" 1 "Invalid" ;
VAL_ 417 VcuChrglockPosn2 0 "disable" 1 "enable" ;
VAL_ 417 VcuChrglockPosn1 0 "disable" 1 "enable" ;
VAL_ 419 FrntMotSpdVld 0 "Valid" 1 "Invalid" ;
VAL_ 419 FrntMotTqVld 0 "Valid" 1 "Invalid" ;
VAL_ 420 ReMotSpdVld 0 "Valid" 1 "Invalid" ;
VAL_ 420 ReMotTqVld 0 "Valid" 1 "Invalid" ;
VAL_ 421 BcuChrgMod 0 "无充电模式" 1 "10A家用交流充电模式" 2 "10A缆上控制盒充电模式" 3 "16A交流充电桩/缆上控制盒充电模式" 4 "32A交流充电桩模式" 5 "63A交流充电桩模式" 6 "直流充电模式" 7 "交流/直流模式冲突" 8 "交流充电枪半连接状态" 9 "交流充电模式异常" 10 "直流充电模式异常" ;
VAL_ 433 PwrTrainSts 0 "Stop" 1 "Crank" 2 "Running" 3 "Invalid" ;
VAL_ 433 VcuRdySts 0 "noReady" 1 "Ready" ;
VAL_ 433 VcuGearPosn 0 "Invalid" 1 "P" 2 "R" 3 "N" 4 "D" 5 "reserved" ;
VAL_ 433 VcuVehGearPosnVld 0 "Valid" 1 "Invalid" ;
VAL_ 433 AcChrgHvActvReq 0 "NoRequest" 1 "HV Active Request" ;
VAL_ 433 DcAcHvActvReq 0 "NoRequest" 1 "HV Active Request" ;
VAL_ 433 DcChrgHvActvReq 0 "NoRequest" 1 "HV Active Request" ;
VAL_ 433 OTAHvActvReq 0 "NoRequest" 1 "OTAHV Active Request" 2 "OTAPower Down Request" ;
VAL_ 433 SrvAllwblReqSts 0 "NotAllowed" 1 "Allowed" ;
VAL_ 433 VcuHvSysErrNr 0 "无故障" 1 "紧急故障下高压" 2 "BCU故障下高压" 3 "BCU不允许上高压" 4 "IPU不允许上高压" 5 "OTA中不允许上高压" 6 "低电量断电下高压" 7 "超时未上高压" ;
VAL_ 433 VehHvActvReq 0 "NoRequest" 1 "HV Active Request" ;
VAL_ 433 BrkgRgnMaxWhlVldSts 0 "NotIntialized" 1 "Normal" 2 "Faulty" ;
VAL_ 433 LePresSw 0 "按键未按下" 1 "按键按下" 2 "假按键（Reserved）" 3 "Error" ;
VAL_ 433 ReMotSpdVld 0 "Valid" 1 "Invalid" ;
VAL_ 433 RiPresSw 0 "按键未按下" 1 "按键按下" 2 "假按键（Reserved）" 3 "Error" ;
VAL_ 433 VCUAccPedShield 0 "Unshield" 1 "Shield" ;
VAL_ 433 VcuAccrMod 0 "invalid" 1 "Normal" 2 "Fast" 3 "Slow" 4 "Super Slow" 5 " ATS" 6 " Offroad" 7 " Super Fast" 8 "Snow" 9 "Sand" 10 "Wade" 11 "AISportLvl1" 12 "AISportLvl2" 13 "AISportLvl3" 14 "AISportLvl4" ;
VAL_ 433 VcuAccrPedlPosnVld 0 "Valid" 1 "Invalid" ;
VAL_ 433 VCUAPAdriverInterruption 0 "NoInterruption" 1 "Interruption" 2 "Reserved" 3 "invalid" ;
VAL_ 433 VCUAPARequestEnable 0 "norequest" 1 "Control enabled" 2 "Control disable" 3 "invalid" ;
VAL_ 433 VcuCalcnAccrPedlPosnVld 0 "Valid" 1 "Invalid" ;
VAL_ 433 VcuComFltSts 0 "noerror" 1 "reversible error" 2 "irreversible error" 3 "not defined" ;
VAL_ 433 VcuCrpFctSts 0 "Invalid" 1 "ON" 2 "OFF" 3 "Reserved" ;
VAL_ 433 VcuDecToStopReq 0 "nodemand" 1 "demand" ;
VAL_ 433 VcuDrvrGearDmd 0 "未操作" 1 "P挡" 2 "R挡" 3 "N挡" 4 "D挡" ;
VAL_ 433 VcuEnyRecyclMod 0 "Notset" 1 "normal" 2 "strong" 104 "Weak" ;
VAL_ 433 VcuEpbReq 0 "norequest" 1 "apply" 2 "release" ;
VAL_ 433 VcuEpbReqVld 0 "Valid" 1 "Invalid" ;
VAL_ 433 VcuFrntMotSpdVld 0 "Valid" 1 "Invalid" ;
VAL_ 433 VcuFrntWhlActTqVld 0 "Valid" 1 "Invalid" ;
VAL_ 433 VcuFrntWhlReqTqVld 0 "Valid" 1 "Invalid" ;
VAL_ 433 VcuMbRgnWhlVldSts 0 "NotIntialized" 1 "Normal" 2 "Faulty" ;
VAL_ 433 VcuObdType 0 "NonOBD" 1 "CN6 OBD" ;
VAL_ 433 VcuOvrdModReq 0 "Notoverride" 1 "Override" ;
VAL_ 433 VcuPmuSleepReq 0 "norequest" 1 "request" ;
VAL_ 433 VcuPmuSwtCloseAllowFlg 0 "不允许" 1 "允许" ;
VAL_ 433 VcuPtCoastRegenReqTqVld 0 "Valid" 1 "Invalid" ;
VAL_ 433 VcuPtTqLimMaxVld 0 "Valid" 1 "Invalid" ;
VAL_ 433 VcuPtTqLimMinVld 0 "Valid" 1 "Invalid" ;
VAL_ 433 VcuPtTqRealVld 0 "Valid" 1 "Invalid " ;
VAL_ 433 VcuPtTqReqAvl 0 "notavailable" 1 "available" 2 "available degraded" ;
VAL_ 433 VcuReWhlActTqVld 0 "Valid" 1 "Invalid" ;
VAL_ 433 VcuReWhlReqTqVld 0 "Valid" 1 "Invalid" ;
VAL_ 433 VcuSimnEpbSwtSts 0 "norequest" 1 "apply" ;
VAL_ 433 VcuSimnEpbSwtStsVld 0 "Valid" 1 "Invalid" ;
VAL_ 433 VcuTarGearPosn 0 "Invalid" 1 "P档" 2 "R档" 3 "N档" 4 "D档" 5 "预留" ;
VAL_ 433 VcuTrlrModActvSts 0 "Invalid" 1 "Not active" 2 "active" 3 "Reserved" ;
VAL_ 433 VcuVechicleType 0 "CombustionEngine" 1 "Hybrid" 2 "EV" ;
VAL_ 433 VcuVehWhlReqTqVld 0 "Valid" 1 "Invalid " ;
VAL_ 450 EspAbsActv 0 "Notactive" 1 "active" ;
VAL_ 450 EspAbsFailr 0 "Noerror" 1 "Error" ;
VAL_ 450 EspActvSts 0 "Notactive" 1 "active" ;
VAL_ 450 EspFctOpenSts 0 "Off" 1 "ON" ;
VAL_ 450 EspTcsActvSts 0 "Notactive" 1 "active" ;
VAL_ 450 EspTcsFailr 0 "Noerror" 1 "Error" ;
VAL_ 450 EspVehSpdVld 0 "Valid" 1 "Invalid" ;
VAL_ 450 EspEbdFailr 0 "Noerror" 1 "Error" ;
VAL_ 450 EspHDCSts 0 "Off" 1 "standby" 2 " active" 3 " Error" ;
VAL_ 450 EspVdcActvSts 0 "Notactive" 1 "active" ;
VAL_ 450 EspVehStandstill 0 "Notstandstill" 1 "standstill" ;
VAL_ 450 IBCU_BrakeFluid_Warning 0 "Normal" 1 "low" 2 " Reserved" 3 " Invalid" ;
VAL_ 450 MCBActv 0 "Notactive" 1 "active" ;
VAL_ 450 MCBAvl 0 "Notavailable" 1 "available" ;
VAL_ 450 WhlSpdLeFrntDataVld 0 "Valid" 1 "Invalid" ;
VAL_ 450 WhlSpdLeFrntDir 0 "Forward" 1 "backward" 2 "Standstill" 3 "Invalid" ;
VAL_ 450 WhlSpdLeReDataVld 0 "Valid" 1 "Invalid" ;
VAL_ 450 WhlSpdLeReDir 0 "Forward" 1 "backward" 2 "Standstill" 3 "Invalid" ;
VAL_ 450 WhlSpdRiFrntDataVld 0 "Valid" 1 "Invalid" ;
VAL_ 450 WhlSpdRiFrntDir 0 "Forward" 1 "backward" 2 "Standstill" 3 "Invalid" ;
VAL_ 450 WhlSpdRiReDataVld 0 "Valid" 1 "Invalid" ;
VAL_ 450 WhlSpdRiReDir 0 "Forward" 1 "backward" 2 "Standstill" 3 "Invalid" ;
VAL_ 450 EspAutoHoldActvSts 0 "Notactive" 1 "active" ;
VAL_ 450 EspBrkSysFltLamp 0 "OFF" 1 "ON" ;
VAL_ 450 IBCU_iDCSAvlblSts 0 "Notavailable" 1 "available" ;
VAL_ 450 IBCU_iDCSLevFd 0 "Init" 1 "M-Mode_level 1" 2 "M-Mode_level 2" 3 "M-Mode_level 3" ;
VAL_ 450 IBCU_iDCS_State 0 "OFF" 1 "Standby" 2 "PreActive" 3 "acitve" 4 "Reserved" ;
VAL_ 452 EMB_Pri_SystemFlt 0 "Init" 1 "OFF" 2 "BBF_Limited" 3 "BBF_2_w_S" 4 "BBF_3_wo_S" 5 "BBF_3_ w_S" 6 "BBF_ON_wo_S" 7 "ABS_Reduce" 8 "ABS_ON" ;
VAL_ 452 EMB_Pri_BrkRodStrkVld 0 "Valid" 1 "Invalid" ;
VAL_ 452 EMBParkPriCtrlEnableRL 0 "Disable" 1 "Enable" ;
VAL_ 452 EMBParkPriCtrlEnableRR 0 "Disable" 1 "Enable" ;
VAL_ 452 EMBParkPriAvailabilityRL 0 "init" 1 "not available" 2 "available" ;
VAL_ 452 EMBParkPriAvailabilityRR 0 "init" 1 "not available" 2 "available" ;
VAL_ 452 EMBParkPriCtrlSourceRL 0 "ApbReqSource_NoRequest" 1 "ApbReqSource_RollerTestBench" 2 "ApbReqSource_EmergencyApply" 3 "ApbReqSource_Button_Apply" 4 "ApbReqSource_Button_Release" 5 "ApbReqSource_Button_DclBrkMech" 6 "ApbReqSource_DriveOff_Release" 7 "ApbReqSource_AutoApply" 8 "ApbReqSource_ExtFunction_Apply" 9 "ApbReqSource_ExtFunction_Release" 10 "ApbReqSource_BrkPadWearAdj" 11 "ApbReqSource_HapPreparation" 12 "ApbReqSource_ApbBackup" 13 "ApbReqSource_Reserved" ;
VAL_ 452 EMBParkPriCtrlSourceRR 0 "ApbReqSource_NoRequest" 1 "ApbReqSource_RollerTestBench" 2 "ApbReqSource_EmergencyApply" 3 "ApbReqSource_Button_Apply" 4 "ApbReqSource_Button_Release" 5 "ApbReqSource_Button_DclBrkMech" 6 "ApbReqSource_DriveOff_Release" 7 "ApbReqSource_AutoApply" 8 "ApbReqSource_ExtFunction_Apply" 9 "ApbReqSource_ExtFunction_Release" 10 "ApbReqSource_BrkPadWearAdj" 11 "ApbReqSource_HapPreparation" 12 "ApbReqSource_ApbBackup" 13 "ApbReqSource_Reserved" ;
VAL_ 452 EMBParkPriEpbStatusRL 0 "released" 1 " ParkedApplied" 2 "releasing" 3 "Locking" 4 "unknown" 5 "HoldApplied" 6 " CompletelyReleased" 7 "HapPrepared" ;
VAL_ 452 EMBParkPriEpbStatusRR 0 "released" 1 " ParkedApplied" 2 "releasing" 3 "Locking" 4 "unknown" 5 "HoldApplied" 6 " CompletelyReleased" 7 "HapPrepared" ;
VAL_ 452 EMBParkPriFctLampRL 0 "LampOff" 1 "Lamp ON" 2 "Lamp Flashing" 3 "Invalid" ;
VAL_ 452 EMBParkPriFctLampRR 0 "LampOff" 1 "Lamp ON" 2 "Lamp Flashing" 3 "Invalid" ;
VAL_ 452 EMBParkPriFailrLampRL 0 "LampOff" 1 "Lamp ON" 2 "Lamp Flashing" 3 "Invalid" ;
VAL_ 452 EMBParkPriFailrLampRR 0 "LampOff" 1 "Lamp ON" 2 "Lamp Flashing" 3 "Invalid" ;
VAL_ 452 EMBPriVehBrkSysSts 0 "Normal" 1 " DegradLevel1" 2 "DegradLevel2" 3 "DegradLevel3" 4 "DegradLevel4" 5 "DegradLevel5" ;
VAL_ 453 EMB_Sec_SystemFlt 0 "Init" 1 "OFF" 2 "BBF_Limited" 3 "BBF_2_w_S" 4 "BBF_3_wo_S" 5 "BBF_3_ w_S" 6 "BBF_ON_wo_S" 7 "ABS_Reduce" 8 "ABS_ON" ;
VAL_ 453 EMB_Sec_BrkRodStrkVld 0 "Valid" 1 "Invalid" ;
VAL_ 453 EMBParkSecCtrlEnableRL 0 "Disable" 1 "Enable" ;
VAL_ 453 EMBParkSecCtrlEnableRR 0 "Disable" 1 "Enable" ;
VAL_ 453 EMBParkSecAvailabilityRL 0 "init" 1 "not available" 2 "available" ;
VAL_ 453 EMBParkSecAvailabilityRR 0 "init" 1 "not available" 2 "available" ;
VAL_ 453 EMBParkSecCtrlSourceRL 0 "ApbReqSource_NoRequest" 1 "ApbReqSource_RollerTestBench" 2 "ApbReqSource_EmergencyApply" 3 "ApbReqSource_Button_Apply" 4 "ApbReqSource_Button_Release" 5 "ApbReqSource_Button_DclBrkMech" 6 "ApbReqSource_DriveOff_Release" 7 "ApbReqSource_AutoApply" 8 "ApbReqSource_ExtFunction_Apply" 9 "ApbReqSource_ExtFunction_Release" 10 "ApbReqSource_BrkPadWearAdj" 11 "ApbReqSource_HapPreparation" 12 "ApbReqSource_ApbBackup" 13 "ApbReqSource_Reserved" ;
VAL_ 453 EMBParkSecCtrlSourceRR 0 "ApbReqSource_NoRequest" 1 "ApbReqSource_RollerTestBench" 2 "ApbReqSource_EmergencyApply" 3 "ApbReqSource_Button_Apply" 4 "ApbReqSource_Button_Release" 5 "ApbReqSource_Button_DclBrkMech" 6 "ApbReqSource_DriveOff_Release" 7 "ApbReqSource_AutoApply" 8 "ApbReqSource_ExtFunction_Apply" 9 "ApbReqSource_ExtFunction_Release" 10 "ApbReqSource_BrkPadWearAdj" 11 "ApbReqSource_HapPreparation" 12 "ApbReqSource_ApbBackup" 13 "ApbReqSource_Reserved" ;
VAL_ 453 EMBParkSecEpbStatusRL 0 "released" 1 " ParkedApplied" 2 "releasing" 3 "Locking" 4 "unknown" 5 "HoldApplied" 6 " CompletelyReleased" 7 "HapPrepared" ;
VAL_ 453 EMBParkSecEpbStatusRR 0 "released" 1 " ParkedApplied" 2 "releasing" 3 "Locking" 4 "unknown" 5 "HoldApplied" 6 " CompletelyReleased" 7 "HapPrepared" ;
VAL_ 453 EMBParkSecFctLampRL 0 "LampOff" 1 "Lamp ON" 2 "Lamp Flashing" 3 "Invalid" ;
VAL_ 453 EMBParkSecFctLampRR 0 "LampOff" 1 "Lamp ON" 2 "Lamp Flashing" 3 "Invalid" ;
VAL_ 453 EMBParkSecFailrLampRL 0 "LampOff" 1 "Lamp ON" 2 "Lamp Flashing" 3 "Invalid" ;
VAL_ 453 EMBParkSecFailrLampRR 0 "LampOff" 1 "Lamp ON" 2 "Lamp Flashing" 3 "Invalid" ;
VAL_ 453 EMBSecVehBrkSysSts 0 "Normal" 1 " DegradLevel1" 2 "DegradLevel2" 3 "DegradLevel3" 4 "DegradLevel4" 5 "DegradLevel5" ;
VAL_ 467 ESP_LongAccelValid_1 0 "Initializing" 1 "Valid" 2 "Invalid" 3 "Reserved" ;
VAL_ 467 ESP_LatAccelValid_1 0 "Initializing" 1 "Valid" 2 "Invalid" 3 "Reserved" ;
VAL_ 467 ESP_YawRateValid_1 0 "Initializing" 1 " Valid" 2 " Invalid" 3 " Reserved" ;
VAL_ 513 AD_DDSATextInfo 0 "nodisplay" 1 "DDSAS已激活" 2 "驾驶员失能安全辅助功能异常" 3 "reserve" ;
VAL_ 513 ADS_AcrBeltShake 0 "NoRequest" 1 "level 1 " 2 "level 2" 3 "level 3" ;
VAL_ 642 Switch_S2_State 0 "OFF" 1 "ON" ;
VAL_ 642 Switch_K3_State 0 "OFF" 1 "ON" ;
VAL_ 642 Switch_CC2_State 0 "OFF" 1 "ON" ;
VAL_ 642 CPEVTar_v2g_ChgComplete 0 "Incomplete" 1 "Complete" ;
VAL_ 642 EvccS2Sts 0 "断开" 1 "闭合" ;
VAL_ 648 ActualDrvMod 0 "Notset" 1 "Comfort" 2 "Sport" 3 "Eco" 4 "SuperEco" 5 "ATS" 6 "Selfdefined" 7 "CrazyCow" 15 "Invalid" ;
VAL_ 648 BCM_DrivDoorLockSts 0 "Reserved" 1 "Unlock" 2 "Lock" 3 "Unlocking" 4 "Locking" 5 "releasing" 6 "Pull-in-ing" 7 "Invalid" ;
VAL_ 648 BCM_HoodStatus 0 "Close" 1 "Open" ;
VAL_ 648 BCM_TurnLightSwitchSts 0 "NotActived" 1 "Left Actived" 2 "Right Actived" 3 "Invalid" ;
VAL_ 648 BcmAuLiSwtSts 0 "NoActive" 1 "Active" ;
VAL_ 648 BcmDrvrDoorSts 0 "Close" 1 "Open" ;
VAL_ 648 BcmEmgyLiSts 0 "OFF" 1 "ON" 2 "Notused" 3 "Error（故障）" ;
VAL_ 648 BcmHiBeSwtSts 0 "NoActive" 1 "Active" ;
VAL_ 648 BcmKeyAlrmSts 0 "Disarmed" 1 "Prearmed" 2 "Armed" 3 "Activated" ;
VAL_ 648 BcmLeReDoorSts 0 "Close" 1 "Open" ;
VAL_ 648 BcmLoBeSwtSts 0 "NoActive" 1 "Active" ;
VAL_ 648 BcmOvTaLiSwtSts 0 "NoActive" 1 "Active" ;
VAL_ 648 BcmPassDoorSts 0 "Close" 1 "Open" ;
VAL_ 648 BcmPwrStsFb 0 "Off" 1 "Reserve" 2 "ON" 3 "Reserve" ;
VAL_ 648 BcmRiReDoorSts 0 "Close" 1 "Open" ;
VAL_ 648 BcmTurnIndcrLe 0 "OFF" 1 "ON" 2 "Notused" 3 "Error" ;
VAL_ 648 BcmTurnIndcrRi 0 "OFF" 1 "ON" 2 "Notused" 3 "Error" ;
VAL_ 648 BdcDrvrSts 0 "无人" 1 "有人" ;
VAL_ 648 LoChrgSts 0 "idle" 1 "running" 2 "reserved" 3 "end running" ;
VAL_ 648 VIU_DriverADEDSts 0 "NoError" 1 "Error" ;
VAL_ 648 VIU_PassengerADEDSts 0 "NoError" 1 "Error" ;
VAL_ 648 VIUACModReq 0 "Notset," 1 "Eco" 2 "Normal" ;
VAL_ 648 WakeUpForbidden 0 "不禁用唤醒" 1 "禁用唤醒" ;
VAL_ 677 BcuBattHeatActv 0 "Notactive" 1 "active" 2 "电池保温中" ;
VAL_ 677 DcChrgCnctrSts 0 "未连接" 1 "充电枪完全连接" 2 "连接异常" 3 "接头连接状态" 4 "直流放电抢连接" ;
VAL_ 680 TmsAcEnvtlT 255 "Invalid" ;
VAL_ 680 TmsAcEnvtlTVld 0 "Valid" 1 "Invalid" ;
VAL_ 681 ObcS2Ctrl 0 "断开" 1 "闭合" ;
VAL_ 689 AMP_AVASSoundSourceStatus 0 "off" 1 "on" ;
VAL_ 689 AMP_KTVSoundSourceStatus 0 "off" 1 "on" ;
VAL_ 689 AMP_LFWarnSoundSourceStatus 0 "off" 1 "on" ;
VAL_ 689 AMP_LRWarnSoundSourceStatus 0 "off" 1 "on" ;
VAL_ 689 AMP_MediaSoundSourceStatus 0 "off" 1 "on" ;
VAL_ 689 AMP_MidWarnSoundSourceStatus 0 "off" 1 "on" ;
VAL_ 689 AMP_NAVISoundSourceStatus 0 "off" 1 "on" ;
VAL_ 689 AMP_OutSoundSourceStatus 0 "off" 1 "on" ;
VAL_ 689 AMP_RFWarnSoundSourceStatus 0 "off" 1 "on" ;
VAL_ 689 AMP_RRWarnSoundSourceStatus 0 "off" 1 "on" ;
VAL_ 689 AMP_SystemSoundSourceStatus 0 "off" 1 "on" ;
VAL_ 689 AMP_TELSoundSourceStatus 0 "off" 1 "on" ;
VAL_ 689 AMP_TurnLightSoundSourceStatus 0 "off" 1 "on" ;
VAL_ 689 AMP_VRSoundSourceStatus 0 "off" 1 "on" ;
VAL_ 690 VcuDcChrgLckReq 0 "无请求" 1 "解锁请求" 2 "闭锁请求" 3 "预留" ;
VAL_ 699 AD_APASysEnaSta 0 "Off//泊车系统关闭状态" 1 "APA On//车内泊车开启状态" 2 "RPA On by CAR//车内开启车外泊车状态" 3 "RPA On by APP//APP遥控泊车开启状态" 4 "RPA On by KEY//钥匙遥控泊车开启状态" 5 "RMA On//远程泊车开启状态" 6 "RADS On//循迹倒车开启状态" 7 "HZP On//记忆泊车开启状态" 8 "RPA On by Voice//语音遥控泊车" ;
VAL_ 699 AD_APAOnOff 0 "OFF" 1 "ON" ;
VAL_ 722 AcRemStartSts 0 "off" 1 "on" ;
VAL_ 722 CdcAntiRustFctSet 0 "norequest" 1 "Off" 2 "On" 3 "Reserved" ;
VAL_ 722 CdcAqsOpenSet 0 "NoReq" 1 "Off" 2 "On" 3 "Press" ;
VAL_ 722 CdcAutoApplyFctSet 0 "norequest" 1 "Off" 2 "On" 3 "Reserved" ;
VAL_ 722 CdcAutoDefrstDefogStsReq 0 "无请求" 1 "关闭" 2 "开启" 3 "预留" ;
VAL_ 722 CdcAutoWindLongPressSet 0 "Notset" 1 "on" 2 "Off" 3 "Reserved" ;
VAL_ 722 CdcAutoWindUnlockSet 0 "Notset" 1 "on" 2 "Off" 3 "Reserved" ;
VAL_ 722 CdcAVHFctSet 0 "norequest" 1 "Off" 2 "On" 3 "Reserved" ;
VAL_ 722 CdcBacktWindLvlSetReq 0 "无请求" 1 "开启" 2 "关闭" 3 "预留" ;
VAL_ 722 CdcBattPlsHeatgSet 0 "无请求" 1 "开启" 2 "关闭" 3 "预留" ;
VAL_ 722 CdcBDWFctSet 0 "norequest" 1 "Off" 2 "On" 3 "Reserved" ;
VAL_ 722 CdcBrkPedlModSet 0 "norequest" 1 "舒适模式" 2 "运动模式" 3 "custom" ;
VAL_ 722 CdcCycModSet 0 "NoReq" 1 "REC" 2 "FRS" 3 "AUTO RNAF" 4 "RECNAFRS" ;
VAL_ 722 CdcEpbSwtSet 0 "norequest" 1 "apply" 2 "Release" 3 "Reserved" ;
VAL_ 722 CdcEspFctSet 0 "norequest" 1 "Off" 2 "On" 3 "Reserved" ;
VAL_ 722 CdcFrntAutModOpenSet 0 "Notreq" 1 "Req" 2 "reserved" 3 "invalid" ;
VAL_ 722 CdcFrntBlowModSet 0 "NoReq" 1 "Face" 2 "Face/Foot" 3 "Foot" 4 "Foot/Def" 5 "Def" 6 "Face/Def" 7 "Face/Foot/Def" 8 "Mode" ;
VAL_ 722 CdcFrntDefrosterSet 0 "Notreq" 1 "Off" 2 "ON" 3 "DEF" ;
VAL_ 722 CdcFrntWindLvlSet 0 "noreq" 1 "Level 1" 2 "Level 2" 3 "Level 3" 4 "Level 4" 5 "Level 5" 6 "Level 6" 7 "Level 7" 8 "Level 8" 9 "UP Req" 10 "DOWN Req" ;
VAL_ 722 CdcFrontAcOffSet 0 "Notreq" 1 "ON" 2 "OFF" 3 "PRESS" ;
VAL_ 722 CdcHDCFctSet 0 "norequest" 1 "Off" 2 "On" 3 "Reserved" ;
VAL_ 722 CdcHotColdModStReq 0 "无请求" 1 "制冷" 2 "制热" 3 "通风" 4 "自动制冷制热" ;
VAL_ 722 CdcIBCUDrvModSet 0 "Notset" 1 "Normal" 2 "Sport" 3 " Trail(ATS)" ;
VAL_ 722 CdcORCAFctSet 0 "norequest" 1 "Off" 2 "On" 3 "Reserved" ;
VAL_ 722 CdcPassTSet 0 "noreq" 1 "LO" 31 "HI" 32 "up req" 33 "down req" 63 "Invalid" ;
VAL_ 722 CdcPlasmaOpenSet 0 "Notreq" 1 "Ionizer On" 2 "Ionizer Off" 3 "Ionizer_Req" ;
VAL_ 722 CdcSteerModSet 0 "StandarMode" 1 "Comfort Mode" 2 "Sport Mode" 3 "custom Mode" ;
VAL_ 722 CdcVehEgyCnseSelect 0 "无请求" 1 "CLTC工况" 2 "WLTC工况" 3 "动态工况" ;
VAL_ 722 CdcVentnOnSet 0 "Inactive" 1 "OFF" 2 "Default" 3 "User Defined" ;
VAL_ 722 CdcWorkSpaceSet 0 "NoReq" 1 "Off" 2 "On" 3 "Press" ;
VAL_ 722 CST_OFF_Switch 0 "norequest" 1 "OFF" 2 "On-lev1" 3 "On-lev2" 4 "On-lev3" ;
VAL_ 722 HU_ACRearFanAdjustValueReq 0 "NoReq" 9 "UP Req" 10 "DOWN Req" ;
VAL_ 722 HU_ACRearModeAdjustReq 0 "NoReq" 1 "Face" 2 "Face/Foot" 3 "Foot" 4 "Reserved" 5 "PressFaceArea" 6 "PressFootArea" 7 "Mode" ;
VAL_ 722 HU_AutowindSet3 0 "Notset" 1 "ON" 2 "OFF" 3 "Reserved" ;
VAL_ 722 HU_MaxACReq 0 "NoReq" 1 "Off" 2 "On" 3 "Press" ;
VAL_ 722 HU_MaxDefReq 0 "NoReq" 1 "Off" 2 "On" 3 "Press" ;
VAL_ 722 HU_MaxHeatReq 0 "NoReq" 1 "Off" 2 "On" 3 "Press" ;
VAL_ 722 HU_RearACOfffReq 0 "NoReq" 1 "ON" 2 "OFF" 3 "Press" ;
VAL_ 722 HU_RearAUTOACOnReq 0 "NoReq" 1 "Req" 2 "Reserved" 3 "Invalid" ;
VAL_ 722 HU_RefreshModeEnable 0 "Inactive" 1 "主驾清新提神" 2 "副驾清新提神" 3 "前排清新提神" ;
VAL_ 722 HU_Request_AFUchannel 0 "inactive" 1 "1通道" 2 "2通道" 3 "3通道" ;
VAL_ 722 HU_Request_AFUContentleve 0 "inactive" 1 "1档" 2 "2档" 3 "3档" 4 "4档" 5 "5档" 6 "6档" 7 "7档" 8 "8档" 9 "9档" 10 "10档" 11 "11档" 12 "12档" 13 "13档" 14 "14档" 15 "15档" ;
VAL_ 722 HU_Request_AFUSt 0 "inactive" 1 "OFF" 2 "ON" 3 "Reserve" ;
VAL_ 722 HU_RollerbenchSetStaus 0 "norequest" 1 "Off" 2 "On" 3 "Reserved" ;
VAL_ 722 HU_VentilationSetAfternoon 0 "Inactive" 1 "12=30" 2 "13=00" 3 "13=30" 4 "14=00" 5 "14=30" 6 "15=00" 7 "15=30" 8 "16=00" 9 "16=30" 10 "17=00" 11 "17=30" 12 "18=00" 13 "18=30" ;
VAL_ 722 HU_VentilationSetEvening 0 "Inactive" 1 "19=00" 2 "19=30" 3 "20=00" 4 "20=30" 5 "21=00" 6 "21=30" 7 "22=00" 8 "22=30" ;
VAL_ 722 HU_VentilationSetMorning 0 "Inactive" 1 "6=30" 2 "7=00" 3 "7=30" 4 "8=00" 5 "8=30" 6 "9=00" 7 "9=30" 8 "10=00" 9 "10=30" 10 "11=00" 11 "11=30" 12 "12=00" ;
VAL_ 722 HUAcEgySaveModReq 0 "NoReq" 1 "Off" 2 "On" 3 "Press" ;
VAL_ 722 HUAutoAirCleanReq 0 "NoReq" 1 "Off" 2 "On" 3 "Press" ;
VAL_ 722 HUBatPulseHeatSwitchReq 0 "NoReq" 1 "Off" 2 "On" 3 "Press" ;
VAL_ 722 HUMotLockHeatSwitchReq 0 "NoReq" 1 "Off" 2 "On" 3 "Press" ;
VAL_ 722 HUSngPrsnModReq 0 "NoReq" 1 "Off" 2 "On" 3 "Press" ;
VAL_ 722 VIUDrvModSet 0 "Notset" 1 "Comfort" 2 "Sport" 3 "Eco" 4 "SuperEco" 5 "ATS" 6 "Selfdefined" 7 "CrazyCow" 8 "Offroad" 9 "Snow" 10 "Sand" 12 "AISport" 15 "Invalid" ;
VAL_ 753 RCM_RLTuLiSt 0 "左后转向灯未开启" 1 "左后转向灯开启" ;
VAL_ 753 RCM_RRTuLiSt 0 "右后转向灯未开启" 1 "右后转向灯开启" ;
VAL_ 759 TboxLocalTiVld 0 "Valid" 1 "Invalid" ;
VAL_ 760 Tbox_GPSLocalTiVld 0 "Valid" 1 "Invalid" ;
VAL_ 774 AC_ACOnOff 0 "OFF" 1 "ON" 2 "not used" 3 "invalid" ;
VAL_ 774 ITMSLiquidLevel 0 "reserved" 1 "液位正常" 2 "液位低" 3 "无效值" ;
VAL_ 779 CdcIPScreenLiOnSts 0 "点亮" 1 "熄灭" ;
VAL_ 779 IP_DISFail 0 "noerror" 1 "error" ;
VAL_ 779 IP_juADASshowinfa 0 "noerror" 1 "error" ;
VAL_ 779 IP_juADASshowoutfa 0 "noerror" 1 "error" ;
VAL_ 779 IP_juADAStsE2Efaout 0 "noerror" 1 "error" ;
VAL_ 779 IP_QDashACCFail 0 "noerror" 1 "error" 2 "reserved" 3 "reserved" ;
VAL_ 779 AD_EDCCrtSts 0 "NotActive激活状态" 1 " Active激活状态" 2 "Error故障状态" ;
VAL_ 779 TboxDoorLockRemCtrlReq 0 "无效值（默认值）" 1 "解锁" 2 "闭锁" ;
VAL_ 784 AMP_FLHighSpeakerDelaySETStatus 0 "invalid" 1 "0ms" 2 "0.5ms" 3 "1ms" 4 "1.5ms" 5 "2ms" ;
VAL_ 784 AMP_FLHighSpeakerVolSETStatus 0 "Step0" 1 "Step1" 20 "Step20" 31 "invalid" ;
VAL_ 784 AMP_FLMidSpeakerDelaySETStatus 0 "invalid" 1 "0ms" 2 "0.5ms" 3 "1ms" 4 "1.5ms" 5 "2ms" ;
VAL_ 784 AMP_FLMidSpeakerVolSETStatus 0 "Step0" 1 "Step1" 20 "Step20" 31 "invalid" ;
VAL_ 784 AMP_FRHighSpeakerDelaySETStatus 0 "invalid" 1 "0ms" 2 "0.5ms" 3 "1ms" 4 "1.5ms" 5 "2ms" ;
VAL_ 784 AMP_FRHighSpeakerVolSETStatus 0 "Step0" 1 "Step1" 20 "Step20" 31 "invalid" ;
VAL_ 784 AMP_FRMidSpeakerDelaySETStatus 0 "invalid" 1 "0ms" 2 "0.5ms" 3 "1ms" 4 "1.5ms" 5 "2ms" ;
VAL_ 784 AMP_FRMidSpeakerVolSETStatus 0 "Step0" 1 "Step1" 20 "Step20" 31 "invalid" ;
VAL_ 784 AMP_AlarmVolSETStatus 0 "invalid" 1 "低" 2 "中" 3 "高" ;
VAL_ 784 AMP_AvasVolSETStatus 0 "invalid" 1 "低" 2 "中" 3 "高" ;
VAL_ 784 AMP_CenterSpeakerDelaySETStatus 0 "invalid" 1 "0ms" 2 "0.5ms" 3 "1ms" 4 "1.5ms" 5 "2ms" ;
VAL_ 784 AMP_CenterSpeakerVolSETStatus 0 "Step0" 1 "Step1" 20 "Step20" 31 "invalid" ;
VAL_ 784 AMP_CustomEffectSETStatus 0 "Inactive" 1 "仅专业自定义频段设置生效（3段）" 2 "仅自定义频段设置生效（9段）" 3 "失效" 4 "自定义频段设置生效（7段）" 5 "Beososic" ;
VAL_ 784 AMP_CustomEQ125SET 0 "invalid" 1 "-7" 2 "-6" 8 "0" 14 "6" 15 "7" ;
VAL_ 784 AMP_CustomEQ16KSET 0 "invalid" 1 "-7" 2 "-6" 8 "0" 14 "6" 15 "7" ;
VAL_ 784 AMP_CustomEQ1KSET 0 "invalid" 1 "-7" 2 "-6" 8 "0" 14 "6" 15 "7" ;
VAL_ 784 AMP_CustomEQ250SET 0 "invalid" 1 "-7" 2 "-6" 8 "0" 14 "6" 15 "7" ;
VAL_ 784 AMP_CustomEQ2KSET 0 "invalid" 1 "-7" 2 "-6" 8 "0" 14 "6" 15 "7" ;
VAL_ 784 AMP_CustomEQ4KSET 0 "invalid" 1 "-7" 2 "-6" 8 "0" 14 "6" 15 "7" ;
VAL_ 784 AMP_CustomEQ500SET 0 "invalid" 1 "-7" 2 "-6" 8 "0" 14 "6" 15 "7" ;
VAL_ 784 AMP_CustomEQ62SET 0 "invalid" 1 "-7" 2 "-6" 8 "0" 14 "6" 15 "7" ;
VAL_ 784 AMP_CustomEQ8KSET 0 "invalid" 1 "-7" 2 "-6" 8 "0" 14 "6" 15 "7" ;
VAL_ 784 AMP_FLLowSpeakerDelaySETStatus 0 "invalid" 1 "0ms" 2 "0.5ms" 3 "1ms" 4 "1.5ms" 5 "2ms" ;
VAL_ 784 AMP_FLLowSpeakerVolSETStatus 0 "Step0" 1 "Step1" 20 "Step20" 31 "invalid" ;
VAL_ 784 AMP_FLMidHighSpeakerDelaySETStat 0 "invalid" 1 "0ms" 2 "0.5ms" 3 "1ms" 4 "1.5ms" 5 "2ms" ;
VAL_ 784 AMP_FLMidHighSpeakerVolSETStatus 0 "Step0" 1 "Step1" 20 "Step20" 31 "invalid" ;
VAL_ 784 AMP_FLTopSpeakerDelaySETStatus 0 "invalid" 1 "0ms" 2 "0.5ms" 3 "1ms" 4 "1.5ms" 5 "2ms" ;
VAL_ 784 AMP_FLTopSpeakerVolSETStatus 0 "Step0" 1 "Step1" 20 "Step20" 31 "invalid" ;
VAL_ 784 AMP_FRBalanceSETStatus 0 "invalid" 1 "-7" 2 "-6" 8 "0" 14 "6" 15 "7" ;
VAL_ 784 AMP_FRLowSpeakerDelaySETStatus 0 "invalid" 1 "0ms" 2 "0.5ms" 3 "1ms" 4 "1.5ms" 5 "2ms" ;
VAL_ 784 AMP_FRLowSpeakerVolSETStatus 0 "Step0" 1 "Step1" 20 "Step20" 31 "invalid" ;
VAL_ 784 AMP_FRMidHighSpeakerDelaySET 0 "invalid" 1 "0ms" 2 "0.5ms" 3 "1ms" 4 "1.5ms" 5 "2ms" ;
VAL_ 784 AMP_FRMidHighSpeakerVolSETStatus 0 "Step0" 1 "Step1" 20 "Step20" 31 "invalid" ;
VAL_ 784 AMP_FRTopSpeakerDelaySETStatus 0 "invalid" 1 "0ms" 2 "0.5ms" 3 "1ms" 4 "1.5ms" 5 "2ms" ;
VAL_ 784 AMP_FRTopSpeakerVolSETStatus 0 "Step0" 1 "Step1" 20 "Step20" 31 "invalid" ;
VAL_ 784 AMP_KTVMUTESETStatus 0 "invalid" 1 "静音" 2 "非静音" 3 "reserved" ;
VAL_ 784 AMP_KTVVolSETStatus 0 "Step0" 1 "Step1" 20 "Step20" 31 "invalid" ;
VAL_ 784 AMP_LRBalanceSETStatus 0 "invalid" 1 "-7" 2 "-6" 8 "0" 14 "6" 15 "7" ;
VAL_ 784 AMP_MediaMUTESETStatus 0 "invalid" 1 "静音" 2 "非静音" 3 "reserved" ;
VAL_ 784 AMP_MediaVolSETStatus 0 "Step0" 1 "Step1" 20 "Step20" 31 "invalid" ;
VAL_ 784 AMP_MUTESETStatus 0 "invalid" 1 "静音" 2 "非静音" 3 "reserved" ;
VAL_ 784 AMP_NaviMUTESETStatus 0 "invalid" 1 "静音" 2 "非静音" 3 "reserved" ;
VAL_ 784 AMP_NAVIVolSETStatus 0 "Step0" 1 "Step1" 20 "Step20" 31 "invalid" ;
VAL_ 784 AMP_OutMUTESETStatus 0 "invalid" 1 "静音" 2 "非静音" 3 "reserved" ;
VAL_ 784 AMP_OUTVolSETStatus 0 "Step0" 1 "Step1" 20 "Step20" 31 "invalid" ;
VAL_ 784 AMP_PerfessiionalEQ100SET 0 "invalid" 1 "-7" 2 "-6" 8 "0" 14 "6" 15 "7" ;
VAL_ 784 AMP_PerfessiionalEQ500SET 0 "invalid" 1 "-7" 2 "-6" 8 "0" 14 "6" 15 "7" ;
VAL_ 784 AMP_PerfessiionalEQ6KSET 0 "invalid" 1 "-7" 2 "-6" 8 "0" 14 "6" 15 "7" ;
VAL_ 784 AMP_RLLowHighSpeakerDelaySETStat 0 "invalid" 1 "0ms" 2 "0.5ms" 3 "1ms" 4 "1.5ms" 5 "2ms" ;
VAL_ 784 AMP_RLLowHighSpeakerVolSETStatus 0 "Step0" 1 "Step1" 20 "Step20" 31 "invalid" ;
VAL_ 784 AMP_RLSurroundSpeakerDelaySETSta 0 "invalid" 1 "0ms" 2 "0.5ms" 3 "1ms" 4 "1.5ms" 5 "2ms" ;
VAL_ 784 AMP_RLSurroundSpeakerVolSETStatu 0 "Step0" 1 "Step1" 20 "Step20" 31 "invalid" ;
VAL_ 784 AMP_RLTopSpeakerDelaySETStatus 0 "invalid" 1 "0ms" 2 "0.5ms" 3 "1ms" 4 "1.5ms" 5 "2ms" ;
VAL_ 784 AMP_RLTopSpeakerVolSETStatus 0 "Step0" 1 "Step1" 20 "Step20" 31 "invalid" ;
VAL_ 784 AMP_RNCEnableSETStatus 0 "invalid" 1 "开启" 2 "关闭" 3 "reserved" ;
VAL_ 784 AMP_RRLowHighSpeakerDelaySET 0 "invalid" 1 "0ms" 2 "0.5ms" 3 "1ms" 4 "1.5ms" 5 "2ms" ;
VAL_ 784 AMP_RRLowHighSpeakerVolSETStatus 0 "Step0" 1 "Step1" 20 "Step20" 31 "invalid" ;
VAL_ 784 AMP_RRSurroundSpeakerDelaySETSta 0 "invalid" 1 "0ms" 2 "0.5ms" 3 "1ms" 4 "1.5ms" 5 "2ms" ;
VAL_ 784 AMP_RRSurroundSpeakerVolSET 0 "Step0" 1 "Step1" 20 "Step20" 31 "invalid" ;
VAL_ 784 AMP_RRTopSpeakerDelaySETStatus 0 "invalid" 1 "0ms" 2 "0.5ms" 3 "1ms" 4 "1.5ms" 5 "2ms" ;
VAL_ 784 AMP_RRTopSpeakerVolSETStatus 0 "Step0" 1 "Step1" 20 "Step20" 31 "invalid" ;
VAL_ 784 AMP_SoundEffectSETStatus 0 "invalid" 1 "音效1（HIFI原声）" 2 "音效2（沉浸环绕）" 3 "音效3（预留）" 4 "音效4（交响乐厅）" 5 "音效5（预留）" 6 "音效6（露营嗨唱）" 7 "音效7" 8 "音效8" 9 "音效9" 10 "音效10" 11 "音效11（寰宇影院）" 12 "音效12（调音大师）" ;
VAL_ 784 AMP_SoundFieldSETStatus 0 "invalid" 1 "自定义（CX810无）" 2 "主驾模式" 3 "均衡模式（全车模式）" 4 "左后模式" 5 "右后模式" 6 "副驾模式" ;
VAL_ 784 AMP_SubSpeakerDelaySETStatus 0 "invalid" 1 "0ms" 2 "0.5ms" 3 "1ms" 4 "1.5ms" 5 "2ms" ;
VAL_ 784 AMP_SubSpeakerVolSETStatus 0 "Step0" 1 "Step1" 20 "Step20" 31 "invalid" ;
VAL_ 784 AMP_SystemMUTESETStatus 0 "invalid" 1 "静音" 2 "非静音" 3 "reserved" ;
VAL_ 784 AMP_SystemVolSETStatus 0 "Step0" 1 "Step1" 20 "Step20" 31 "invalid" ;
VAL_ 784 AMP_TelBcallMUTESETStatus 0 "invalid" 1 "静音" 2 "非静音" 3 "reserved" ;
VAL_ 784 AMP_TELBCALLVolSETStatus 0 "Step0" 1 "Step1" 20 "Step20" 31 "invalid" ;
VAL_ 784 AMP_TTSVRMUTESETStatus 0 "invalid" 1 "静音" 2 "非静音" 3 "reserved" ;
VAL_ 784 AMP_TTSVRVolSETStatus 0 "Step0" 1 "Step1" 20 "Step20" 31 "invalid" ;
VAL_ 784 AMP_TurnLightInOrOutSETStatus 0 "invalid" 1 "in" 2 "out" ;
VAL_ 784 AMP_TurnLightVolSETStatus 0 "invalid" 1 "低" 2 "中" 3 "高" ;
VAL_ 784 AMP_VOLSpeedEnableSETStatus 0 "invalid" 1 "关闭" 2 "打开" 3 "=reserved" ;
VAL_ 800 AMPFLPositionDelaySETStatus 0 "invalid" 1 "0ms" 2 "0.5ms" 3 "1ms" 4 "1.5ms" 5 "2ms" ;
VAL_ 800 AMPFLPositionVolSETStatus 0 "invalid" 1 "-3" 2 "-2" 3 "-1" 4 "0" 5 "1" 6 "2" 7 "3" ;
VAL_ 800 AMPFRPositionDelaySETStatus 0 "invalid" 1 "0ms" 2 "0.5ms" 3 "1ms" 4 "1.5ms" 5 "2ms" ;
VAL_ 800 AMPFRPositionVolSETStatus 0 "invalid" 1 "-3" 2 "-2" 3 "-1" 4 "0" 5 "1" 6 "2" 7 "3" ;
VAL_ 800 AMPBeosonicModeSetStatus 0 "invalid" 1 "Lounge" 2 "Party" 3 "Podcast" 4 "Custom" ;
VAL_ 800 AMPBeosonicXSetStatus 0 "invalid" 1 "-10" 2 "-9" 11 "0" 20 "9" 21 "10" ;
VAL_ 800 AMPBeosonicYSetStatus 0 "invalid" 1 "-10" 2 "-9" 11 "0" 20 "9" 21 "10" ;
VAL_ 800 AMPCenterPositionDelaySETStatus 0 "invalid" 1 "0ms" 2 "0.5ms" 3 "1ms" 4 "1.5ms" 5 "2ms" ;
VAL_ 800 AMPCenterPositionVolSETStatus 0 "invalid" 1 "-3" 2 "-2" 3 "-1" 4 "0" 5 "1" 6 "2" 7 "3" ;
VAL_ 800 AMPCustomEQ2500SET 0 "invalid" 1 "-7" 2 "-6" 8 "0" 14 "6" 15 "7" ;
VAL_ 800 AMPCustomEQ315SET 0 "invalid" 1 "-7" 2 "-6" 8 "0" 14 "6" 15 "7" ;
VAL_ 800 AMPCustomEQ50SET 0 "invalid" 1 "-7" 2 "-6" 8 "0" 14 "6" 15 "7" ;
VAL_ 800 AMPCustomEQ6000SET 0 "invalid" 1 "-7" 2 "-6" 8 "0" 14 "6" 15 "7" ;
VAL_ 800 AMPCustomEQ800SET 0 "invalid" 1 "-7" 2 "-6" 8 "0" 14 "6" 15 "7" ;
VAL_ 800 AMPFLTopPositionDelaySETStatus 0 "invalid" 1 "0ms" 2 "0.5ms" 3 "1ms" 4 "1.5ms" 5 "2ms" ;
VAL_ 800 AMPFLTopPositionVolSETStatus 0 "invalid" 1 "-3" 2 "-2" 3 "-1" 4 "0" 5 "1" 6 "2" 7 "3" ;
VAL_ 800 AMPFRTopPositionDelaySETStatus 0 "invalid" 1 "0ms" 2 "0.5ms" 3 "1ms" 4 "1.5ms" 5 "2ms" ;
VAL_ 800 AMPFRTopPositionVolSETStatus 0 "invalid" 1 "-3" 2 "-2" 3 "-1" 4 "0" 5 "1" 6 "2" 7 "3" ;
VAL_ 800 AMPRLPositionDelaySETStatus 0 "invalid" 1 "0ms" 2 "0.5ms" 3 "1ms" 4 "1.5ms" 5 "2ms" ;
VAL_ 800 AMPRLPositionVolSETStatus 0 "invalid" 1 "-3" 2 "-2" 3 "-1" 4 "0" 5 "1" 6 "2" 7 "3" ;
VAL_ 800 AMPRLSurroundDelaySETStatus 0 "invalid" 1 "0ms" 2 "0.5ms" 3 "1ms" 4 "1.5ms" 5 "2ms" ;
VAL_ 800 AMPRLSurroundVolSETStatus 0 "invalid" 1 "-3" 2 "-2" 3 "-1" 4 "0" 5 "1" 6 "2" 7 "3" ;
VAL_ 800 AMPRLTopDelaySETStatus 0 "invalid" 1 "0ms" 2 "0.5ms" 3 "1ms" 4 "1.5ms" 5 "2ms" ;
VAL_ 800 AMPRLTopVolSETStatus 0 "invalid" 1 "-3" 2 "-2" 3 "-1" 4 "0" 5 "1" 6 "2" 7 "3" ;
VAL_ 800 AMPRRPositionDelaySET 0 "invalid" 1 "0ms" 2 "0.5ms" 3 "1ms" 4 "1.5ms" 5 "2ms" ;
VAL_ 800 AMPRRPositionVolSETStatus 0 "invalid" 1 "-3" 2 "-2" 3 "-1" 4 "0" 5 "1" 6 "2" 7 "3" ;
VAL_ 800 AMPRRSurroundPositionDelaySETSta 0 "invalid" 1 "0ms" 2 "0.5ms" 3 "1ms" 4 "1.5ms" 5 "2ms" ;
VAL_ 800 AMPRRSurroundPositionVolSET 0 "invalid" 1 "-3" 2 "-2" 3 "-1" 4 "0" 5 "1" 6 "2" 7 "3" ;
VAL_ 800 AMPRRTopPositionDelaySETStatus 0 "invalid" 1 "0ms" 2 "0.5ms" 3 "1ms" 4 "1.5ms" 5 "2ms" ;
VAL_ 800 AMPRRTopPositionVolSETStatus 0 "invalid" 1 "-3" 2 "-2" 3 "-1" 4 "0" 5 "1" 6 "2" 7 "3" ;
VAL_ 800 AMPSoundSourceTypeStatus 0 "invalid" 1 "立体声" 2 "7.1.4" 3 "reserved" ;
VAL_ 800 AMPSubPositionDelaySETStatus 0 "invalid" 1 "0ms" 2 "0.5ms" 3 "1ms" 4 "1.5ms" 5 "2ms" ;
VAL_ 800 AMPSubPositionVolSETStatus 0 "invalid" 1 "-3" 2 "-2" 3 "-1" 4 "0" 5 "1" 6 "2" 7 "3" ;
VAL_ 800 AMPTMCenterPositionEQ15000HzSetS 0 "invalid" 1 "-3" 2 "-2" 3 "-1" 4 "0" 5 "1" 6 "2" 7 "3" ;
VAL_ 800 AMPTMCenterPositionEQ800HzSetSta 0 "invalid" 1 "-3" 2 "-2" 3 "-1" 4 "0" 5 "1" 6 "2" 7 "3" ;
VAL_ 800 AMPTMFLPositionEQ100HzSetStatus 0 "invalid" 1 "-3" 2 "-2" 3 "-1" 4 "0" 5 "1" 6 "2" 7 "3" ;
VAL_ 800 AMPTMFLPositionEQ15000HzSetStatu 0 "invalid" 1 "-3" 2 "-2" 3 "-1" 4 "0" 5 "1" 6 "2" 7 "3" ;
VAL_ 800 AMPTMFLPositionEQ800HzSetStatus 0 "invalid" 1 "-3" 2 "-2" 3 "-1" 4 "0" 5 "1" 6 "2" 7 "3" ;
VAL_ 800 AMPTMFLTopPositionEQ500HzSetStat 0 "invalid" 1 "-3" 2 "-2" 3 "-1" 4 "0" 5 "1" 6 "2" 7 "3" ;
VAL_ 800 AMPTMFRPositionEQ100HzSetStatus 0 "invalid" 1 "-3" 2 "-2" 3 "-1" 4 "0" 5 "1" 6 "2" 7 "3" ;
VAL_ 800 AMPTMFRPositionEQ15000HzSetStatu 0 "invalid" 1 "-3" 2 "-2" 3 "-1" 4 "0" 5 "1" 6 "2" 7 "3" ;
VAL_ 800 AMPTMFRPositionEQ800HzSetStatus 0 "invalid" 1 "-3" 2 "-2" 3 "-1" 4 "0" 5 "1" 6 "2" 7 "3" ;
VAL_ 800 AMPTMFRTopPositionEQ500HzSetStat 0 "invalid" 1 "-3" 2 "-2" 3 "-1" 4 "0" 5 "1" 6 "2" 7 "3" ;
VAL_ 800 AMPTMReverbSetStatus 0 "invalid" 1 "1" 2 "2" 3 "3" 100 "100" ;
VAL_ 800 AMPTMRLPositionEQ10000HzSetStatu 0 "invalid" 1 "-3" 2 "-2" 3 "-1" 4 "0" 5 "1" 6 "2" 7 "3" ;
VAL_ 800 AMPTMRLPositionEQ100HzSetStatusS 0 "invalid" 1 "-3" 2 "-2" 3 "-1" 4 "0" 5 "1" 6 "2" 7 "3" ;
VAL_ 800 AMPTMRLSurroundPositionEQ15000Hz 0 "invalid" 1 "-3" 2 "-2" 3 "-1" 4 "0" 5 "1" 6 "2" 7 "3" ;
VAL_ 800 AMPTMRLSurroundPositionEQ800HzSe 0 "invalid" 1 "-3" 2 "-2" 3 "-1" 4 "0" 5 "1" 6 "2" 7 "3" ;
VAL_ 800 AMPTMRLTopPositionEQ500HzSetStat 0 "invalid" 1 "-3" 2 "-2" 3 "-1" 4 "0" 5 "1" 6 "2" 7 "3" ;
VAL_ 800 AMPTMRRPositionEQ10000HzSetStatu 0 "invalid" 1 "-3" 2 "-2" 3 "-1" 4 "0" 5 "1" 6 "2" 7 "3" ;
VAL_ 800 AMPTMRRPositionEQ100HzSetStatus 0 "invalid" 1 "-3" 2 "-2" 3 "-1" 4 "0" 5 "1" 6 "2" 7 "3" ;
VAL_ 800 AMPTMRRSurroundPositionEQ15000Hz 0 "invalid" 1 "-3" 2 "-2" 3 "-1" 4 "0" 5 "1" 6 "2" 7 "3" ;
VAL_ 800 AMPTMRRSurroundPositionEQ800HzSe 0 "invalid" 1 "-3" 2 "-2" 3 "-1" 4 "0" 5 "1" 6 "2" 7 "3" ;
VAL_ 800 AMPTMRRTopPositionEQ500HzSetStat 0 "invalid" 1 "-3" 2 "-2" 3 "-1" 4 "0" 5 "1" 6 "2" 7 "3" ;
VAL_ 800 AMPTMSubPositionEQ30HzSetStatusS 0 "invalid" 1 "-3" 2 "-2" 3 "-1" 4 "0" 5 "1" 6 "2" 7 "3" ;
VAL_ 800 AMPVOLSpeedLevChangeSETStatus 0 "invalid" 1 "关闭" 2 "低" 3 "中" 4 "高" ;
VAL_ 802 ECASAdjBySpd 0 "Inactive" 1 "Active " ;
VAL_ 802 ECASaftaxladjsts 0 "idle" 1 "up" 2 "down" ;
VAL_ 802 ECASerromode 0 "error_mode_0(nofault)" 1 "error_mode_1 (light error)" 2 "error_mode_2 (heavy error)" 3 "error_mode_3 (heavy actor fault)" 4 "Reserved" ;
VAL_ 802 ECASfrtaxladjsts 0 "idle" 1 "up" 2 "down" ;
VAL_ 802 EcasModeCHASts 0 "Idle" 1 "up" 2 "down" 3 "Switch fail" 4 "ready to Switch " ;
VAL_ 802 EcasModeFB 0 "Normal" 1 "sport" 2 "Off road" 3 "Comfort" 4 "Auto" 5 "Access" 6 "Load" 7 "Level" 8 "Trailer mode" 9 "maintenance" 10 "10%" 11 "20%" 12 "30%" 13 "40%" 14 "50%" 15 "60%" 16 "70%" 17 "80%" 18 "90%" 19 "100%" 20 "Remote Ultra High" 21 "Remote Off road" 22 "Remote Normal" 23 "Remote sport" 24 "Ultra High" ;
VAL_ 802 ECASmodevld 0 "Valid" 1 "Invalid" ;
VAL_ 802 SusfaultlLamp 0 "idle" 1 "“亮黄灯”" 2 "“亮红灯”" ;
VAL_ 802 Susfaultred 0 "idle" 1 "压缩机温度过高，暂停使用" 2 "悬架运动已暂停，关闭车门后继续" 3 "当前车身姿态不稳，暂不能调节悬架高度（对应横向加速度过大）" 4 "Reserved" 5 "当前车身姿态不稳，暂不能调节悬架高度（对应静态路面不平）" 6 "方向盘转角转速过大，空簧停止调节" 7 "紧急状态，空簧停止调节" 8 "行驶路面颠簸，空簧停止调节" 9 "悬架热保护中，大概XX分钟后悬架可使用" 10 "悬架高度差过大，空簧停止调节 " 11 "悬架高度调节锁定中，请将车速提升至5km/h以上解除" 12 "空簧系统清洁中，请稍后再试”" 13 "请确认充放电枪已断开再试" 14 "Reserved" 15 "Reserved" 16 "悬架姿态恢复中，请谨慎行驶" ;
VAL_ 821 BCM_DriverWindowStatus 1 "Open" 2 "Close" 3 "Openning" 4 "Closing" 5 "AntiPinch 防夹回退状态" 255 "Invalid" ;
VAL_ 821 BCM_PartWinPosVIT 0 "Invalid" 255 "PosUnknown " ;
VAL_ 821 BCM_PartWinSts 0 "Init初始" 1 "RSV 保留" 2 "RSV 保留" 3 "Open 打开" 4 "Close 关闭" 5 "Stop 停止" ;
VAL_ 821 BCM_PassengerWindowPosi 0 "此参数无效" ;
VAL_ 821 BCM_PassengerWindowStatus 1 "Open" 2 "Close" 3 "Openning" 4 "Closing" 5 "AntiPinch 防夹回退状态" 255 "Invalid" ;
VAL_ 821 VcuIpuErrLamp 0 "OFF" 1 "ON" ;
VAL_ 821 VcuEgyMagtModResp 1 "模式1" 2 "模式2" 3 "模式3" 4 "模式4" ;
VAL_ 821 VcuForceEVModResp 0 "关闭" 1 "开启" ;
VAL_ 821 VcuForcePwrPresModResp 0 "关闭" 1 "开启" ;
VAL_ 821 BCM_RightRearWindowPosi 0 "此参数无效" ;
VAL_ 821 BCM_RightRearWindowStatus 1 "Open" 2 "Close" 3 "Openning" 4 "Closing" 5 "AntiPinch 防夹回退状态" 255 "Invalid" ;
VAL_ 821 VcuHvilStsGb 0 "noerror" 1 "error" ;
VAL_ 821 VcuVehChrgStsGb 1 "停车充电" 2 "行驶充电" 3 "未充电状态" 4 "充电完成" ;
VAL_ 821 VcuVehRunngModGb 1 "纯电" 2 "混动" 3 "燃油" ;
VAL_ 821 VcuVehStsGb 1 "车辆启动状态" 2 "熄火" 3 "其他状态" ;
VAL_ 821 VcuBrkPedlSts 0 "NotPressed" 1 "Pressed" 2 "Reserved" 3 "Error" ;
VAL_ 821 BCM_DriverWindowPosi 0 "此参数无效" ;
VAL_ 821 BCM_LeftRearWindowPosi 0 "此参数无效" ;
VAL_ 821 BCM_LeftRearWindowStatus 1 "Open" 2 "Close" 3 "Openning" 4 "Closing" 5 "AntiPinch 防夹回退状态" 255 "Invalid" ;
VAL_ 821 BcmSunroofPosi 0 "此参数无效" ;
VAL_ 821 BcmSunroofStatus 1 "Open" 2 "Close" 3 "Openning" 4 "Closing" 5 "AntiPinch 防夹回退状态" 127 "Invalid" ;
VAL_ 821 MFS_Right_switch_Right1_signal 0 "按键未按下" 1 "按键按下" 2 "假按键" 3 "Error" ;
VAL_ 821 VcuBattChrgErrLamp 0 "Off" 1 "ON" ;
VAL_ 821 VcuBattUUnderWarn 0 "Invalid" 1 "OFF" 2 "一级报警" 3 "二级报警" ;
VAL_ 821 VcuChrgAutoUnlckSetStsFb 0 "Invalid" 1 "off" 2 "on" ;
VAL_ 821 VcuChrgLckInfo 0 "无显示提示" 1 "锁止失败提示" 2 "解锁失败提示" ;
VAL_ 821 VCUGearShiftPositon 0 "Parking" 1 "Reverse" 2 "Neutral" 3 "D" 14 "Unreliable" 15 "Invalid" ;
VAL_ 821 VcuHvBattCutOffLamp 0 "LightOff" 1 "LightOn" ;
VAL_ 821 VcuHVErrInfo 0 "Noerror" 1 "Error" ;
VAL_ 821 VcuHvilSts 0 "noerror" 1 "error" ;
VAL_ 821 VcuShiftPErrInfo 0 "Noerror" 1 "Error" ;
VAL_ 821 VCUShiftPostionValid 0 "Valid" 1 "Invalid" ;
VAL_ 821 VcuVehErrInfo 0 "Noerror" 1 "Error" ;
VAL_ 821 VIUFL_DeviceVerifyResult 0 "VerifynotPassed" 1 "Verify Passed" 2 "Rsvrd" 3 "Rsvrd" ;
VAL_ 821 VcuOffRoadCrpSts 0 "Off" 1 "Standby" 2 "Active" 3 "Fault" ;
VAL_ 821 BCMALLDoorLockSwt 0 "无效值" 1 "解锁成功，整车以太网异常" 2 "解锁失败" 3 "闭锁成功，整车以太网异常" 4 "闭锁失败" ;
VAL_ 822 CcsmFrntEDLSetSwt 0 "None" 1 "请求解锁" 2 "请求锁止" 3 "Reserved" ;
VAL_ 822 CcsmReEDLSetSwt 0 "None" 1 "请求解锁" 2 "请求锁止" 3 "Reserved" ;
VAL_ 822 CcsmEDLBtnStuckFlg 0 "无故障" 1 "前锁按键粘连" 2 "后锁按键粘连" 3 "双锁按键粘连" ;
VAL_ 854 HU_FLHighSpeakerDelaySET 0 "invalid" 1 "0ms" 2 "0.5ms" 3 "1ms" 4 "1.5ms" 5 "2ms" ;
VAL_ 854 HU_FLHighSpeakerVolSET 0 "Step0" 1 "Step1" 20 "Step20" 31 "invalid" ;
VAL_ 854 HU_FLMidSpeakerDelaySET 0 "invalid" 1 "0ms" 2 "0.5ms" 3 "1ms" 4 "1.5ms" 5 "2ms" ;
VAL_ 854 HU_FLMidSpeakerVolSET 0 "Step0" 1 "Step1" 20 "Step20" 31 "invalid" ;
VAL_ 854 HU_FRHighSpeakerDelaySET 0 "invalid" 1 "0ms" 2 "0.5ms" 3 "1ms" 4 "1.5ms" 5 "2ms" ;
VAL_ 854 HU_FRHighSpeakerVolSET 0 "Step0" 1 "Step1" 20 "Step20" 31 "invalid" ;
VAL_ 854 HU_FRMidSpeakerDelaySET 0 "invalid" 1 "0ms" 2 "0.5ms" 3 "1ms" 4 "1.5ms" 5 "2ms" ;
VAL_ 854 HU_FRMidSpeakerVolSET 0 "Step0" 1 "Step1" 20 "Step20" 31 "invalid" ;
VAL_ 854 HUFLPositionDelaySET 0 "invalid" 1 "0ms" 2 "0.5ms" 3 "1ms" 4 "1.5ms" 5 "2ms" ;
VAL_ 854 HUFLPositionVolSET 0 "invalid" 1 "-3" 2 "-2" 3 "-1" 4 "0" 5 "1" 6 "2" 7 "3" ;
VAL_ 854 HUFRPositionDelaySET 0 "invalid" 1 "0ms" 2 "0.5ms" 3 "1ms" 4 "1.5ms" 5 "2ms" ;
VAL_ 854 HUFRPositionVolSET 0 "invalid" 1 "-3" 2 "-2" 3 "-1" 4 "0" 5 "1" 6 "2" 7 "3" ;
VAL_ 854 HU_AlarmVolSET 0 "invalid" 1 "低" 2 "中" 3 "高" ;
VAL_ 854 HU_AvasVolSET 0 "invalid" 1 "低" 2 "中" 3 "高" ;
VAL_ 854 HU_CenterSpeakerDelaySET 0 "invalid" 1 "0ms" 2 "0.5ms" 3 "1ms" 4 "1.5ms" 5 "2ms" ;
VAL_ 854 HU_CenterSpeakerVolSET 0 "Step0" 1 "Step1" 20 "Step20" 31 "invalid" ;
VAL_ 854 HU_CustomEffectSET 0 "Inactive" 1 "仅专业自定义频段设置生效（3段）" 2 "仅自定义频段设置生效（9段）" 3 "失效" 4 "自定义频段设置生效（7段）" 5 "Beososic" ;
VAL_ 854 HU_CustomEQ125SET 0 "invalid" 1 "-7" 2 "-6" 8 "0" 14 "6" 15 "7" ;
VAL_ 854 HU_CustomEQ16KSET 0 "invalid" 1 "-7" 2 "-6" 8 "0" 14 "6" 15 "7" ;
VAL_ 854 HU_CustomEQ1KSET 0 "invalid" 1 "-7" 2 "-6" 8 "0" 14 "6" 15 "7" ;
VAL_ 854 HU_CustomEQ250SET 0 "invalid" 1 "-7" 2 "-6" 8 "0" 14 "6" 15 "7" ;
VAL_ 854 HU_CustomEQ2KSET 0 "invalid" 1 "-7" 2 "-6" 8 "0" 14 "6" 15 "7" ;
VAL_ 854 HU_CustomEQ4KSET 0 "invalid" 1 "-7" 2 "-6" 8 "0" 14 "6" 15 "7" ;
VAL_ 854 HU_CustomEQ500SET 0 "invalid" 1 "-7" 2 "-6" 8 "0" 14 "6" 15 "7" ;
VAL_ 854 HU_CustomEQ62SET 0 "invalid" 1 "-7" 2 "-6" 8 "0" 14 "6" 15 "7" ;
VAL_ 854 HU_CustomEQ8KSET 0 "invalid" 1 "-7" 2 "-6" 8 "0" 14 "6" 15 "7" ;
VAL_ 854 HU_FLLowSpeakerDelaySET 0 "invalid" 1 "0ms" 2 "0.5ms" 3 "1ms" 4 "1.5ms" 5 "2ms" ;
VAL_ 854 HU_FLLowSpeakerVolSET 0 "Step0" 1 "Step1" 20 "Step20" 31 "invalid" ;
VAL_ 854 HU_FLMidHighSpeakerDelaySET 0 "invalid" 1 "0ms" 2 "0.5ms" 3 "1ms" 4 "1.5ms" 5 "2ms" ;
VAL_ 854 HU_FLMidHighSpeakerVolSET 0 "Step0" 1 "Step1" 20 "Step20" 31 "invalid" ;
VAL_ 854 HU_FLTopSpeakerDelaySET 0 "invalid" 1 "0ms" 2 "0.5ms" 3 "1ms" 4 "1.5ms" 5 "2ms" ;
VAL_ 854 HU_FLTopSpeakerVolSET 0 "Step0" 1 "Step1" 20 "Step20" 31 "invalid" ;
VAL_ 854 HU_FRBalanceSET 0 "Inactive" 1 "-7（最前面）" 2 "-6" 8 "0（中间位置）" 15 "7(最后边)" ;
VAL_ 854 HU_FRLowSpeakerDelaySET 0 "invalid" 1 "0ms" 2 "0.5ms" 3 "1ms" 4 "1.5ms" 5 "2ms" ;
VAL_ 854 HU_FRLowSpeakerVolSET 0 "Step0" 1 "Step1" 20 "Step20" 31 "invalid" ;
VAL_ 854 HU_FRMidHighSpeakerDelaySET 0 "invalid" 1 "0ms" 2 "0.5ms" 3 "1ms" 4 "1.5ms" 5 "2ms" ;
VAL_ 854 HU_FRMidHighSpeakerVolSET 0 "Step0" 1 "Step1" 20 "Step20" 31 "invalid" ;
VAL_ 854 HU_FRTopSpeakerDelaySET 0 "invalid" 1 "0ms" 2 "0.5ms" 3 "1ms" 4 "1.5ms" 5 "2ms" ;
VAL_ 854 HU_FRTopSpeakerVolSET 0 "Step0" 1 "Step1" 20 "Step20" 31 "invalid" ;
VAL_ 854 HU_KTVMUTESET 0 "invalid" 1 "静音" 2 "非静音" 3 "reserved" ;
VAL_ 854 HU_KTVVolSET 0 "Step0" 1 "Step1" 20 "Step20" 31 "invalid" ;
VAL_ 854 HU_LRBalanceSET 0 "Inactive" 1 "-7（最左边）" 2 "-6" 8 "0（中间位置）" 15 "7(最右边)" ;
VAL_ 854 HU_MediaMUTESET 0 "invalid" 1 "静音" 2 "非静音" 3 "reserved" ;
VAL_ 854 HU_MediaVolSET 0 "Step0" 1 "Step1" 20 "Step20" 31 "invalid" ;
VAL_ 854 HU_MUTESET 0 "invalid" 1 "静音" 2 "非静音" 3 "reserved" ;
VAL_ 854 HU_NaviMUTESET 0 "invalid" 1 "静音" 2 "非静音" 3 "reserved" ;
VAL_ 854 HU_NAVIVolSET 0 "Step0" 1 "Step1" 20 "Step20" 31 "invalid" ;
VAL_ 854 HU_OutMUTESET 0 "invalid" 1 "静音" 2 "非静音" 3 "reserved" ;
VAL_ 854 HU_OUTVolSET 0 "Step0" 1 "Step1" 20 "Step20" 31 "invalid" ;
VAL_ 854 HU_PerfessiionalEQ100SET 0 "invalid" 1 "-7" 2 "-6" 8 "0" 14 "6" 15 "7" ;
VAL_ 854 HU_PerfessiionalEQ500SET 0 "invalid" 1 "-7" 2 "-6" 8 "0" 14 "6" 15 "7" ;
VAL_ 854 HU_PerfessiionalEQ6KSET 0 "invalid" 1 "-7" 2 "-6" 8 "0" 14 "6" 15 "7" ;
VAL_ 854 HU_RLLowHighSpeakerDelaySET 0 "invalid" 1 "0ms" 2 "0.5ms" 3 "1ms" 4 "1.5ms" 5 "2ms" ;
VAL_ 854 HU_RLLowHighSpeakerVolSET 0 "Step0" 1 "Step1" 20 "Step20" 31 "invalid" ;
VAL_ 854 HU_RLSurroundSpeakerDelaySET 0 "invalid" 1 "0ms" 2 "0.5ms" 3 "1ms" 4 "1.5ms" 5 "2ms" ;
VAL_ 854 HU_RLSurroundSpeakerVolSET 0 "Step0" 1 "Step1" 20 "Step20" 31 "invalid" ;
VAL_ 854 HU_RLTopSpeakerDelaySET 0 "invalid" 1 "0ms" 2 "0.5ms" 3 "1ms" 4 "1.5ms" 5 "2ms" ;
VAL_ 854 HU_RLTopSpeakerVolSET 0 "Step0" 1 "Step1" 20 "Step20" 31 "invalid" ;
VAL_ 854 HU_RNCEnableSET 0 "invalid" 1 "开启" 2 "关闭" 3 "reserved" ;
VAL_ 854 HU_RRLowHighSpeakerDelaySET 0 "invalid" 1 "0ms" 2 "0.5ms" 3 "1ms" 4 "1.5ms" 5 "2ms" ;
VAL_ 854 HU_RRLowHighSpeakerVolSET 0 "Step0" 1 "Step1" 20 "Step20" 31 "invalid" ;
VAL_ 854 HU_RRSurroundSpeakerDelaySET 0 "invalid" 1 "0ms" 2 "0.5ms" 3 "1ms" 4 "1.5ms" 5 "2ms" ;
VAL_ 854 HU_RRSurroundSpeakerVolSET 0 "Step0" 1 "Step1" 20 "Step20" 31 "invalid" ;
VAL_ 854 HU_RRTopSpeakerDelaySET 0 "invalid" 1 "0ms" 2 "0.5ms" 3 "1ms" 4 "1.5ms" 5 "2ms" ;
VAL_ 854 HU_RRTopSpeakerVolSET 0 "Step0" 1 "Step1" 20 "Step20" 31 "invalid" ;
VAL_ 854 HU_SoundEffectSET 0 "invalid" 1 "音效1（HIFI原声）" 2 "音效2（沉浸环绕）" 3 "音效3（预留）" 4 "音效4（交响乐厅）" 5 "音效5（预留）" 6 "音效6（露营嗨唱）" 7 "音效7" 8 "音效8" 9 "音效9" 10 "音效10" 11 "音效11（寰宇影院）" 12 "音效12（调音大师）" ;
VAL_ 854 HU_SoundFieldSET 0 "invalid" 1 "自定义（CX810无）" 2 "主驾模式" 3 "均衡模式（全车模式）" 4 "左后模式" 5 "右后模式" 6 "副驾模式" ;
VAL_ 854 HU_SubSpeakerDelaySET 0 "invalid" 1 "0ms" 2 "0.5ms" 3 "1ms" 4 "1.5ms" 5 "2ms" ;
VAL_ 854 HU_SubSpeakerVolSET 0 "Step0" 1 "Step1" 20 "Step20" 31 "invalid" ;
VAL_ 854 HU_SystemMUTESET 0 "invalid" 1 "静音" 2 "非静音" 3 "reserved" ;
VAL_ 854 HU_SystemVolSET 0 "Step0" 1 "Step1" 20 "Step20" 31 "invalid" ;
VAL_ 854 HU_TelBcallMUTESET 0 "invalid" 1 "静音" 2 "非静音" 3 "reserved" ;
VAL_ 854 HU_TELBCALLVolSET 0 "Step0" 1 "Step1" 20 "Step20" 31 "invalid" ;
VAL_ 854 HU_TTSVRMUTESET 0 "invalid" 1 "静音" 2 "非静音" 3 "reserved" ;
VAL_ 854 HU_TTSVRVolSET 0 "Step0" 1 "Step1" 20 "Step20" 31 "invalid" ;
VAL_ 854 HU_TurnLightInOrOutSET 0 "invalid" 1 "in" 2 "out" ;
VAL_ 854 HU_TurnLightVolSET 0 "Inactive" 1 "低" 2 "中" 3 "高" ;
VAL_ 854 HU_VOLSpeedLevEnableSET 0 "invalid" 1 "关闭" 2 "打开" 3 "=reserved" ;
VAL_ 854 HUBeosonicModeSet 0 "invalid" 1 "Lounge" 2 "Party" 3 "Podcast" 4 "Custom" ;
VAL_ 854 HUBeosonicXSet 0 "invalid" 1 "-10" 2 "-9" 11 "0" 20 "9" 21 "10" ;
VAL_ 854 HUBeosonicYSet 0 "invalid" 1 "-10" 2 "-9" 11 "0" 20 "9" 21 "10" ;
VAL_ 854 HUCenterPositionDelaySET 0 "invalid" 1 "0ms" 2 "0.5ms" 3 "1ms" 4 "1.5ms" 5 "2ms" ;
VAL_ 854 HUCenterPositionVolSET 0 "invalid" 1 "-3" 2 "-2" 3 "-1" 4 "0" 5 "1" 6 "2" 7 "3" ;
VAL_ 854 HUCustomEQ2500SET 0 "invalid" 1 "-7" 2 "-6" 8 "0" 14 "6" 15 "7" ;
VAL_ 854 HUCustomEQ315SET 0 "invalid" 1 "-7" 2 "-6" 8 "0" 14 "6" 15 "7" ;
VAL_ 854 HUCustomEQ50SET 0 "invalid" 1 "-7" 2 "-6" 8 "0" 14 "6" 15 "7" ;
VAL_ 854 HUCustomEQ6000SET 0 "invalid" 1 "-7" 2 "-6" 8 "0" 14 "6" 15 "7" ;
VAL_ 854 HUCustomEQ800SET 0 "invalid" 1 "-7" 2 "-6" 8 "0" 14 "6" 15 "7" ;
VAL_ 854 HUFLTopPositionDelaySET 0 "invalid" 1 "0ms" 2 "0.5ms" 3 "1ms" 4 "1.5ms" 5 "2ms" ;
VAL_ 854 HUFLTopPositionVolSET 0 "invalid" 1 "-3" 2 "-2" 3 "-1" 4 "0" 5 "1" 6 "2" 7 "3" ;
VAL_ 854 HUFRTopPositionDelaySET 0 "invalid" 1 "0ms" 2 "0.5ms" 3 "1ms" 4 "1.5ms" 5 "2ms" ;
VAL_ 854 HUSoundSourceType 0 "invalid" 1 "立体声" 2 "7.1.4" 3 "reserved" ;
VAL_ 854 HUTMCenterPositionEQ15000HzSet 0 "invalid" 1 "-3" 2 "-2" 3 "-1" 4 "0" 5 "1" 6 "2" 7 "3" ;
VAL_ 854 HUTMCenterPositionEQ800HzSet 0 "invalid" 1 "-3" 2 "-2" 3 "-1" 4 "0" 5 "1" 6 "2" 7 "3" ;
VAL_ 854 HUTMFLPositionEQ100HzSet 0 "invalid" 1 "-3" 2 "-2" 3 "-1" 4 "0" 5 "1" 6 "2" 7 "3" ;
VAL_ 854 HUTMFLPositionEQ15000HzSet 0 "invalid" 1 "-3" 2 "-2" 3 "-1" 4 "0" 5 "1" 6 "2" 7 "3" ;
VAL_ 854 HUTMFLPositionEQ800HzSet 0 "invalid" 1 "-3" 2 "-2" 3 "-1" 4 "0" 5 "1" 6 "2" 7 "3" ;
VAL_ 854 HUTMFLTopPositionEQ500HzSet 0 "invalid" 1 "-3" 2 "-2" 3 "-1" 4 "0" 5 "1" 6 "2" 7 "3" ;
VAL_ 854 HUTMFRPositionEQ100HzSet 0 "invalid" 1 "-3" 2 "-2" 3 "-1" 4 "0" 5 "1" 6 "2" 7 "3" ;
VAL_ 854 HUTMFRPositionEQ15000HzSet 0 "invalid" 1 "-3" 2 "-2" 3 "-1" 4 "0" 5 "1" 6 "2" 7 "3" ;
VAL_ 854 HUTMFRPositionEQ800HzSet 0 "invalid" 1 "-3" 2 "-2" 3 "-1" 4 "0" 5 "1" 6 "2" 7 "3" ;
VAL_ 854 HUTMFRTopPositionEQ500HzSet 0 "invalid" 1 "-3" 2 "-2" 3 "-1" 4 "0" 5 "1" 6 "2" 7 "3" ;
VAL_ 854 HUTMReverbSet 0 "invalid" 1 "1" 2 "2" 3 "3" 100 "100" ;
VAL_ 854 HUTMRLPositionEQ10000HzSet 0 "invalid" 1 "-3" 2 "-2" 3 "-1" 4 "0" 5 "1" 6 "2" 7 "3" ;
VAL_ 854 HUTMRLPositionEQ100HzSet 0 "invalid" 1 "-3" 2 "-2" 3 "-1" 4 "0" 5 "1" 6 "2" 7 "3" ;
VAL_ 854 HUTMRLSurroundPositionEQ15000HzS 0 "invalid" 1 "-3" 2 "-2" 3 "-1" 4 "0" 5 "1" 6 "2" 7 "3" ;
VAL_ 854 HUTMRLSurroundPositionEQ800HzSet 0 "invalid" 1 "-3" 2 "-2" 3 "-1" 4 "0" 5 "1" 6 "2" 7 "3" ;
VAL_ 854 HUTMRLTopPositionEQ500HzSet 0 "invalid" 1 "-3" 2 "-2" 3 "-1" 4 "0" 5 "1" 6 "2" 7 "3" ;
VAL_ 854 HUTMRRPositionEQ10000HzSet 0 "invalid" 1 "-3" 2 "-2" 3 "-1" 4 "0" 5 "1" 6 "2" 7 "3" ;
VAL_ 854 HUTMRRPositionEQ100HzSet 0 "invalid" 1 "-3" 2 "-2" 3 "-1" 4 "0" 5 "1" 6 "2" 7 "3" ;
VAL_ 854 HUTMRRSurroundPositionEQ15000HzS 0 "invalid" 1 "-3" 2 "-2" 3 "-1" 4 "0" 5 "1" 6 "2" 7 "3" ;
VAL_ 854 HUTMRRSurroundPositionEQ800HzSet 0 "invalid" 1 "-3" 2 "-2" 3 "-1" 4 "0" 5 "1" 6 "2" 7 "3" ;
VAL_ 854 HUTMRRTopPositionEQ500HzSet 0 "invalid" 1 "-3" 2 "-2" 3 "-1" 4 "0" 5 "1" 6 "2" 7 "3" ;
VAL_ 854 HUTMSubPositionEQ30HzSet 0 "invalid" 1 "-3" 2 "-2" 3 "-1" 4 "0" 5 "1" 6 "2" 7 "3" ;
VAL_ 854 HUTMTransEnd 0 "未发送" 1 "发送完成" ;
VAL_ 854 HUVOLSpeedLevChangeSET 0 "invalid" 1 "关闭" 2 "低" 3 "中" 4 "高" ;
VAL_ 868 CdcEpbSetSwt_1 0 "norequest" 1 "apply" 2 "Release" 3 "Reserved" ;

BA_DEF_ BO_ "GenMsgCycleTime" INT 0 65535;
BA_ "GenMsgCycleTime" BO_ 80 500;
BA_ "GenMsgCycleTime" BO_ 81 500;
BA_ "GenMsgCycleTime" BO_ 338 10;
BA_ "GenMsgCycleTime" BO_ 346 10;
BA_ "GenMsgCycleTime" BO_ 349 10;
BA_ "GenMsgCycleTime" BO_ 353 10;
BA_ "GenMsgCycleTime" BO_ 355 10;
BA_ "GenMsgCycleTime" BO_ 359 10;
BA_ "GenMsgCycleTime" BO_ 378 10;
BA_ "GenMsgCycleTime" BO_ 384 10;
BA_ "GenMsgCycleTime" BO_ 417 10;
BA_ "GenMsgCycleTime" BO_ 419 10;
BA_ "GenMsgCycleTime" BO_ 420 10;
BA_ "GenMsgCycleTime" BO_ 421 10;
BA_ "GenMsgCycleTime" BO_ 433 10;
BA_ "GenMsgCycleTime" BO_ 450 10;
BA_ "GenMsgCycleTime" BO_ 452 10;
BA_ "GenMsgCycleTime" BO_ 453 10;
BA_ "GenMsgCycleTime" BO_ 467 10;
BA_ "GenMsgCycleTime" BO_ 500 50;
BA_ "GenMsgCycleTime" BO_ 513 50;
BA_ "GenMsgCycleTime" BO_ 642 100;
BA_ "GenMsgCycleTime" BO_ 648 40;
BA_ "GenMsgCycleTime" BO_ 674 50;
BA_ "GenMsgCycleTime" BO_ 677 100;
BA_ "GenMsgCycleTime" BO_ 680 100;
BA_ "GenMsgCycleTime" BO_ 681 100;
BA_ "GenMsgCycleTime" BO_ 689 40;
BA_ "GenMsgCycleTime" BO_ 690 100;
BA_ "GenMsgCycleTime" BO_ 699 50;
BA_ "GenMsgCycleTime" BO_ 722 100;
BA_ "GenMsgCycleTime" BO_ 753 50;
BA_ "GenMsgCycleTime" BO_ 759 1000;
BA_ "GenMsgCycleTime" BO_ 760 1000;
BA_ "GenMsgCycleTime" BO_ 774 100;
BA_ "GenMsgCycleTime" BO_ 779 100;
BA_ "GenMsgCycleTime" BO_ 784 100;
BA_ "GenMsgCycleTime" BO_ 800 100;
BA_ "GenMsgCycleTime" BO_ 802 100;
BA_ "GenMsgCycleTime" BO_ 821 100;
BA_ "GenMsgCycleTime" BO_ 822 100;
BA_ "GenMsgCycleTime" BO_ 854 100;
BA_ "GenMsgCycleTime" BO_ 868 100;
